VERSION ""

NS_ :

BS_:

BU_: PFAF_HS LVMPC_HS DCDC_HS AMP_HS VICM2_HS FICM_HS ARS_HS MCP_B_HS MCP_A_HS ICCM_OBD_HS SAS_HS ACCM_HS VLBS_HS EBCM_OBD_HS EDI_HS HPCC_HS VITM_OBD_HS PTAM_HS OBCM_HS VICM_HS HCP_HS FDCM_HS APPS_HS ICCM_HS EOCM_F_HS GPCM_HS FSCM_ITBC_HS SCM_HS ITBC_HS VCM_HS HMIM_HS FCP_HS VES_HS Dummy_HS MCP_C_HS RWS_HS ONSTAR_HS EPS_HS TestTool_HS MCP_HS BCP_HS ALC_HS AHL_AFL_HS SADS_HS EPB_HS FSCM_HS AFS_HS FCM_HS TCCM_HS RDCM_HS PTO_HS PCM_HS EBCM_HS ACC_HS BCM_HS TCM_HS ECM_HS

BO_ 1917 DTC_Triggered_77D: 7 EPB_HS
  SG_ DTCI_DTCFaultType_77D: 55|8@0+ (1,0) [0|255] "" HMIM_HS FCP_HS ONSTAR_HS
  SG_ DTCI_CodeSupported_77D: 40|1@0+ (1,0) [0|1] "" HMIM_HS FCP_HS ONSTAR_HS
  SG_ DTCI_CurrentStatus_77D: 41|1@0+ (1,0) [0|1] "" HMIM_HS FCP_HS ONSTAR_HS
  SG_ DTCI_TstNPsdCdClrdSt_77D: 42|1@0+ (1,0) [0|1] "" HMIM_HS FCP_HS ONSTAR_HS
  SG_ DTCI_TstFldCdClrdStat_77D: 43|1@0+ (1,0) [0|1] "" HMIM_HS FCP_HS ONSTAR_HS
  SG_ DTCI_HistStat_77D: 44|1@0+ (1,0) [0|1] "" HMIM_HS FCP_HS ONSTAR_HS
  SG_ DTCI_TstNPsdPwrUpSt_77D: 45|1@0+ (1,0) [0|1] "" HMIM_HS FCP_HS ONSTAR_HS
  SG_ DTCI_TstFldPwrUpSt_77D: 46|1@0+ (1,0) [0|1] "" HMIM_HS FCP_HS ONSTAR_HS
  SG_ DTCI_WrnIndRqdSt_77D: 47|1@0+ (1,0) [0|1] "" HMIM_HS FCP_HS ONSTAR_HS
  SG_ DTCI_DTCFailType_77D: 39|8@0+ (1,0) [0|255] "" HMIM_HS FCP_HS ONSTAR_HS
  SG_ DTCI_DTCNumber_77D: 23|16@0+ (1,0) [0|65535] "" HMIM_HS FCP_HS ONSTAR_HS
  SG_ DTCI_DTCSource_77D: 15|8@0+ (1,0) [0|255] "" HMIM_HS FCP_HS ONSTAR_HS
  SG_ DTCI_DTCTriggered_77D: 0|1@0+ (1,0) [0|1] "" HMIM_HS FCP_HS ONSTAR_HS
  SG_ DTCIUnused7_77D: 1|1@0+ (1,0) [0|1] "" HMIM_HS FCP_HS ONSTAR_HS
  SG_ DTCIUnused6_77D: 2|1@0+ (1,0) [0|1] "" HMIM_HS FCP_HS ONSTAR_HS
  SG_ DTCIUnused5_77D: 3|1@0+ (1,0) [0|1] "" HMIM_HS FCP_HS ONSTAR_HS
  SG_ DTCIUnused4_77D: 4|1@0+ (1,0) [0|1] "" HMIM_HS FCP_HS ONSTAR_HS
  SG_ DTCIUnused3_77D: 5|1@0+ (1,0) [0|1] "" HMIM_HS FCP_HS ONSTAR_HS
  SG_ DTCIUnused2_77D: 6|1@0+ (1,0) [0|1] "" HMIM_HS FCP_HS ONSTAR_HS
  SG_ DTCIUnused1_77D: 7|1@0+ (1,0) [0|1] "" HMIM_HS FCP_HS ONSTAR_HS

BO_ 1918 DTC_Triggered_77E: 7 SADS_HS
  SG_ DTCI_DTCFaultType_77E: 55|8@0+ (1,0) [0|255] "" HMIM_HS FCP_HS ONSTAR_HS
  SG_ DTCI_CodeSupported_77E: 40|1@0+ (1,0) [0|1] "" HMIM_HS FCP_HS ONSTAR_HS
  SG_ DTCI_CurrentStatus_77E: 41|1@0+ (1,0) [0|1] "" HMIM_HS FCP_HS ONSTAR_HS
  SG_ DTCI_TstNPsdCdClrdSt_77E: 42|1@0+ (1,0) [0|1] "" HMIM_HS FCP_HS ONSTAR_HS
  SG_ DTCI_TstFldCdClrdStat_77E: 43|1@0+ (1,0) [0|1] "" HMIM_HS FCP_HS ONSTAR_HS
  SG_ DTCI_HistStat_77E: 44|1@0+ (1,0) [0|1] "" HMIM_HS FCP_HS ONSTAR_HS
  SG_ DTCI_TstNPsdPwrUpSt_77E: 45|1@0+ (1,0) [0|1] "" HMIM_HS FCP_HS ONSTAR_HS
  SG_ DTCI_TstFldPwrUpSt_77E: 46|1@0+ (1,0) [0|1] "" HMIM_HS FCP_HS ONSTAR_HS
  SG_ DTCI_WrnIndRqdSt_77E: 47|1@0+ (1,0) [0|1] "" HMIM_HS FCP_HS ONSTAR_HS
  SG_ DTCI_DTCFailType_77E: 39|8@0+ (1,0) [0|255] "" HMIM_HS FCP_HS ONSTAR_HS
  SG_ DTCI_DTCNumber_77E: 23|16@0+ (1,0) [0|65535] "" HMIM_HS FCP_HS ONSTAR_HS
  SG_ DTCI_DTCSource_77E: 15|8@0+ (1,0) [0|255] "" HMIM_HS FCP_HS ONSTAR_HS
  SG_ DTCI_DTCTriggered_77E: 0|1@0+ (1,0) [0|1] "" HMIM_HS FCP_HS ONSTAR_HS
  SG_ DTCIUnused7_77E: 1|1@0+ (1,0) [0|1] "" HMIM_HS FCP_HS ONSTAR_HS
  SG_ DTCIUnused6_77E: 2|1@0+ (1,0) [0|1] "" HMIM_HS FCP_HS ONSTAR_HS
  SG_ DTCIUnused5_77E: 3|1@0+ (1,0) [0|1] "" HMIM_HS FCP_HS ONSTAR_HS
  SG_ DTCIUnused4_77E: 4|1@0+ (1,0) [0|1] "" HMIM_HS FCP_HS ONSTAR_HS
  SG_ DTCIUnused3_77E: 5|1@0+ (1,0) [0|1] "" HMIM_HS FCP_HS ONSTAR_HS
  SG_ DTCIUnused2_77E: 6|1@0+ (1,0) [0|1] "" HMIM_HS FCP_HS ONSTAR_HS
  SG_ DTCIUnused1_77E: 7|1@0+ (1,0) [0|1] "" HMIM_HS FCP_HS ONSTAR_HS

BO_ 1919 DTC_Triggered_77F: 7 TCM_HS
  SG_ DTCI_DTCFaultType_77F: 55|8@0+ (1,0) [0|255] "" HMIM_HS FCP_HS ONSTAR_HS
  SG_ DTCI_CodeSupported_77F: 40|1@0+ (1,0) [0|1] "" HMIM_HS FCP_HS ONSTAR_HS
  SG_ DTCI_CurrentStatus_77F: 41|1@0+ (1,0) [0|1] "" HMIM_HS FCP_HS ONSTAR_HS
  SG_ DTCI_TstNPsdCdClrdSt_77F: 42|1@0+ (1,0) [0|1] "" HMIM_HS FCP_HS ONSTAR_HS
  SG_ DTCI_TstFldCdClrdStat_77F: 43|1@0+ (1,0) [0|1] "" HMIM_HS FCP_HS ONSTAR_HS
  SG_ DTCI_HistStat_77F: 44|1@0+ (1,0) [0|1] "" HMIM_HS FCP_HS ONSTAR_HS
  SG_ DTCI_TstNPsdPwrUpSt_77F: 45|1@0+ (1,0) [0|1] "" HMIM_HS FCP_HS ONSTAR_HS
  SG_ DTCI_TstFldPwrUpSt_77F: 46|1@0+ (1,0) [0|1] "" HMIM_HS FCP_HS ONSTAR_HS
  SG_ DTCI_WrnIndRqdSt_77F: 47|1@0+ (1,0) [0|1] "" HMIM_HS FCP_HS ONSTAR_HS
  SG_ DTCI_DTCFailType_77F: 39|8@0+ (1,0) [0|255] "" HMIM_HS FCP_HS ONSTAR_HS
  SG_ DTCI_DTCNumber_77F: 23|16@0+ (1,0) [0|65535] "" HMIM_HS FCP_HS ONSTAR_HS
  SG_ DTCI_DTCSource_77F: 15|8@0+ (1,0) [0|255] "" HMIM_HS FCP_HS ONSTAR_HS
  SG_ DTCI_DTCTriggered_77F: 0|1@0+ (1,0) [0|1] "" HMIM_HS FCP_HS ONSTAR_HS
  SG_ DTCIUnused7_77F: 1|1@0+ (1,0) [0|1] "" HMIM_HS FCP_HS ONSTAR_HS
  SG_ DTCIUnused6_77F: 2|1@0+ (1,0) [0|1] "" HMIM_HS FCP_HS ONSTAR_HS
  SG_ DTCIUnused5_77F: 3|1@0+ (1,0) [0|1] "" HMIM_HS FCP_HS ONSTAR_HS
  SG_ DTCIUnused4_77F: 4|1@0+ (1,0) [0|1] "" HMIM_HS FCP_HS ONSTAR_HS
  SG_ DTCIUnused3_77F: 5|1@0+ (1,0) [0|1] "" HMIM_HS FCP_HS ONSTAR_HS
  SG_ DTCIUnused2_77F: 6|1@0+ (1,0) [0|1] "" HMIM_HS FCP_HS ONSTAR_HS
  SG_ DTCIUnused1_77F: 7|1@0+ (1,0) [0|1] "" HMIM_HS FCP_HS ONSTAR_HS

BO_ 589 USDT_Req_to_ONS_HS: 8 TestTool_HS
  SG_ DgnInf: 7|64@0+ (1,0) [0|1.8446742e+19] "" FCP_HS ONSTAR_HS

BO_ 1357 UUDT_Resp_From_ONS_HS: 8 ONSTAR_HS
  SG_ DgnInf_HS54D: 7|64@0+ (1,0) [0|1.8446742e+19] "" TestTool_HS

BO_ 1613 USDT_Resp_From_ONS_HS: 8 ONSTAR_HS
  SG_ DgnInf: 7|64@0+ (1,0) [0|1.8446742e+19] "" TestTool_HS

BO_ 1606 USDT_Resp_From_APPS_HS: 8 APPS_HS
  SG_ DgnInf: 7|64@0+ (1,0) [0|1.8446742e+19] "" FCP_HS ONSTAR_HS TestTool_HS

BO_ 582 USDT_Req_to_APPS_HS: 8 TestTool_HS
  SG_ DgnInf: 7|64@0+ (1,0) [0|1.8446742e+19] "" APPS_HS

BO_ 590 USDT_Req_to_SADS_HS: 8 TestTool_HS
  SG_ DgnInf: 7|64@0+ (1,0) [0|1.8446742e+19] "" SADS_HS

BO_ 601 USDT_Req_to_MCP_C_HS: 8 TestTool_HS
  SG_ DgnInf: 7|64@0+ (1,0) [0|1.8446742e+19] "" MCP_C_HS

BO_ 1369 UUDT_Resp_From_MCP_C_HS: 8 MCP_C_HS
  SG_ DgnInf_HS559: 7|64@0+ (1,0) [0|1.8446742e+19] "" FCP_HS ONSTAR_HS TestTool_HS

BO_ 1625 USDT_Resp_From_MCP_C_HS: 8 MCP_C_HS
  SG_ DgnInf: 7|64@0+ (1,0) [0|1.8446742e+19] "" FCP_HS ONSTAR_HS TestTool_HS

BO_ 1356 UUDT_Resp_From_PFAF_HS: 8 PFAF_HS
  SG_ DgnInf_HS54C: 7|64@0+ (1,0) [0|1.8446742e+19] "" FCP_HS ONSTAR_HS TestTool_HS

BO_ 1358 UUDT_Resp_From_SADS_HS: 8 SADS_HS
  SG_ DgnInf_HS54E: 7|64@0+ (1,0) [0|1.8446742e+19] "" FCP_HS ONSTAR_HS TestTool_HS

BO_ 1359 UUDT_Resp_From_RDCM_HS: 8 RDCM_HS
  SG_ DgnInf_HS54F: 7|64@0+ (1,0) [0|1.8446742e+19] "" FCP_HS ONSTAR_HS TestTool_HS

BO_ 2023 USDT_Req_to_VITM_HS: 8 TestTool_HS
  SG_ DgnInf: 7|64@0+ (1,0) [0|1.8446742e+19] "" VITM_OBD_HS

BO_ 2021 USDT_Req_to_OBD_Device5: 8 TestTool_HS
  SG_ DgnInf: 7|64@0+ (1,0) [0|1.8446742e+19] "" EBCM_OBD_HS

BO_ 2017 USDT_Req_to_BCP_HS: 8 TestTool_HS
  SG_ DgnInf: 7|64@0+ (1,0) [0|1.8446742e+19] "" HCP_HS BCP_HS

BO_ 2019 USDT_Req_to_FSCM_HS: 8 TestTool_HS
  SG_ DgnInf: 7|64@0+ (1,0) [0|1.8446742e+19] "" ICCM_OBD_HS FSCM_ITBC_HS FSCM_HS

BO_ 585 USDT_Req_to_AFL_AHL_HS: 8 TestTool_HS
  SG_ DgnInf: 7|64@0+ (1,0) [0|1.8446742e+19] "" AHL_AFL_HS

BO_ 578 USDT_Req_to_EHPS_EPS_HS: 8 TestTool_HS
  SG_ DgnInf: 7|64@0+ (1,0) [0|1.8446742e+19] "" VES_HS EPS_HS

BO_ 2022 USDT_Req_to_OBD_Device6: 8 TestTool_HS
  SG_ DgnInf: 7|64@0+ (1,0) [0|1.8446742e+19] "" FICM_HS GPCM_HS VICM2_HS

BO_ 584 USDT_Req_to_Free_48_HS: 8 TestTool_HS
  SG_ DgnInf: 7|64@0+ (1,0) [0|1.8446742e+19] "" Dummy_HS

BO_ 591 USDT_Req_to_RDCM_HS: 8 TestTool_HS
  SG_ DgnInf: 7|64@0+ (1,0) [0|1.8446742e+19] "" RDCM_HS

BO_ 581 USDT_Req_to_ALC_HS: 8 TestTool_HS
  SG_ DgnInf: 7|64@0+ (1,0) [0|1.8446742e+19] "" ALC_HS

BO_ 586 USDT_Req_to_SAS_HS: 8 TestTool_HS
  SG_ DgnInf: 7|64@0+ (1,0) [0|1.8446742e+19] "" SAS_HS

BO_ 588 USDT_Req_to_PFAF_HS: 8 TestTool_HS
  SG_ DgnInf: 7|64@0+ (1,0) [0|1.8446742e+19] "" PFAF_HS

BO_ 580 USDT_Req_to_OBCM_HS: 8 TestTool_HS
  SG_ DgnInf: 7|64@0+ (1,0) [0|1.8446742e+19] "" DCDC_HS OBCM_HS

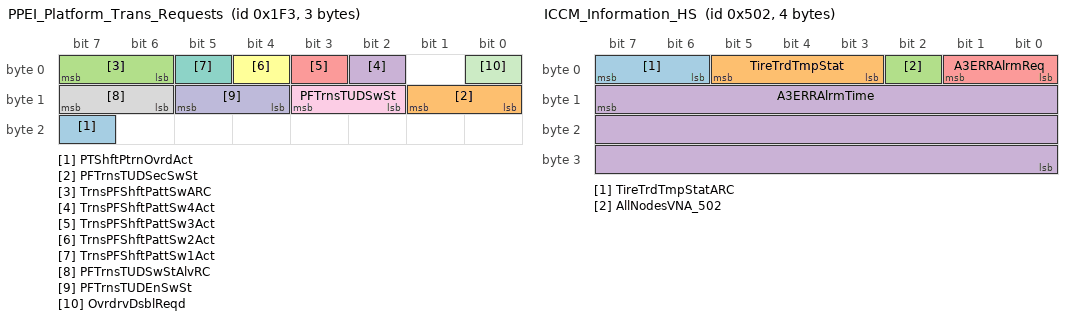
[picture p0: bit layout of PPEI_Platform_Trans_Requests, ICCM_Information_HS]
BO_ 499 PPEI_Platform_Trans_Requests: 3 BCM_HS
  SG_ PTShftPtrnOvrdAct: 23|1@0+ (1,0) [0|1] "" TCM_HS
  SG_ PFTrnsTUDSecSwSt: 9|2@0+ (1,0) [0|3] "" TCM_HS
  SG_ TrnsPFShftPattSwARC: 7|2@0+ (1,0) [0|3] "" PCM_HS ECM_HS TCM_HS
  SG_ TrnsPFShftPattSw4Act: 2|1@0+ (1,0) [0|1] "" PCM_HS ECM_HS TCM_HS
  SG_ TrnsPFShftPattSw3Act: 3|1@0+ (1,0) [0|1] "" PCM_HS ECM_HS TCM_HS
  SG_ TrnsPFShftPattSw2Act: 4|1@0+ (1,0) [0|1] "" PCM_HS ECM_HS TCM_HS
  SG_ TrnsPFShftPattSw1Act: 5|1@0+ (1,0) [0|1] "" PCM_HS ECM_HS TCM_HS
  SG_ PFTrnsTUDSwStAlvRC: 15|2@0+ (1,0) [0|3] "" TCM_HS
  SG_ PFTrnsTUDSwSt: 11|2@0+ (1,0) [0|3] "" TCM_HS
  SG_ PFTrnsTUDEnSwSt: 13|2@0+ (1,0) [0|3] "" TCM_HS
  SG_ OvrdrvDsblReqd: 0|1@0+ (1,0) [0|1] "" Vector__XXX

BO_ 1282 ICCM_Information_HS: 4 ALC_HS
  SG_ TireTrdTmpStatARC: 7|2@0+ (1,0) [0|3] "" EBCM_OBD_HS EBCM_HS
  SG_ TireTrdTmpStat: 5|3@0+ (1,0) [0|7] "" BCM_HS EBCM_OBD_HS EBCM_HS
  SG_ AllNodesVNA_502: 2|1@0+ (1,0) [0|1] "" BCM_HS
  SG_ A3ERRAlrmTime: 15|24@0+ (1,0) [0|16777215] "min" BCM_HS
  SG_ A3ERRAlrmReq: 1|2@0+ (1,0) [0|3] "" BCM_HS

BO_ 1360 UUDT_Resp_From_PTAM_HS: 8 PTAM_HS
  SG_ DgnInf_HS550: 7|64@0+ (1,0) [0|1.8446742e+19] "" FCP_HS ONSTAR_HS TestTool_HS

BO_ 1616 USDT_Resp_From_PTAM_HS: 8 PTAM_HS
  SG_ DgnInf: 7|64@0+ (1,0) [0|1.8446742e+19] "" FCP_HS ONSTAR_HS TestTool_HS

BO_ 1921 DTC_Triggered_781: 7 Dummy_HS
  SG_ DTCI_CurrentStatus_781: 41|1@0+ (1,0) [0|1] "" HMIM_HS FCP_HS ONSTAR_HS
  SG_ DTCI_WrnIndRqdSt_781: 47|1@0+ (1,0) [0|1] "" HMIM_HS FCP_HS ONSTAR_HS
  SG_ DTCIUnused7_781: 1|1@0+ (1,0) [0|1] "" HMIM_HS FCP_HS ONSTAR_HS
  SG_ DTCIUnused6_781: 2|1@0+ (1,0) [0|1] "" HMIM_HS FCP_HS ONSTAR_HS
  SG_ DTCIUnused5_781: 3|1@0+ (1,0) [0|1] "" HMIM_HS FCP_HS ONSTAR_HS
  SG_ DTCIUnused4_781: 4|1@0+ (1,0) [0|1] "" HMIM_HS FCP_HS ONSTAR_HS
  SG_ DTCIUnused3_781: 5|1@0+ (1,0) [0|1] "" HMIM_HS FCP_HS ONSTAR_HS
  SG_ DTCIUnused2_781: 6|1@0+ (1,0) [0|1] "" HMIM_HS FCP_HS ONSTAR_HS
  SG_ DTCIUnused1_781: 7|1@0+ (1,0) [0|1] "" HMIM_HS FCP_HS ONSTAR_HS
  SG_ DTCI_TstNPsdPwrUpSt_781: 45|1@0+ (1,0) [0|1] "" HMIM_HS FCP_HS ONSTAR_HS
  SG_ DTCI_TstNPsdCdClrdSt_781: 42|1@0+ (1,0) [0|1] "" HMIM_HS FCP_HS ONSTAR_HS
  SG_ DTCI_TstFldPwrUpSt_781: 46|1@0+ (1,0) [0|1] "" HMIM_HS FCP_HS ONSTAR_HS
  SG_ DTCI_TstFldCdClrdStat_781: 43|1@0+ (1,0) [0|1] "" HMIM_HS FCP_HS ONSTAR_HS
  SG_ DTCI_HistStat_781: 44|1@0+ (1,0) [0|1] "" HMIM_HS FCP_HS ONSTAR_HS
  SG_ DTCI_DTCTriggered_781: 0|1@0+ (1,0) [0|1] "" HMIM_HS FCP_HS ONSTAR_HS
  SG_ DTCI_DTCSource_781: 15|8@0+ (1,0) [0|255] "" HMIM_HS FCP_HS ONSTAR_HS
  SG_ DTCI_DTCNumber_781: 23|16@0+ (1,0) [0|65535] "" HMIM_HS FCP_HS ONSTAR_HS
  SG_ DTCI_DTCFaultType_781: 55|8@0+ (1,0) [0|255] "" HMIM_HS FCP_HS ONSTAR_HS
  SG_ DTCI_DTCFailType_781: 39|8@0+ (1,0) [0|255] "" HMIM_HS FCP_HS ONSTAR_HS
  SG_ DTCI_CodeSupported_781: 40|1@0+ (1,0) [0|1] "" HMIM_HS FCP_HS ONSTAR_HS

BO_ 1920 DTC_Triggered_780: 7 EBCM_HS
  SG_ DTCI_CurrentStatus_780: 41|1@0+ (1,0) [0|1] "" HMIM_HS FCP_HS ONSTAR_HS
  SG_ DTCI_WrnIndRqdSt_780: 47|1@0+ (1,0) [0|1] "" HMIM_HS FCP_HS ONSTAR_HS
  SG_ DTCIUnused7_780: 1|1@0+ (1,0) [0|1] "" HMIM_HS FCP_HS ONSTAR_HS
  SG_ DTCIUnused6_780: 2|1@0+ (1,0) [0|1] "" HMIM_HS FCP_HS ONSTAR_HS
  SG_ DTCIUnused5_780: 3|1@0+ (1,0) [0|1] "" HMIM_HS FCP_HS ONSTAR_HS
  SG_ DTCIUnused4_780: 4|1@0+ (1,0) [0|1] "" HMIM_HS FCP_HS ONSTAR_HS
  SG_ DTCIUnused3_780: 5|1@0+ (1,0) [0|1] "" HMIM_HS FCP_HS ONSTAR_HS
  SG_ DTCIUnused2_780: 6|1@0+ (1,0) [0|1] "" HMIM_HS FCP_HS ONSTAR_HS
  SG_ DTCIUnused1_780: 7|1@0+ (1,0) [0|1] "" HMIM_HS FCP_HS ONSTAR_HS
  SG_ DTCI_TstNPsdPwrUpSt_780: 45|1@0+ (1,0) [0|1] "" HMIM_HS FCP_HS ONSTAR_HS
  SG_ DTCI_TstNPsdCdClrdSt_780: 42|1@0+ (1,0) [0|1] "" HMIM_HS FCP_HS ONSTAR_HS
  SG_ DTCI_TstFldPwrUpSt_780: 46|1@0+ (1,0) [0|1] "" HMIM_HS FCP_HS ONSTAR_HS
  SG_ DTCI_TstFldCdClrdStat_780: 43|1@0+ (1,0) [0|1] "" HMIM_HS FCP_HS ONSTAR_HS
  SG_ DTCI_HistStat_780: 44|1@0+ (1,0) [0|1] "" HMIM_HS FCP_HS ONSTAR_HS
  SG_ DTCI_DTCTriggered_780: 0|1@0+ (1,0) [0|1] "" HMIM_HS FCP_HS ONSTAR_HS
  SG_ DTCI_DTCSource_780: 15|8@0+ (1,0) [0|255] "" HMIM_HS FCP_HS ONSTAR_HS
  SG_ DTCI_DTCNumber_780: 23|16@0+ (1,0) [0|65535] "" HMIM_HS FCP_HS ONSTAR_HS
  SG_ DTCI_DTCFaultType_780: 55|8@0+ (1,0) [0|255] "" HMIM_HS FCP_HS ONSTAR_HS
  SG_ DTCI_DTCFailType_780: 39|8@0+ (1,0) [0|255] "" HMIM_HS FCP_HS ONSTAR_HS
  SG_ DTCI_CodeSupported_780: 40|1@0+ (1,0) [0|1] "" HMIM_HS FCP_HS ONSTAR_HS

BO_ 596 USDT_Req_to_EPB_HS: 8 TestTool_HS
  SG_ DgnInf: 7|64@0+ (1,0) [0|1.8446742e+19] "" EPB_HS

BO_ 2033 PCU_Req_to_SDM_HS: 8 TestTool_HS
  SG_ PCUInfo: 7|64@0+ (1,0) [0|1.8446742e+19] "" BCM_HS

BO_ 495 PPEI_Fuel_System_Request_2: 4 ECM_HS
  SG_ MassAirFloV: 7|1@0+ (1,0) [0|1] "" VICM_HS
  SG_ MassAirFlo: 23|16@0+ (0.010000001,0) [0|655.34998] "grams/s" VICM_HS

BO_ 1350 UUDT_Resp_From_APPS_HS: 8 APPS_HS
  SG_ DgnInf_HS546: 7|64@0+ (1,0) [0|1.8446742e+19] "" FCP_HS ONSTAR_HS TestTool_HS

BO_ 1914 DTC_Triggered_77A: 7 RDCM_HS
  SG_ DTCI_DTCFaultType_77A: 55|8@0+ (1,0) [0|255] "" HMIM_HS FCP_HS ONSTAR_HS
  SG_ DTCI_CodeSupported_77A: 40|1@0+ (1,0) [0|1] "" HMIM_HS FCP_HS ONSTAR_HS
  SG_ DTCI_CurrentStatus_77A: 41|1@0+ (1,0) [0|1] "" HMIM_HS FCP_HS ONSTAR_HS
  SG_ DTCI_TstNPsdCdClrdSt_77A: 42|1@0+ (1,0) [0|1] "" HMIM_HS FCP_HS ONSTAR_HS
  SG_ DTCI_TstFldCdClrdStat_77A: 43|1@0+ (1,0) [0|1] "" HMIM_HS FCP_HS ONSTAR_HS
  SG_ DTCI_HistStat_77A: 44|1@0+ (1,0) [0|1] "" HMIM_HS FCP_HS ONSTAR_HS
  SG_ DTCI_TstNPsdPwrUpSt_77A: 45|1@0+ (1,0) [0|1] "" HMIM_HS FCP_HS ONSTAR_HS
  SG_ DTCI_TstFldPwrUpSt_77A: 46|1@0+ (1,0) [0|1] "" HMIM_HS FCP_HS ONSTAR_HS
  SG_ DTCI_WrnIndRqdSt_77A: 47|1@0+ (1,0) [0|1] "" HMIM_HS FCP_HS ONSTAR_HS
  SG_ DTCI_DTCFailType_77A: 39|8@0+ (1,0) [0|255] "" HMIM_HS FCP_HS ONSTAR_HS
  SG_ DTCI_DTCNumber_77A: 23|16@0+ (1,0) [0|65535] "" HMIM_HS FCP_HS ONSTAR_HS
  SG_ DTCI_DTCSource_77A: 15|8@0+ (1,0) [0|255] "" HMIM_HS FCP_HS ONSTAR_HS
  SG_ DTCI_DTCTriggered_77A: 0|1@0+ (1,0) [0|1] "" HMIM_HS FCP_HS ONSTAR_HS
  SG_ DTCIUnused7_77A: 1|1@0+ (1,0) [0|1] "" HMIM_HS FCP_HS ONSTAR_HS
  SG_ DTCIUnused6_77A: 2|1@0+ (1,0) [0|1] "" HMIM_HS FCP_HS ONSTAR_HS
  SG_ DTCIUnused5_77A: 3|1@0+ (1,0) [0|1] "" HMIM_HS FCP_HS ONSTAR_HS
  SG_ DTCIUnused4_77A: 4|1@0+ (1,0) [0|1] "" HMIM_HS FCP_HS ONSTAR_HS
  SG_ DTCIUnused3_77A: 5|1@0+ (1,0) [0|1] "" HMIM_HS FCP_HS ONSTAR_HS
  SG_ DTCIUnused2_77A: 6|1@0+ (1,0) [0|1] "" HMIM_HS FCP_HS ONSTAR_HS
  SG_ DTCIUnused1_77A: 7|1@0+ (1,0) [0|1] "" HMIM_HS FCP_HS ONSTAR_HS

BO_ 1911 DTC_Triggered_777: 7 PTO_HS
  SG_ DTCI_DTCFaultType_777: 55|8@0+ (1,0) [0|255] "" HMIM_HS FCP_HS ONSTAR_HS
  SG_ DTCI_CodeSupported_777: 40|1@0+ (1,0) [0|1] "" HMIM_HS FCP_HS ONSTAR_HS
  SG_ DTCI_CurrentStatus_777: 41|1@0+ (1,0) [0|1] "" HMIM_HS FCP_HS ONSTAR_HS
  SG_ DTCI_TstNPsdCdClrdSt_777: 42|1@0+ (1,0) [0|1] "" HMIM_HS FCP_HS ONSTAR_HS
  SG_ DTCI_TstFldCdClrdStat_777: 43|1@0+ (1,0) [0|1] "" HMIM_HS FCP_HS ONSTAR_HS
  SG_ DTCI_HistStat_777: 44|1@0+ (1,0) [0|1] "" HMIM_HS FCP_HS ONSTAR_HS
  SG_ DTCI_TstNPsdPwrUpSt_777: 45|1@0+ (1,0) [0|1] "" HMIM_HS FCP_HS ONSTAR_HS
  SG_ DTCI_TstFldPwrUpSt_777: 46|1@0+ (1,0) [0|1] "" HMIM_HS FCP_HS ONSTAR_HS
  SG_ DTCI_WrnIndRqdSt_777: 47|1@0+ (1,0) [0|1] "" HMIM_HS FCP_HS ONSTAR_HS
  SG_ DTCI_DTCFailType_777: 39|8@0+ (1,0) [0|255] "" HMIM_HS FCP_HS ONSTAR_HS
  SG_ DTCI_DTCNumber_777: 23|16@0+ (1,0) [0|65535] "" HMIM_HS FCP_HS ONSTAR_HS
  SG_ DTCI_DTCSource_777: 15|8@0+ (1,0) [0|255] "" HMIM_HS FCP_HS ONSTAR_HS
  SG_ DTCI_DTCTriggered_777: 0|1@0+ (1,0) [0|1] "" HMIM_HS FCP_HS ONSTAR_HS
  SG_ DTCIUnused7_777: 1|1@0+ (1,0) [0|1] "" HMIM_HS FCP_HS ONSTAR_HS
  SG_ DTCIUnused6_777: 2|1@0+ (1,0) [0|1] "" HMIM_HS FCP_HS ONSTAR_HS
  SG_ DTCIUnused5_777: 3|1@0+ (1,0) [0|1] "" HMIM_HS FCP_HS ONSTAR_HS
  SG_ DTCIUnused4_777: 4|1@0+ (1,0) [0|1] "" HMIM_HS FCP_HS ONSTAR_HS
  SG_ DTCIUnused3_777: 5|1@0+ (1,0) [0|1] "" HMIM_HS FCP_HS ONSTAR_HS
  SG_ DTCIUnused2_777: 6|1@0+ (1,0) [0|1] "" HMIM_HS FCP_HS ONSTAR_HS
  SG_ DTCIUnused1_777: 7|1@0+ (1,0) [0|1] "" HMIM_HS FCP_HS ONSTAR_HS

BO_ 583 USDT_Req_to_PTO_HS: 8 TestTool_HS
  SG_ DgnInf: 7|64@0+ (1,0) [0|1.8446742e+19] "" PTO_HS

BO_ 1351 UUDT_Resp_From_PTO: 8 PTO_HS
  SG_ DgnInf_HS547: 7|64@0+ (1,0) [0|1.8446742e+19] "" FCP_HS ONSTAR_HS TestTool_HS

BO_ 1607 USDT_Resp_From_PTO_HS: 8 PTO_HS
  SG_ DgnInf: 7|64@0+ (1,0) [0|1.8446742e+19] "" FCP_HS ONSTAR_HS TestTool_HS

BO_ 1906 DTC_Triggered_772: 7 ECM_HS
  SG_ DTCI_DTCFaultType_772: 55|8@0+ (1,0) [0|255] "" HMIM_HS FCP_HS ONSTAR_HS
  SG_ DTCI_CodeSupported_772: 40|1@0+ (1,0) [0|1] "" HMIM_HS FCP_HS ONSTAR_HS
  SG_ DTCI_CurrentStatus_772: 41|1@0+ (1,0) [0|1] "" HMIM_HS FCP_HS ONSTAR_HS
  SG_ DTCI_TstNPsdCdClrdSt_772: 42|1@0+ (1,0) [0|1] "" HMIM_HS FCP_HS ONSTAR_HS
  SG_ DTCI_TstFldCdClrdStat_772: 43|1@0+ (1,0) [0|1] "" HMIM_HS FCP_HS ONSTAR_HS
  SG_ DTCI_HistStat_772: 44|1@0+ (1,0) [0|1] "" HMIM_HS FCP_HS ONSTAR_HS
  SG_ DTCI_TstNPsdPwrUpSt_772: 45|1@0+ (1,0) [0|1] "" HMIM_HS FCP_HS ONSTAR_HS
  SG_ DTCI_TstFldPwrUpSt_772: 46|1@0+ (1,0) [0|1] "" HMIM_HS FCP_HS ONSTAR_HS
  SG_ DTCI_WrnIndRqdSt_772: 47|1@0+ (1,0) [0|1] "" HMIM_HS FCP_HS ONSTAR_HS
  SG_ DTCI_DTCFailType_772: 39|8@0+ (1,0) [0|255] "" HMIM_HS FCP_HS ONSTAR_HS
  SG_ DTCI_DTCNumber_772: 23|16@0+ (1,0) [0|65535] "" HMIM_HS FCP_HS ONSTAR_HS
  SG_ DTCI_DTCSource_772: 15|8@0+ (1,0) [0|255] "" HMIM_HS FCP_HS ONSTAR_HS
  SG_ DTCI_DTCTriggered_772: 0|1@0+ (1,0) [0|1] "" HMIM_HS FCP_HS ONSTAR_HS
  SG_ DTCIUnused7_772: 1|1@0+ (1,0) [0|1] "" HMIM_HS FCP_HS ONSTAR_HS
  SG_ DTCIUnused6_772: 2|1@0+ (1,0) [0|1] "" HMIM_HS FCP_HS ONSTAR_HS
  SG_ DTCIUnused5_772: 3|1@0+ (1,0) [0|1] "" HMIM_HS FCP_HS ONSTAR_HS
  SG_ DTCIUnused4_772: 4|1@0+ (1,0) [0|1] "" HMIM_HS FCP_HS ONSTAR_HS
  SG_ DTCIUnused3_772: 5|1@0+ (1,0) [0|1] "" HMIM_HS FCP_HS ONSTAR_HS
  SG_ DTCIUnused2_772: 6|1@0+ (1,0) [0|1] "" HMIM_HS FCP_HS ONSTAR_HS
  SG_ DTCIUnused1_772: 7|1@0+ (1,0) [0|1] "" HMIM_HS FCP_HS ONSTAR_HS

BO_ 1907 DTC_Triggered_773: 7 EBCM_HS
  SG_ DTCI_DTCFaultType_773: 55|8@0+ (1,0) [0|255] "" HMIM_HS FCP_HS ONSTAR_HS
  SG_ DTCI_CodeSupported_773: 40|1@0+ (1,0) [0|1] "" HMIM_HS FCP_HS ONSTAR_HS
  SG_ DTCI_CurrentStatus_773: 41|1@0+ (1,0) [0|1] "" HMIM_HS FCP_HS ONSTAR_HS
  SG_ DTCI_TstNPsdCdClrdSt_773: 42|1@0+ (1,0) [0|1] "" HMIM_HS FCP_HS ONSTAR_HS
  SG_ DTCI_TstFldCdClrdStat_773: 43|1@0+ (1,0) [0|1] "" HMIM_HS FCP_HS ONSTAR_HS
  SG_ DTCI_HistStat_773: 44|1@0+ (1,0) [0|1] "" HMIM_HS FCP_HS ONSTAR_HS
  SG_ DTCI_TstNPsdPwrUpSt_773: 45|1@0+ (1,0) [0|1] "" HMIM_HS FCP_HS ONSTAR_HS
  SG_ DTCI_TstFldPwrUpSt_773: 46|1@0+ (1,0) [0|1] "" HMIM_HS FCP_HS ONSTAR_HS
  SG_ DTCI_WrnIndRqdSt_773: 47|1@0+ (1,0) [0|1] "" HMIM_HS FCP_HS ONSTAR_HS
  SG_ DTCI_DTCFailType_773: 39|8@0+ (1,0) [0|255] "" HMIM_HS FCP_HS ONSTAR_HS
  SG_ DTCI_DTCNumber_773: 23|16@0+ (1,0) [0|65535] "" HMIM_HS FCP_HS ONSTAR_HS
  SG_ DTCI_DTCSource_773: 15|8@0+ (1,0) [0|255] "" HMIM_HS FCP_HS ONSTAR_HS
  SG_ DTCI_DTCTriggered_773: 0|1@0+ (1,0) [0|1] "" HMIM_HS FCP_HS ONSTAR_HS
  SG_ DTCIUnused7_773: 1|1@0+ (1,0) [0|1] "" HMIM_HS FCP_HS ONSTAR_HS
  SG_ DTCIUnused6_773: 2|1@0+ (1,0) [0|1] "" HMIM_HS FCP_HS ONSTAR_HS
  SG_ DTCIUnused5_773: 3|1@0+ (1,0) [0|1] "" HMIM_HS FCP_HS ONSTAR_HS
  SG_ DTCIUnused4_773: 4|1@0+ (1,0) [0|1] "" HMIM_HS FCP_HS ONSTAR_HS
  SG_ DTCIUnused3_773: 5|1@0+ (1,0) [0|1] "" HMIM_HS FCP_HS ONSTAR_HS
  SG_ DTCIUnused2_773: 6|1@0+ (1,0) [0|1] "" HMIM_HS FCP_HS ONSTAR_HS
  SG_ DTCIUnused1_773: 7|1@0+ (1,0) [0|1] "" HMIM_HS FCP_HS ONSTAR_HS

BO_ 579 USDT_Req_to_EBCM_HPCC_HS: 8 TestTool_HS
  SG_ DgnInf: 7|64@0+ (1,0) [0|1.8446742e+19] "" HPCC_HS EBCM_HS

BO_ 1603 USDT_Resp_From_EBCM_HPCC_HS: 8 EBCM_HS
  SG_ DgnInf: 7|64@0+ (1,0) [0|1.8446742e+19] "" FCP_HS ONSTAR_HS TestTool_HS

BO_ 1347 UUDT_Resp_From_EBCM_HPCC_HS: 8 EBCM_HS
  SG_ DgnInf_HS543: 7|64@0+ (1,0) [0|1.8446742e+19] "" FCP_HS ONSTAR_HS TestTool_HS

BO_ 1915 DTC_Triggered_77B: 7 ACC_HS
  SG_ DTCI_DTCFaultType_77B: 55|8@0+ (1,0) [0|255] "" HMIM_HS FCP_HS ONSTAR_HS
  SG_ DTCI_CodeSupported_77B: 40|1@0+ (1,0) [0|1] "" HMIM_HS FCP_HS ONSTAR_HS
  SG_ DTCI_CurrentStatus_77B: 41|1@0+ (1,0) [0|1] "" HMIM_HS FCP_HS ONSTAR_HS
  SG_ DTCI_TstNPsdCdClrdSt_77B: 42|1@0+ (1,0) [0|1] "" HMIM_HS FCP_HS ONSTAR_HS
  SG_ DTCI_TstFldCdClrdStat_77B: 43|1@0+ (1,0) [0|1] "" HMIM_HS FCP_HS ONSTAR_HS
  SG_ DTCI_HistStat_77B: 44|1@0+ (1,0) [0|1] "" HMIM_HS FCP_HS ONSTAR_HS
  SG_ DTCI_TstNPsdPwrUpSt_77B: 45|1@0+ (1,0) [0|1] "" HMIM_HS FCP_HS ONSTAR_HS
  SG_ DTCI_TstFldPwrUpSt_77B: 46|1@0+ (1,0) [0|1] "" HMIM_HS FCP_HS ONSTAR_HS
  SG_ DTCI_WrnIndRqdSt_77B: 47|1@0+ (1,0) [0|1] "" HMIM_HS FCP_HS ONSTAR_HS
  SG_ DTCI_DTCFailType_77B: 39|8@0+ (1,0) [0|255] "" HMIM_HS FCP_HS ONSTAR_HS
  SG_ DTCI_DTCNumber_77B: 23|16@0+ (1,0) [0|65535] "" HMIM_HS FCP_HS ONSTAR_HS
  SG_ DTCI_DTCSource_77B: 15|8@0+ (1,0) [0|255] "" HMIM_HS FCP_HS ONSTAR_HS
  SG_ DTCI_DTCTriggered_77B: 0|1@0+ (1,0) [0|1] "" HMIM_HS FCP_HS ONSTAR_HS
  SG_ DTCIUnused7_77B: 1|1@0+ (1,0) [0|1] "" HMIM_HS FCP_HS ONSTAR_HS
  SG_ DTCIUnused6_77B: 2|1@0+ (1,0) [0|1] "" HMIM_HS FCP_HS ONSTAR_HS
  SG_ DTCIUnused5_77B: 3|1@0+ (1,0) [0|1] "" HMIM_HS FCP_HS ONSTAR_HS
  SG_ DTCIUnused4_77B: 4|1@0+ (1,0) [0|1] "" HMIM_HS FCP_HS ONSTAR_HS
  SG_ DTCIUnused3_77B: 5|1@0+ (1,0) [0|1] "" HMIM_HS FCP_HS ONSTAR_HS
  SG_ DTCIUnused2_77B: 6|1@0+ (1,0) [0|1] "" HMIM_HS FCP_HS ONSTAR_HS
  SG_ DTCIUnused1_77B: 7|1@0+ (1,0) [0|1] "" HMIM_HS FCP_HS ONSTAR_HS

BO_ 587 USDT_Req_to_EOCM_FCM_HS: 8 TestTool_HS
  SG_ DgnInf: 7|64@0+ (1,0) [0|1.8446742e+19] "" EOCM_F_HS FCM_HS

BO_ 1611 USDT_Resp_From_EOCM_FCM_HS: 8 FCM_HS
  SG_ DgnInf: 7|64@0+ (1,0) [0|1.8446742e+19] "" FCP_HS ONSTAR_HS TestTool_HS

BO_ 1355 UUDT_Resp_From_EOCM_FCM_HS: 8 FCM_HS
  SG_ DgnInf_HS54B: 7|64@0+ (1,0) [0|1.8446742e+19] "" FCP_HS ONSTAR_HS TestTool_HS

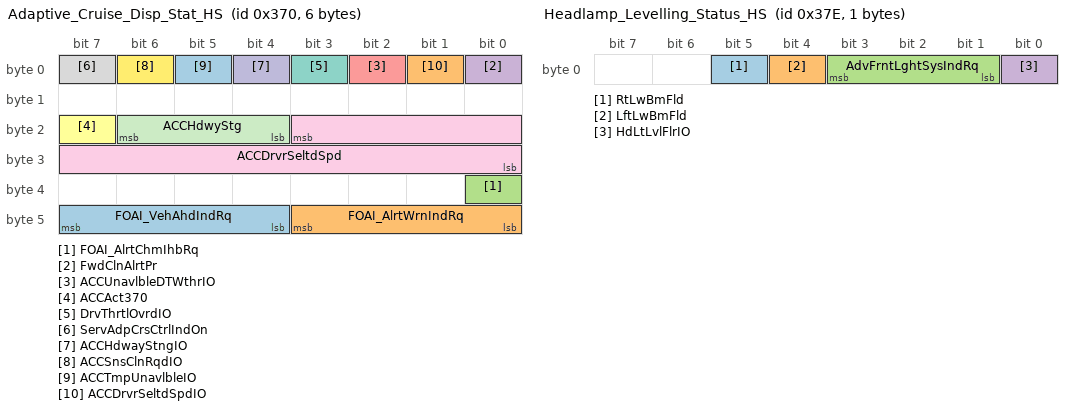
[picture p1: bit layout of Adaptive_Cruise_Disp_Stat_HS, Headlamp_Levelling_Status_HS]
BO_ 880 Adaptive_Cruise_Disp_Stat_HS: 6 ACC_HS
  SG_ FOAI_VehAhdIndRq: 47|4@0+ (1,0) [0|15] "" BCM_HS
  SG_ FOAI_AlrtWrnIndRq: 43|4@0+ (1,0) [0|15] "" BCM_HS
  SG_ FOAI_AlrtChmIhbRq: 32|1@0+ (1,0) [0|1] "" BCM_HS
  SG_ FwdClnAlrtPr: 0|1@0+ (1,0) [0|1] "" BCM_HS
  SG_ ACCUnavlbleDTWthrIO: 2|1@0+ (1,0) [0|1] "" BCM_HS
  SG_ ACCAct370: 23|1@0+ (1,0) [0|1] "" EBCM_OBD_HS EBCM_HS TCM_HS BCM_HS
  SG_ DrvThrtlOvrdIO: 3|1@0+ (1,0) [0|1] "" BCM_HS
  SG_ ServAdpCrsCtrlIndOn: 7|1@0+ (1,0) [0|1] "" BCM_HS
  SG_ ACCDrvrSeltdSpd: 19|12@0+ (0.0625,0) [0|255.9375] "km / h" ECM_HS BCM_HS
  SG_ ACCHdwayStngIO: 4|1@0+ (1,0) [0|1] "" BCM_HS
  SG_ ACCHdwyStg: 22|3@0+ (1,0) [0|7] "" BCM_HS
  SG_ ACCSnsClnRqdIO: 6|1@0+ (1,0) [0|1] "" BCM_HS
  SG_ ACCTmpUnavlbleIO: 5|1@0+ (1,0) [0|1] "" BCM_HS
  SG_ ACCDrvrSeltdSpdIO: 1|1@0+ (1,0) [0|1] "" BCM_HS

BO_ 894 Headlamp_Levelling_Status_HS: 1 AHL_AFL_HS
  SG_ RtLwBmFld: 5|1@0+ (1,0) [0|1] "" EOCM_F_HS BCM_HS
  SG_ LftLwBmFld: 4|1@0+ (1,0) [0|1] "" EOCM_F_HS BCM_HS
  SG_ AdvFrntLghtSysIndRq: 3|3@0+ (1,0) [0|7] "" BCM_HS
  SG_ HdLtLvlFlrIO: 0|1@0+ (1,0) [0|1] "" BCM_HS

BO_ 577 USDT_Req_to_BCM_HS: 8 TestTool_HS
  SG_ DgnInf: 7|64@0+ (1,0) [0|1.8446742e+19] "" BCM_HS

BO_ 298 Body_Information_HS: 8 BCM_HS
  SG_ SpdLmtrSttngTyp: 59|2@0+ (1,0) [0|3] "" ECM_HS
  SG_ TCSysDisSwAtv: 62|1@0+ (1,0) [0|1] "" ECM_HS
  SG_ AutoMdSpdLmtCnfrmd: 57|1@0+ (1,0) [0|1] "" ECM_HS
  SG_ TCSysDisSwAtvARC: 61|2@0+ (1,0) [0|3] "" ECM_HS EBCM_OBD_HS EBCM_HS
  SG_ ChmAct: 55|1@0+ (1,0) [0|1] "" ACC_HS
  SG_ DDAjrSwAtvM: 63|1@0+ (1,0) [0|1] "" EBCM_OBD_HS EBCM_HS ECM_HS ACC_HS
  SG_ CrshAlrtDrvrSlctdType: 5|1@0+ (1,0) [0|1] "" EBCM_OBD_HS EBCM_HS ACC_HS
  SG_ PsSbltAtcV: 54|1@0+ (1,0) [0|1] "" EBCM_OBD_HS EBCM_HS
  SG_ PsSbltAtc: 53|1@0+ (1,0) [0|1] "" EBCM_OBD_HS EBCM_HS
  SG_ TrlrBrkDsplyAct: 51|1@0+ (1,0) [0|1] "" FSCM_ITBC_HS
  SG_ RdSpdCatType: 45|2@0+ (1,0) [0|3] "" FCM_HS AHL_AFL_HS
  SG_ LnCat: 47|2@0+ (1,0) [0|3] "" FCM_HS AHL_AFL_HS
  SG_ FncRdClass: 50|3@0+ (1,0) [0|7] "" FCM_HS AHL_AFL_HS
  SG_ SprtLnRd: 43|1@0+ (1,0) [0|1] "" FCM_HS AHL_AFL_HS
  SG_ CntrldAccRd: 39|1@0+ (1,0) [0|1] "" FCM_HS AHL_AFL_HS
  SG_ BldUpArDet: 11|1@0+ (1,0) [0|1] "" FCM_HS AHL_AFL_HS
  SG_ MpDataAvlbl: 3|1@0+ (1,0) [0|1] "" FCM_HS AHL_AFL_HS
  SG_ SusCustStngReq: 42|3@0+ (1,0) [0|7] "" EBCM_OBD_HS EBCM_HS
  SG_ StrCustStngReq: 38|3@0+ (1,0) [0|7] "" EBCM_OBD_HS EBCM_HS
  SG_ RstrCustFctrDef: 35|1@0+ (1,0) [0|1] "" AHL_AFL_HS EBCM_OBD_HS EBCM_HS
  SG_ DrvlnCustStngReq: 34|3@0+ (1,0) [0|7] "" EBCM_OBD_HS EBCM_HS
  SG_ ChmMstrVDA: 22|1@0+ (1,0) [0|1] "" EOCM_F_HS ACC_HS
  SG_ IPCVDA: 21|1@0+ (1,0) [0|1] "" EOCM_F_HS ACC_HS EBCM_OBD_HS EBCM_HS
  SG_ HeadUpDispVDA: 20|1@0+ (1,0) [0|1] "" EOCM_F_HS ACC_HS
  SG_ HapticSeatVDA: 52|1@0+ (1,0) [0|1] "" ACC_HS
  SG_ RRDoorAjarSwAct: 23|1@0+ (1,0) [0|1] "" ICCM_OBD_HS ICCM_HS ALC_HS EPB_HS SADS_HS
  SG_ PDAjrSwAtv: 10|1@0+ (1,0) [0|1] "" EPB_HS ICCM_OBD_HS ICCM_HS ALC_HS SADS_HS
  SG_ DDAjrSwAtv: 9|1@0+ (1,0) [0|1] "" ECM_HS EBCM_OBD_HS EBCM_HS ACC_HS EPB_HS ICCM_OBD_HS ICCM_HS ALC_HS SADS_HS
  SG_ TrlrHWIntrfcVDA: 4|1@0+ (1,0) [0|1] "" EBCM_OBD_HS EBCM_HS RDCM_HS
  SG_ DrId: 15|3@0+ (1,0) [0|7] "" ACC_HS
  SG_ EnrgMgtLdShdRq: 19|4@0+ (1,0) [0|15] "" PTO_HS ARS_HS ICCM_OBD_HS ICCM_HS ALC_HS SADS_HS
  SG_ DrSbltAtcV: 2|1@0+ (1,0) [0|1] "" ECM_HS ACC_HS EPB_HS EBCM_OBD_HS EBCM_HS
  SG_ TrlrHtchSwAtv: 0|1@0+ (1,0) [0|1] "" EBCM_OBD_HS EBCM_HS RDCM_HS
  SG_ TreInfMonSysRstReq: 7|1@0+ (1,0) [0|1] "" EBCM_OBD_HS EBCM_HS
  SG_ HUDActv: 6|1@0+ (1,0) [0|1] "" ACC_HS
  SG_ BatVltV: 1|1@0+ (1,0) [0|1] "" LVMPC_HS EDI_HS TCM_HS HCP_HS BCP_HS MCP_C_HS MCP_B_HS MCP_A_HS ECM_HS EPB_HS ICCM_OBD_HS ICCM_HS ALC_HS SADS_HS
  SG_ BatVlt: 31|8@0+ (0.1,3) [3|28.5] "volts" LVMPC_HS EDI_HS TCM_HS HCP_HS BCP_HS MCP_C_HS MCP_B_HS MCP_A_HS ECM_HS EPB_HS ICCM_OBD_HS ICCM_HS ALC_HS SADS_HS
  SG_ RLDoorAjarSwAct: 8|1@0+ (1,0) [0|1] "" ICCM_OBD_HS ICCM_HS ALC_HS EPB_HS SADS_HS
  SG_ DrSbltAtc: 12|1@0+ (1,0) [0|1] "" ECM_HS ACC_HS EPB_HS EBCM_OBD_HS EBCM_HS

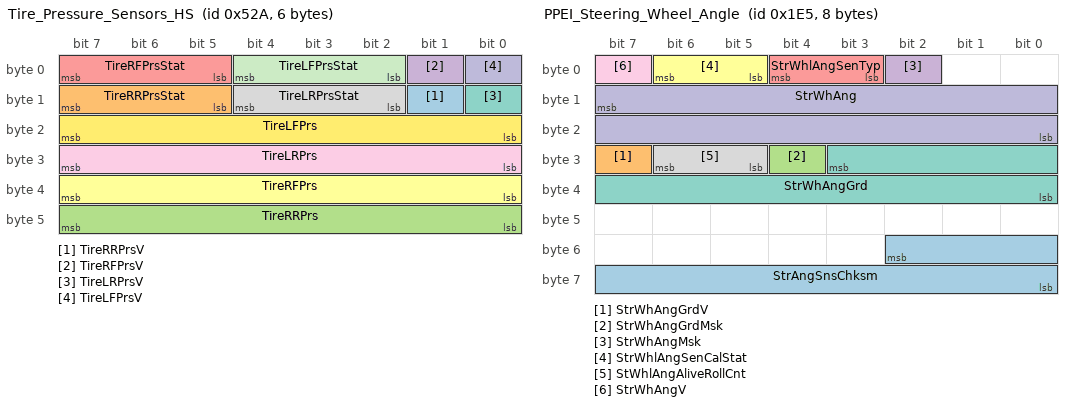
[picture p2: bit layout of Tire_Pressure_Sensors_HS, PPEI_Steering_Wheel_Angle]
BO_ 1322 Tire_Pressure_Sensors_HS: 6 BCM_HS
  SG_ TireRRPrsV: 9|1@0+ (1,0) [0|1] "" LVMPC_HS EDI_HS ICCM_OBD_HS ICCM_HS RDCM_HS EBCM_OBD_HS EBCM_HS
  SG_ TireRRPrsStat: 15|3@0+ (1,0) [0|7] "" LVMPC_HS EDI_HS ICCM_OBD_HS ICCM_HS RDCM_HS EBCM_OBD_HS EBCM_HS
  SG_ TireRRPrs: 47|8@0+ (4,0) [0|1020] "kPaG" LVMPC_HS EDI_HS ICCM_OBD_HS ICCM_HS RDCM_HS EBCM_OBD_HS EBCM_HS
  SG_ TireRFPrsV: 1|1@0+ (1,0) [0|1] "" LVMPC_HS EDI_HS ICCM_OBD_HS ICCM_HS RDCM_HS EBCM_OBD_HS EBCM_HS
  SG_ TireRFPrsStat: 7|3@0+ (1,0) [0|7] "" LVMPC_HS EDI_HS ICCM_OBD_HS ICCM_HS RDCM_HS EBCM_OBD_HS EBCM_HS
  SG_ TireRFPrs: 39|8@0+ (4,0) [0|1020] "kPaG" LVMPC_HS EDI_HS ICCM_OBD_HS ICCM_HS RDCM_HS EBCM_OBD_HS EBCM_HS
  SG_ TireLRPrsV: 8|1@0+ (1,0) [0|1] "" LVMPC_HS EDI_HS ICCM_OBD_HS ICCM_HS RDCM_HS EBCM_OBD_HS EBCM_HS
  SG_ TireLRPrsStat: 12|3@0+ (1,0) [0|7] "" LVMPC_HS EDI_HS ICCM_OBD_HS ICCM_HS RDCM_HS EBCM_OBD_HS EBCM_HS
  SG_ TireLRPrs: 31|8@0+ (4,0) [0|1020] "kPaG" LVMPC_HS EDI_HS ICCM_OBD_HS ICCM_HS RDCM_HS EBCM_OBD_HS EBCM_HS
  SG_ TireLFPrsV: 0|1@0+ (1,0) [0|1] "" LVMPC_HS EDI_HS ICCM_OBD_HS ICCM_HS RDCM_HS EBCM_OBD_HS EBCM_HS
  SG_ TireLFPrsStat: 4|3@0+ (1,0) [0|7] "" LVMPC_HS EDI_HS ICCM_OBD_HS ICCM_HS RDCM_HS EBCM_OBD_HS EBCM_HS
  SG_ TireLFPrs: 23|8@0+ (4,0) [0|1020] "kPaG" LVMPC_HS EDI_HS ICCM_OBD_HS ICCM_HS RDCM_HS EBCM_OBD_HS EBCM_HS

BO_ 1601 USDT_Resp_From_BCM_HS: 8 BCM_HS
  SG_ DgnInf: 7|64@0+ (1,0) [0|1.8446742e+19] "" FCP_HS ONSTAR_HS TestTool_HS

BO_ 2018 USDT_Req_to_TCM_MTA_MTIO_HS: 8 TestTool_HS
  SG_ DgnInf: 7|64@0+ (1,0) [0|1.8446742e+19] "" TCM_HS

BO_ 2026 USDT_Resp_From_TCM_MTA_MTIO_HS: 8 TCM_HS
  SG_ DgnInf: 7|64@0+ (1,0) [0|1.8446742e+19] "" FCP_HS ONSTAR_HS TestTool_HS

BO_ 1514 UUDT_Resp_From_TCM_MTA_MTIO_HS: 8 TCM_HS
  SG_ DgnInf: 7|64@0+ (1,0) [0|1.8446742e+19] "" FCP_HS ONSTAR_HS TestTool_HS

BO_ 1300 VIN_Digits_2_to_9_HS: 8 BCM_HS
  SG_ VehIdNmDig2_9: 7|64@0+ (1,0) [0|1] "" EBCM_OBD_HS EBCM_HS VES_HS EPS_HS VLBS_HS ACC_HS TCCM_HS EPB_HS AFS_HS RDCM_HS

BO_ 288 Vehicle_Odometer_HS: 5 BCM_HS
  SG_ VehOdo: 7|32@0+ (0.015625,0) [0|67108864] "km" LVMPC_HS TCCM_HS ACC_HS AFS_HS
  SG_ VehOdoV: 32|1@0+ (1,0) [0|1] "" LVMPC_HS TCCM_HS ACC_HS AFS_HS

BO_ 2020 USDT_Req_to_VICM_HS: 8 TestTool_HS
  SG_ DgnInf: 7|64@0+ (1,0) [0|1.8446742e+19] "" VICM_HS

BO_ 2028 USDT_Resp_From_VICM_HS: 8 VICM_HS
  SG_ DgnInf: 7|64@0+ (1,0) [0|1.8446742e+19] "" FCP_HS ONSTAR_HS TestTool_HS

BO_ 1516 UUDT_Resp_From_VICM_HS: 8 VICM_HS
  SG_ DgnInf: 7|64@0+ (1,0) [0|1.8446742e+19] "" FCP_HS ONSTAR_HS TestTool_HS

BO_ 485 PPEI_Steering_Wheel_Angle: 8 EBCM_HS
  SG_ StrAngSnsChksm: 50|11@0+ (1,0) [0|2047] "" FCM_HS HMIM_HS VES_HS EPS_HS EBCM_OBD_HS EBCM_HS EPB_HS
  SG_ StrWhAngGrdV: 31|1@0+ (1,0) [0|1] "" FCM_HS HMIM_HS ACC_HS FCP_HS ONSTAR_HS ICCM_OBD_HS ICCM_HS ALC_HS SADS_HS ECM_HS VES_HS EPS_HS EPB_HS RDCM_HS TCCM_HS EBCM_OBD_HS EBCM_HS
  SG_ StrWhAngGrdMsk: 28|1@0+ (1,0) [0|1] "" FCM_HS VES_HS EPS_HS HMIM_HS EPB_HS EBCM_OBD_HS EBCM_HS
  SG_ StrWhAngMsk: 2|1@0+ (1,0) [0|1] "" LVMPC_HS EDI_HS FCM_HS HMIM_HS ICCM_OBD_HS ICCM_HS ALC_HS SADS_HS VES_HS EPS_HS EPB_HS RDCM_HS EBCM_OBD_HS EBCM_HS
  SG_ StrWhlAngSenTyp: 4|2@0+ (1,0) [0|3] "" EBCM_OBD_HS EBCM_HS VES_HS EPS_HS HMIM_HS EPB_HS
  SG_ StrWhlAngSenCalStat: 6|2@0+ (1,0) [0|3] "" EBCM_OBD_HS EBCM_HS HMIM_HS FCM_HS ICCM_OBD_HS ICCM_HS ALC_HS SADS_HS VES_HS EPS_HS AHL_AFL_HS EPB_HS RDCM_HS ACC_HS BCM_HS TCCM_HS
  SG_ StrWhAngGrd: 27|12@0- (1,0) [-2048|2047] "deg/sec" FCM_HS EBCM_OBD_HS EBCM_HS HMIM_HS ACC_HS PCM_HS ECM_HS TCCM_HS RDCM_HS ICCM_OBD_HS ICCM_HS ALC_HS SADS_HS VES_HS EPS_HS EPB_HS FCP_HS ONSTAR_HS
  SG_ StWhlAngAliveRollCnt: 30|2@0+ (1,0) [0|3] "" HMIM_HS EBCM_OBD_HS EBCM_HS ICCM_OBD_HS ICCM_HS ALC_HS SADS_HS VES_HS EPS_HS RDCM_HS EPB_HS
  SG_ StrWhAngV: 7|1@0+ (1,0) [0|1] "" LVMPC_HS EDI_HS HMIM_HS FCM_HS EBCM_OBD_HS EBCM_HS ICCM_OBD_HS ICCM_HS ALC_HS SADS_HS VES_HS EPS_HS RDCM_HS FCP_HS ONSTAR_HS ACC_HS BCM_HS AHL_AFL_HS EPB_HS TCCM_HS
  SG_ StrWhAng: 15|16@0- (0.0625,0) [-2048|2047.9375] "deg" LVMPC_HS EDI_HS HMIM_HS FCM_HS EBCM_OBD_HS EBCM_HS ICCM_OBD_HS ICCM_HS ALC_HS SADS_HS VES_HS EPS_HS RDCM_HS EPB_HS FCP_HS ONSTAR_HS ACC_HS AHL_AFL_HS BCM_HS TCCM_HS

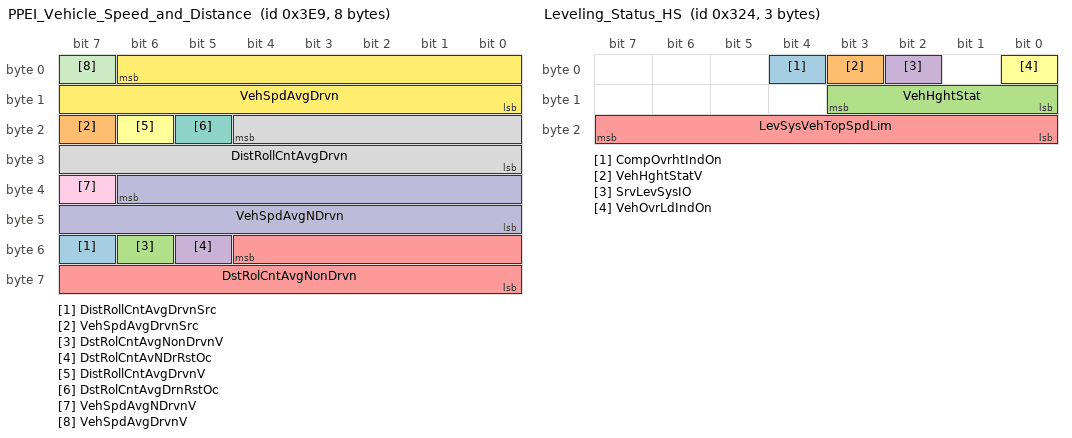
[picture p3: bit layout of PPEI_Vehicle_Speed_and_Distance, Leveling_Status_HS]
BO_ 1001 PPEI_Vehicle_Speed_and_Distance: 8 ECM_HS
  SG_ DistRollCntAvgDrvnSrc: 55|1@0+ (1,0) [0|1] "" HCP_HS BCP_HS HMIM_HS EBCM_OBD_HS EBCM_HS VES_HS EPS_HS VICM_HS TCM_HS TCCM_HS BCM_HS
  SG_ VehSpdAvgDrvnSrc: 23|1@0+ (1,0) [0|1] "" PTO_HS FICM_HS EBCM_OBD_HS EBCM_HS HMIM_HS TCM_HS ARS_HS VES_HS EPS_HS TCCM_HS EPB_HS BCM_HS
  SG_ DstRolCntAvgNonDrvnV: 54|1@0+ (1,0) [0|1] "" VICM_HS HMIM_HS EBCM_OBD_HS EBCM_HS VES_HS EPS_HS TCCM_HS BCM_HS
  SG_ DstRolCntAvNDrRstOc: 53|1@0+ (1,0) [0|1] "" VICM_HS HMIM_HS EBCM_OBD_HS EBCM_HS VES_HS EPS_HS TCCM_HS BCM_HS
  SG_ DstRolCntAvgNonDrvn: 52|13@0+ (0.125,0) [0|1023.875] "m" VICM_HS HMIM_HS EBCM_OBD_HS EBCM_HS VES_HS EPS_HS TCCM_HS BCM_HS
  SG_ DistRollCntAvgDrvnV: 22|1@0+ (1,0) [0|1] "" HCP_HS BCP_HS HMIM_HS EBCM_OBD_HS EBCM_HS VES_HS EPS_HS VICM_HS TCM_HS TCCM_HS ICCM_OBD_HS ICCM_HS FSCM_ITBC_HS FSCM_HS BCM_HS
  SG_ DstRolCntAvgDrnRstOc: 21|1@0+ (1,0) [0|1] "" HCP_HS BCP_HS HMIM_HS EBCM_OBD_HS EBCM_HS VES_HS EPS_HS VICM_HS TCM_HS TCCM_HS ICCM_OBD_HS ICCM_HS FSCM_ITBC_HS FSCM_HS BCM_HS
  SG_ DistRollCntAvgDrvn: 20|13@0+ (0.125,0) [0|1023.875] "m" HCP_HS BCP_HS HMIM_HS EBCM_OBD_HS EBCM_HS VES_HS EPS_HS VICM_HS TCM_HS TCCM_HS ICCM_OBD_HS ICCM_HS FSCM_ITBC_HS FSCM_HS BCM_HS
  SG_ VehSpdAvgNDrvnV: 39|1@0+ (1,0) [0|1] "" VICM2_HS VLBS_HS HMIM_HS FCP_HS ONSTAR_HS VES_HS EPS_HS VICM_HS ICCM_OBD_HS ICCM_HS EBCM_OBD_HS EBCM_HS APPS_HS TCCM_HS BCP_HS EPB_HS AHL_AFL_HS BCM_HS ACC_HS PTO_HS
  SG_ VehSpdAvgNDrvn: 38|15@0+ (0.015625,0) [0|511.98434] "km / h" VICM2_HS VLBS_HS HMIM_HS FCP_HS ONSTAR_HS VES_HS EPS_HS VICM_HS ICCM_OBD_HS ICCM_HS EBCM_OBD_HS EBCM_HS APPS_HS BCP_HS TCCM_HS EPB_HS AHL_AFL_HS BCM_HS ACC_HS PTO_HS
  SG_ VehSpdAvgDrvnV: 7|1@0+ (1,0) [0|1] "" PFAF_HS LVMPC_HS EDI_HS VLBS_HS FICM_HS EBCM_OBD_HS EBCM_HS HMIM_HS TCM_HS ARS_HS BCP_HS ONSTAR_HS VES_HS EPS_HS VICM_HS APPS_HS TCCM_HS FCP_HS VICM2_HS FSCM_ITBC_HS FSCM_HS EPB_HS ICCM_OBD_HS ICCM_HS ALC_HS SADS_HS ACC_HS BCM_HS PTO_HS
  SG_ VehSpdAvgDrvn: 6|15@0+ (0.015625,0) [0|511.98434] "km / h" PFAF_HS LVMPC_HS EDI_HS VLBS_HS FICM_HS EBCM_OBD_HS EBCM_HS HMIM_HS TCM_HS ARS_HS BCP_HS ONSTAR_HS VES_HS EPS_HS VICM_HS APPS_HS TCCM_HS VICM2_HS FSCM_ITBC_HS FSCM_HS EPB_HS ICCM_OBD_HS ICCM_HS ALC_HS SADS_HS FCP_HS ACC_HS BCM_HS PTO_HS

BO_ 961 PPEI_Powertrain_Immobilizer_Data: 8 ECM_HS
  SG_ PTImmblzerInfo: 7|64@0+ (1,0) [0|1.8446742e+19] "" PCM_HS ECM_HS VLBS_HS FCP_HS ONSTAR_HS BCM_HS

BO_ 804 Leveling_Status_HS: 3 SADS_HS
  SG_ CompOvrhtIndOn: 4|1@0+ (1,0) [0|1] "" BCM_HS
  SG_ VehHghtStatV: 3|1@0+ (1,0) [0|1] "" BCM_HS EBCM_OBD_HS EBCM_HS
  SG_ VehHghtStat: 11|4@0+ (1,0) [0|15] "" BCM_HS EBCM_OBD_HS EBCM_HS
  SG_ SrvLevSysIO: 2|1@0+ (1,0) [0|1] "" BCM_HS FCP_HS ONSTAR_HS
  SG_ LevSysVehTopSpdLim: 23|8@0+ (2,0) [0|510] "km/h" BCM_HS
  SG_ VehOvrLdIndOn: 0|1@0+ (1,0) [0|1] "" FCP_HS ONSTAR_HS BCM_HS

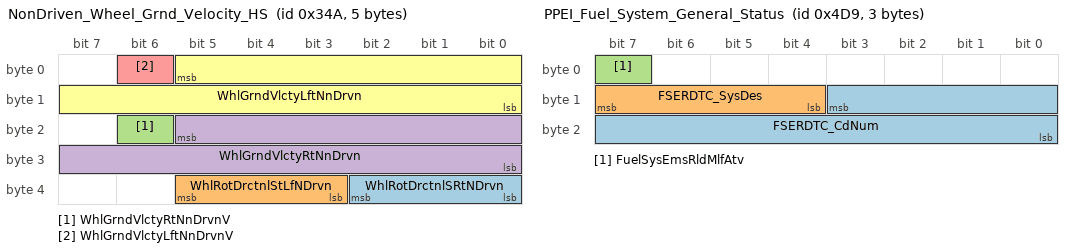
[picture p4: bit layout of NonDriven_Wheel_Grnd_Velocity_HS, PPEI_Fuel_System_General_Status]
BO_ 842 NonDriven_Wheel_Grnd_Velocity_HS: 5 EBCM_HS
  SG_ WhlRotDrctnlSRtNDrvn: 34|3@0+ (1,0) [0|7] "" VICM_HS EDI_HS EOCM_F_HS HMIM_HS
  SG_ WhlRotDrctnlStLfNDrvn: 37|3@0+ (1,0) [0|7] "" VICM_HS EDI_HS EOCM_F_HS HMIM_HS
  SG_ WhlGrndVlctyRtNnDrvnV: 22|1@0+ (1,0) [0|1] "" EDI_HS HMIM_HS TCCM_HS FCM_HS APPS_HS EOCM_F_HS EPB_HS RDCM_HS ACC_HS BCM_HS AFS_HS VES_HS EPS_HS SADS_HS
  SG_ WhlGrndVlctyRtNnDrvn: 21|14@0+ (0.03125,0) [0|511.96875] "km / h" EDI_HS HMIM_HS TCCM_HS FCM_HS APPS_HS EOCM_F_HS RDCM_HS ACC_HS BCM_HS EPB_HS AFS_HS VES_HS EPS_HS SADS_HS
  SG_ WhlGrndVlctyLftNnDrvnV: 6|1@0+ (1,0) [0|1] "" EDI_HS HMIM_HS TCCM_HS FCM_HS APPS_HS EOCM_F_HS EPB_HS BCM_HS RDCM_HS ACC_HS AFS_HS VES_HS EPS_HS SADS_HS
  SG_ WhlGrndVlctyLftNnDrvn: 5|14@0+ (0.03125,0) [0|511.96875] "km / h" EDI_HS HMIM_HS TCCM_HS FCM_HS APPS_HS EOCM_F_HS BCM_HS RDCM_HS ACC_HS EPB_HS VES_HS EPS_HS AFS_HS SADS_HS

BO_ 1241 PPEI_Fuel_System_General_Status: 3 FSCM_HS
  SG_ FSERDTC_CdNum: 11|12@0+ (1,0) [0|4095] "" PCM_HS ECM_HS
  SG_ FSERDTC_SysDes: 15|4@0+ (1,0) [0|15] "" PCM_HS ECM_HS
  SG_ FuelSysEmsRldMlfAtv: 7|1@0+ (1,0) [0|1] "" PCM_HS ECM_HS

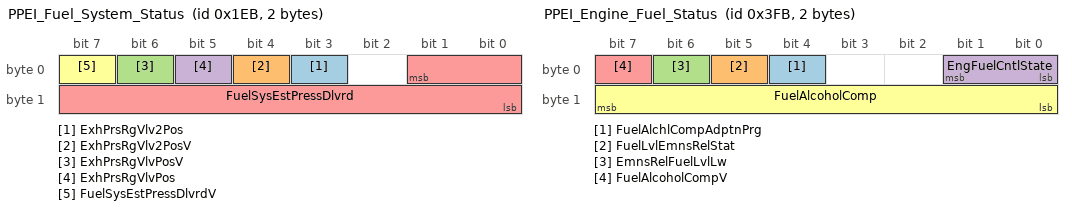
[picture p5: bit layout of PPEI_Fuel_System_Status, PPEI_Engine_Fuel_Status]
BO_ 491 PPEI_Fuel_System_Status: 2 FSCM_HS
  SG_ ExhPrsRgVlv2Pos: 3|1@0+ (1,0) [0|1] "" ECM_HS
  SG_ ExhPrsRgVlv2PosV: 4|1@0+ (1,0) [0|1] "" ECM_HS
  SG_ ExhPrsRgVlvPosV: 6|1@0+ (1,0) [0|1] "" PCM_HS ECM_HS
  SG_ ExhPrsRgVlvPos: 5|1@0+ (1,0) [0|1] "" PCM_HS ECM_HS
  SG_ FuelSysEstPressDlvrd: 1|10@0+ (1,0) [0|1023] "kPa" VCM_HS PCM_HS ECM_HS
  SG_ FuelSysEstPressDlvrdV: 7|1@0+ (1,0) [0|1] "" VCM_HS PCM_HS ECM_HS

BO_ 1019 PPEI_Engine_Fuel_Status: 2 ECM_HS
  SG_ FuelAlchlCompAdptnPrg: 4|1@0+ (1,0) [0|1] "" BCM_HS
  SG_ FuelLvlEmnsRelStat: 5|1@0+ (1,0) [0|1] "" FICM_HS BCP_HS
  SG_ EmnsRelFuelLvlLw: 6|1@0+ (1,0) [0|1] "" FICM_HS BCP_HS ICCM_OBD_HS ICCM_HS FSCM_ITBC_HS FSCM_HS
  SG_ EngFuelCntlState: 1|2@0+ (1,0) [0|3] "" FICM_HS ICCM_OBD_HS ICCM_HS FSCM_ITBC_HS FSCM_HS
  SG_ FuelAlcoholCompV: 7|1@0+ (1,0) [0|1] "" FICM_HS VICM_HS FCP_HS ONSTAR_HS BCM_HS ICCM_OBD_HS ICCM_HS FSCM_ITBC_HS FSCM_HS
  SG_ FuelAlcoholComp: 15|8@0+ (0.39215702,0) [0|100.00004] "%" FICM_HS VICM_HS FCP_HS ONSTAR_HS BCM_HS ICCM_OBD_HS ICCM_HS FSCM_ITBC_HS FSCM_HS

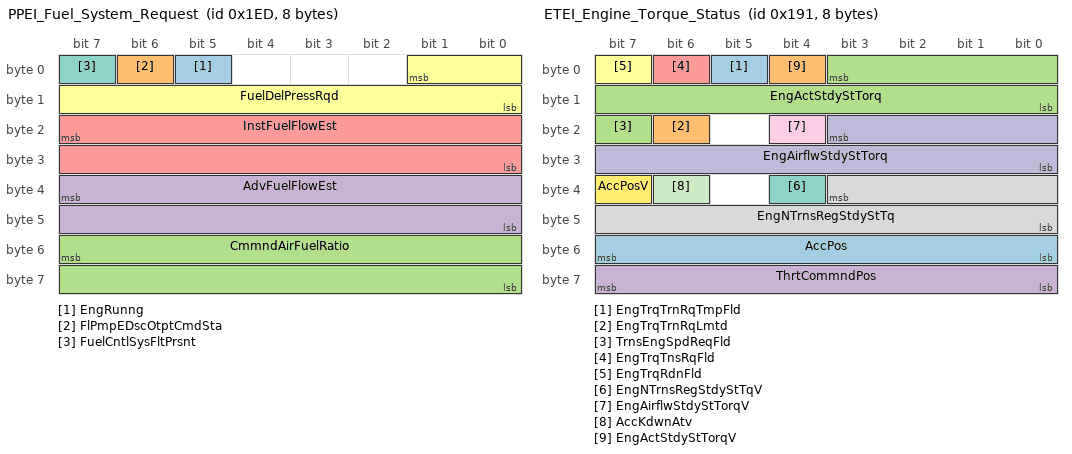
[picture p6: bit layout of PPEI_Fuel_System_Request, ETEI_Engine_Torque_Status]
BO_ 493 PPEI_Fuel_System_Request: 8 ECM_HS
  SG_ EngRunng: 5|1@0+ (1,0) [0|1] "" PTO_HS ICCM_OBD_HS ICCM_HS FSCM_ITBC_HS FSCM_HS AMP_HS
  SG_ FlPmpEDscOtptCmdSta: 6|1@0+ (1,0) [0|1] "" FICM_HS ICCM_OBD_HS ICCM_HS FSCM_ITBC_HS FSCM_HS
  SG_ CmmndAirFuelRatio: 55|16@0+ (0.00048828102,0) [0|31.999496] "" FICM_HS ICCM_OBD_HS ICCM_HS FSCM_ITBC_HS FSCM_HS
  SG_ AdvFuelFlowEst: 39|16@0+ (0.00097656203,0) [0|63.998993] "grams/s" ICCM_OBD_HS ICCM_HS FSCM_ITBC_HS FSCM_HS
  SG_ InstFuelFlowEst: 23|16@0+ (0.00097656203,0) [0|63.998993] "grams/s" VICM_HS FICM_HS ICCM_OBD_HS ICCM_HS FSCM_ITBC_HS FSCM_HS
  SG_ FuelDelPressRqd: 1|10@0+ (1,0) [0|1023] "kPa" ICCM_OBD_HS ICCM_HS FSCM_ITBC_HS FSCM_HS
  SG_ FuelCntlSysFltPrsnt: 7|1@0+ (1,0) [0|1] "" FICM_HS ICCM_OBD_HS ICCM_HS FSCM_ITBC_HS FSCM_HS

BO_ 401 ETEI_Engine_Torque_Status: 8 ECM_HS
  SG_ EngTrqTrnRqTmpFld: 5|1@0+ (1,0) [0|1] "" TCCM_HS TCM_HS
  SG_ EngTrqTrnRqLmtd: 22|1@0+ (1,0) [0|1] "" TCCM_HS TCM_HS
  SG_ TrnsEngSpdReqFld: 23|1@0+ (1,0) [0|1] "" TCCM_HS TCM_HS
  SG_ ThrtCommndPos: 63|8@0+ (0.39215702,0) [0|100.00004] "%" TCCM_HS
  SG_ EngTrqTnsRqFld: 6|1@0+ (1,0) [0|1] "" TCCM_HS TCM_HS
  SG_ EngTrqRdnFld: 7|1@0+ (1,0) [0|1] "" TCCM_HS TCM_HS
  SG_ EngNTrnsRegStdyStTqV: 36|1@0+ (1,0) [0|1] "" TCCM_HS TCM_HS
  SG_ EngNTrnsRegStdyStTq: 35|12@0+ (0.5,-848) [-848|1199.5] "Nm" TCCM_HS TCM_HS
  SG_ EngAirflwStdyStTorqV: 20|1@0+ (1,0) [0|1] "" TCCM_HS TCM_HS
  SG_ EngAirflwStdyStTorq: 19|12@0+ (0.5,-848) [-848|1199.5] "Nm" TCCM_HS TCM_HS
  SG_ AccKdwnAtv: 38|1@0+ (1,0) [0|1] "" TCCM_HS TCM_HS
  SG_ AccPosV: 39|1@0+ (1,0) [0|1] "" FSCM_HS BCP_HS FICM_HS TCM_HS
  SG_ AccPos: 55|8@0+ (0.39215702,0) [0|100.00004] "%" FSCM_HS BCP_HS FICM_HS TCM_HS
  SG_ EngActStdyStTorqV: 4|1@0+ (1,0) [0|1] "" TCCM_HS TCM_HS
  SG_ EngActStdyStTorq: 3|12@0+ (0.5,-848) [-848|1199.5] "Nm" TCCM_HS TCM_HS

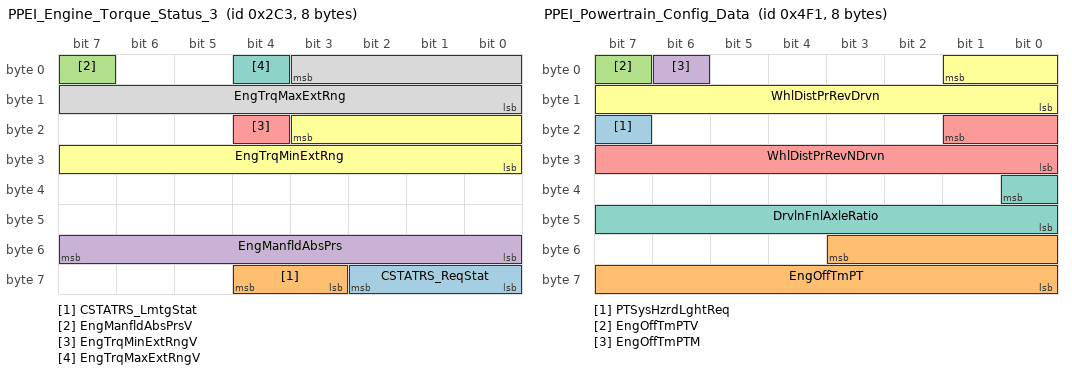
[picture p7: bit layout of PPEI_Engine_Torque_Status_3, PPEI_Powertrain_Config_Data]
BO_ 707 PPEI_Engine_Torque_Status_3: 8 ECM_HS
  SG_ CSTATRS_ReqStat: 58|3@0+ (1,0) [0|7] "" EBCM_OBD_HS EBCM_HS
  SG_ CSTATRS_LmtgStat: 60|2@0+ (1,0) [0|3] "" EBCM_OBD_HS EBCM_HS
  SG_ EngManfldAbsPrsV: 7|1@0+ (1,0) [0|1] "" EDI_HS AMP_HS BCP_HS EBCM_OBD_HS EBCM_HS
  SG_ EngManfldAbsPrs: 55|8@0+ (0.5,0) [0|127.5] "kPa" EDI_HS AMP_HS BCP_HS EBCM_OBD_HS EBCM_HS
  SG_ EngTrqMinExtRngV: 20|1@0+ (1,0) [0|1] "" ACC_HS EBCM_OBD_HS EBCM_HS
  SG_ EngTrqMinExtRng: 19|12@0+ (0.5,-848) [-848|1199.5] "Nm" ACC_HS EBCM_OBD_HS EBCM_HS
  SG_ EngTrqMaxExtRngV: 4|1@0+ (1,0) [0|1] "" TCCM_HS ACC_HS EBCM_OBD_HS EBCM_HS RDCM_HS
  SG_ EngTrqMaxExtRng: 3|12@0+ (0.5,-848) [-848|1199.5] "Nm" TCCM_HS ACC_HS RDCM_HS EBCM_OBD_HS EBCM_HS

BO_ 1265 PPEI_Powertrain_Config_Data: 8 ECM_HS
  SG_ PTSysHzrdLghtReq: 23|1@0+ (1,0) [0|1] "" BCM_HS
  SG_ EngOffTmPT: 51|12@0+ (0.5,0) [0|2047.5] "min" EBCM_OBD_HS EBCM_HS MCP_HS TCM_HS
  SG_ EngOffTmPTV: 7|1@0+ (1,0) [0|1] "" EBCM_OBD_HS EBCM_HS MCP_HS TCM_HS
  SG_ EngOffTmPTM: 6|1@0+ (1,0) [0|1] "" EBCM_OBD_HS EBCM_HS MCP_HS TCM_HS
  SG_ WhlDistPrRevNDrvn: 17|10@0+ (3,800) [800|3869] "mm" ICCM_OBD_HS ICCM_HS HMIM_HS VES_HS EPS_HS FSCM_ITBC_HS TCCM_HS EPB_HS EOCM_F_HS EBCM_OBD_HS EBCM_HS RDCM_HS
  SG_ WhlDistPrRevDrvn: 1|10@0+ (3,800) [800|3869] "mm" ICCM_OBD_HS ICCM_HS HMIM_HS VES_HS EPS_HS EOCM_F_HS FSCM_ITBC_HS ACC_HS TCCM_HS EPB_HS EBCM_OBD_HS EBCM_HS BCM_HS RDCM_HS
  SG_ DrvlnFnlAxleRatio: 32|9@0+ (0.010000001,2) [2|7.1100001] "" PTAM_HS TCCM_HS BCM_HS EBCM_OBD_HS EBCM_HS

BO_TX_BU_ 1357:FCP_HS,ONSTAR_HS;
BO_TX_BU_ 1613:FCP_HS,ONSTAR_HS;
BO_TX_BU_ 582:FCP_HS,ONSTAR_HS,TestTool_HS;
BO_TX_BU_ 590:FCP_HS,ONSTAR_HS,TestTool_HS;
BO_TX_BU_ 601:FCP_HS,ONSTAR_HS,TestTool_HS;
BO_TX_BU_ 2023:FCP_HS,ONSTAR_HS,TestTool_HS;
BO_TX_BU_ 2021:FCP_HS,ONSTAR_HS,TestTool_HS;
BO_TX_BU_ 2017:FCP_HS,ONSTAR_HS,TestTool_HS;
BO_TX_BU_ 2019:FCP_HS,ONSTAR_HS,TestTool_HS;
BO_TX_BU_ 585:FCP_HS,ONSTAR_HS,TestTool_HS;
BO_TX_BU_ 578:FCP_HS,ONSTAR_HS,TestTool_HS;
BO_TX_BU_ 2022:FCP_HS,ONSTAR_HS,TestTool_HS;
BO_TX_BU_ 584:FCP_HS,ONSTAR_HS,TestTool_HS;
BO_TX_BU_ 591:FCP_HS,ONSTAR_HS,TestTool_HS;
BO_TX_BU_ 581:FCP_HS,ONSTAR_HS,TestTool_HS;
BO_TX_BU_ 586:FCP_HS,ONSTAR_HS,TestTool_HS;
BO_TX_BU_ 588:FCP_HS,ONSTAR_HS,TestTool_HS;
BO_TX_BU_ 580:FCP_HS,ONSTAR_HS,TestTool_HS;
BO_TX_BU_ 1282:ICCM_OBD_HS,ICCM_HS,ALC_HS;
BO_TX_BU_ 1920:EBCM_OBD_HS,EBCM_HS;
BO_TX_BU_ 596:FCP_HS,ONSTAR_HS,TestTool_HS;
BO_TX_BU_ 495:PCM_HS,ECM_HS;
BO_TX_BU_ 1914:TCCM_HS,RDCM_HS;
BO_TX_BU_ 583:FCP_HS,ONSTAR_HS,TestTool_HS;
BO_TX_BU_ 1906:PCM_HS,ECM_HS;
BO_TX_BU_ 1907:EBCM_OBD_HS,EBCM_HS;
BO_TX_BU_ 579:FCP_HS,ONSTAR_HS,TestTool_HS;
BO_TX_BU_ 1603:HPCC_HS,EBCM_HS;
BO_TX_BU_ 1347:HPCC_HS,EBCM_HS;
BO_TX_BU_ 1915:FCM_HS,ACC_HS;
BO_TX_BU_ 587:FCP_HS,ONSTAR_HS,TestTool_HS;
BO_TX_BU_ 1611:EOCM_F_HS,FCM_HS;
BO_TX_BU_ 1355:EOCM_F_HS,FCM_HS;
BO_TX_BU_ 880:EOCM_F_HS,ACC_HS;
BO_TX_BU_ 577:FCP_HS,ONSTAR_HS,TestTool_HS;
BO_TX_BU_ 2018:FCP_HS,ONSTAR_HS,TestTool_HS;
BO_TX_BU_ 2020:FCP_HS,ONSTAR_HS,TestTool_HS;
BO_TX_BU_ 485:SAS_HS,EBCM_OBD_HS,EPS_HS,EBCM_HS;
BO_TX_BU_ 961:HCP_HS,PCM_HS,ECM_HS;
BO_TX_BU_ 804:ICCM_OBD_HS,ICCM_HS,ALC_HS,SADS_HS;
BO_TX_BU_ 842:EBCM_OBD_HS,EBCM_HS;
BO_TX_BU_ 1241:ICCM_OBD_HS,ICCM_HS,FSCM_ITBC_HS,FSCM_HS;
BO_TX_BU_ 491:ICCM_OBD_HS,ICCM_HS,FSCM_ITBC_HS,FSCM_HS;
BO_TX_BU_ 1019:PCM_HS,ECM_HS;
BO_TX_BU_ 493:PCM_HS,ECM_HS;
BO_TX_BU_ 401:PCM_HS,ECM_HS;
BO_TX_BU_ 1265:PCM_HS,ECM_HS;
VAL_ 1917 DTCI_DTCFaultType_77D 0 "Not Supported" 1 "Type A" 2 "Type B" 3 "Type C";
VAL_ 1917 DTCI_CodeSupported_77D 0 "false" 1 "true";
VAL_ 1917 DTCI_CurrentStatus_77D 0 "false" 1 "true";
VAL_ 1917 DTCI_TstNPsdCdClrdSt_77D 0 "false" 1 "true";
VAL_ 1917 DTCI_TstFldCdClrdStat_77D 0 "false" 1 "true";
VAL_ 1917 DTCI_HistStat_77D 0 "false" 1 "true";
VAL_ 1917 DTCI_TstNPsdPwrUpSt_77D 0 "false" 1 "true";
VAL_ 1917 DTCI_TstFldPwrUpSt_77D 0 "false" 1 "true";
VAL_ 1917 DTCI_WrnIndRqdSt_77D 0 "false" 1 "true";
VAL_ 1917 DTCI_DTCTriggered_77D 0 "false" 1 "true";
VAL_ 1917 DTCIUnused7_77D 0 "false" 1 "true";
VAL_ 1917 DTCIUnused6_77D 0 "false" 1 "true";
VAL_ 1917 DTCIUnused5_77D 0 "false" 1 "true";
VAL_ 1917 DTCIUnused4_77D 0 "false" 1 "true";
VAL_ 1917 DTCIUnused3_77D 0 "false" 1 "true";
VAL_ 1917 DTCIUnused2_77D 0 "false" 1 "true";
VAL_ 1917 DTCIUnused1_77D 0 "false" 1 "true";
VAL_ 1918 DTCI_DTCFaultType_77E 0 "Not Supported" 1 "Type A" 2 "Type B" 3 "Type C";
VAL_ 1918 DTCI_CodeSupported_77E 0 "false" 1 "true";
VAL_ 1918 DTCI_CurrentStatus_77E 0 "false" 1 "true";
VAL_ 1918 DTCI_TstNPsdCdClrdSt_77E 0 "false" 1 "true";
VAL_ 1918 DTCI_TstFldCdClrdStat_77E 0 "false" 1 "true";
VAL_ 1918 DTCI_HistStat_77E 0 "false" 1 "true";
VAL_ 1918 DTCI_TstNPsdPwrUpSt_77E 0 "false" 1 "true";
VAL_ 1918 DTCI_TstFldPwrUpSt_77E 0 "false" 1 "true";
VAL_ 1918 DTCI_WrnIndRqdSt_77E 0 "false" 1 "true";
VAL_ 1918 DTCI_DTCTriggered_77E 0 "false" 1 "true";
VAL_ 1918 DTCIUnused7_77E 0 "false" 1 "true";
VAL_ 1918 DTCIUnused6_77E 0 "false" 1 "true";
VAL_ 1918 DTCIUnused5_77E 0 "false" 1 "true";
VAL_ 1918 DTCIUnused4_77E 0 "false" 1 "true";
VAL_ 1918 DTCIUnused3_77E 0 "false" 1 "true";
VAL_ 1918 DTCIUnused2_77E 0 "false" 1 "true";
VAL_ 1918 DTCIUnused1_77E 0 "false" 1 "true";
VAL_ 1919 DTCI_DTCFaultType_77F 0 "Not Supported" 1 "Type A" 2 "Type B" 3 "Type C";
VAL_ 1919 DTCI_CodeSupported_77F 0 "false" 1 "true";
VAL_ 1919 DTCI_CurrentStatus_77F 0 "false" 1 "true";
VAL_ 1919 DTCI_TstNPsdCdClrdSt_77F 0 "false" 1 "true";
VAL_ 1919 DTCI_TstFldCdClrdStat_77F 0 "false" 1 "true";
VAL_ 1919 DTCI_HistStat_77F 0 "false" 1 "true";
VAL_ 1919 DTCI_TstNPsdPwrUpSt_77F 0 "false" 1 "true";
VAL_ 1919 DTCI_TstFldPwrUpSt_77F 0 "false" 1 "true";
VAL_ 1919 DTCI_WrnIndRqdSt_77F 0 "false" 1 "true";
VAL_ 1919 DTCI_DTCTriggered_77F 0 "false" 1 "true";
VAL_ 1919 DTCIUnused7_77F 0 "false" 1 "true";
VAL_ 1919 DTCIUnused6_77F 0 "false" 1 "true";
VAL_ 1919 DTCIUnused5_77F 0 "false" 1 "true";
VAL_ 1919 DTCIUnused4_77F 0 "false" 1 "true";
VAL_ 1919 DTCIUnused3_77F 0 "false" 1 "true";
VAL_ 1919 DTCIUnused2_77F 0 "false" 1 "true";
VAL_ 1919 DTCIUnused1_77F 0 "false" 1 "true";
VAL_ 499 PTShftPtrnOvrdAct 0 "false" 1 "true";
VAL_ 499 PFTrnsTUDSecSwSt 0 "No Activation" 1 "Increment Switch Active" 2 "Decrement Switch Active" 3 "Illegal Up/Down Switch State Active";
VAL_ 499 TrnsPFShftPattSw4Act 0 "false" 1 "true";
VAL_ 499 TrnsPFShftPattSw3Act 0 "false" 1 "true";
VAL_ 499 TrnsPFShftPattSw2Act 0 "false" 1 "true";
VAL_ 499 TrnsPFShftPattSw1Act 0 "false" 1 "true";
VAL_ 499 PFTrnsTUDSwSt 0 "No Activation" 1 "Increment Switch Active" 2 "Decrement Switch Active" 3 "Illegal Up/Down Switch State Active";
VAL_ 499 PFTrnsTUDEnSwSt 0 "No Activation" 1 "Driver Shift Control Enable Switch" 2 "Electronic Range Select Enable Sw" 3 "Illegal Enable Switch State";
VAL_ 499 OvrdrvDsblReqd 0 "false" 1 "true";
VAL_ 1282 TireTrdTmpStat 0 "No Action (unknown)" 1 "Frozen" 2 "Cold" 3 "Warm" 4 "Hot" 5 "Overheated";
VAL_ 1282 AllNodesVNA_502 0 "No Activation" 1 "Activate Virtual Network";
VAL_ 1282 A3ERRAlrmReq 0 "No Action" 1 "Set Alarm" 2 "Cancel Alarm";
VAL_ 1921 DTCI_CurrentStatus_781 0 "false" 1 "true";
VAL_ 1921 DTCI_WrnIndRqdSt_781 0 "false" 1 "true";
VAL_ 1921 DTCIUnused7_781 0 "false" 1 "true";
VAL_ 1921 DTCIUnused6_781 0 "false" 1 "true";
VAL_ 1921 DTCIUnused5_781 0 "false" 1 "true";
VAL_ 1921 DTCIUnused4_781 0 "false" 1 "true";
VAL_ 1921 DTCIUnused3_781 0 "false" 1 "true";
VAL_ 1921 DTCIUnused2_781 0 "false" 1 "true";
VAL_ 1921 DTCIUnused1_781 0 "false" 1 "true";
VAL_ 1921 DTCI_TstNPsdPwrUpSt_781 0 "false" 1 "true";
VAL_ 1921 DTCI_TstNPsdCdClrdSt_781 0 "false" 1 "true";
VAL_ 1921 DTCI_TstFldPwrUpSt_781 0 "false" 1 "true";
VAL_ 1921 DTCI_TstFldCdClrdStat_781 0 "false" 1 "true";
VAL_ 1921 DTCI_HistStat_781 0 "false" 1 "true";
VAL_ 1921 DTCI_DTCTriggered_781 0 "false" 1 "true";
VAL_ 1921 DTCI_DTCFaultType_781 0 "Not Supported" 1 "Type A" 2 "Type B" 3 "Type C";
VAL_ 1921 DTCI_CodeSupported_781 0 "false" 1 "true";
VAL_ 1920 DTCI_CurrentStatus_780 0 "false" 1 "true";
VAL_ 1920 DTCI_WrnIndRqdSt_780 0 "false" 1 "true";
VAL_ 1920 DTCIUnused7_780 0 "false" 1 "true";
VAL_ 1920 DTCIUnused6_780 0 "false" 1 "true";
VAL_ 1920 DTCIUnused5_780 0 "false" 1 "true";
VAL_ 1920 DTCIUnused4_780 0 "false" 1 "true";
VAL_ 1920 DTCIUnused3_780 0 "false" 1 "true";
VAL_ 1920 DTCIUnused2_780 0 "false" 1 "true";
VAL_ 1920 DTCIUnused1_780 0 "false" 1 "true";
VAL_ 1920 DTCI_TstNPsdPwrUpSt_780 0 "false" 1 "true";
VAL_ 1920 DTCI_TstNPsdCdClrdSt_780 0 "false" 1 "true";
VAL_ 1920 DTCI_TstFldPwrUpSt_780 0 "false" 1 "true";
VAL_ 1920 DTCI_TstFldCdClrdStat_780 0 "false" 1 "true";
VAL_ 1920 DTCI_HistStat_780 0 "false" 1 "true";
VAL_ 1920 DTCI_DTCTriggered_780 0 "false" 1 "true";
VAL_ 1920 DTCI_DTCFaultType_780 0 "Not Supported" 1 "Type A" 2 "Type B" 3 "Type C";
VAL_ 1920 DTCI_CodeSupported_780 0 "false" 1 "true";
VAL_ 495 MassAirFloV 0 "Valid" 1 "Invalid";
VAL_ 1914 DTCI_DTCFaultType_77A 0 "Not Supported" 1 "Type A" 2 "Type B" 3 "Type C";
VAL_ 1914 DTCI_CodeSupported_77A 0 "false" 1 "true";
VAL_ 1914 DTCI_CurrentStatus_77A 0 "false" 1 "true";
VAL_ 1914 DTCI_TstNPsdCdClrdSt_77A 0 "false" 1 "true";
VAL_ 1914 DTCI_TstFldCdClrdStat_77A 0 "false" 1 "true";
VAL_ 1914 DTCI_HistStat_77A 0 "false" 1 "true";
VAL_ 1914 DTCI_TstNPsdPwrUpSt_77A 0 "false" 1 "true";
VAL_ 1914 DTCI_TstFldPwrUpSt_77A 0 "false" 1 "true";
VAL_ 1914 DTCI_WrnIndRqdSt_77A 0 "false" 1 "true";
VAL_ 1914 DTCI_DTCTriggered_77A 0 "false" 1 "true";
VAL_ 1914 DTCIUnused7_77A 0 "false" 1 "true";
VAL_ 1914 DTCIUnused6_77A 0 "false" 1 "true";
VAL_ 1914 DTCIUnused5_77A 0 "false" 1 "true";
VAL_ 1914 DTCIUnused4_77A 0 "false" 1 "true";
VAL_ 1914 DTCIUnused3_77A 0 "false" 1 "true";
VAL_ 1914 DTCIUnused2_77A 0 "false" 1 "true";
VAL_ 1914 DTCIUnused1_77A 0 "false" 1 "true";
VAL_ 1911 DTCI_DTCFaultType_777 0 "Not Supported" 1 "Type A" 2 "Type B" 3 "Type C";
VAL_ 1911 DTCI_CodeSupported_777 0 "false" 1 "true";
VAL_ 1911 DTCI_CurrentStatus_777 0 "false" 1 "true";
VAL_ 1911 DTCI_TstNPsdCdClrdSt_777 0 "false" 1 "true";
VAL_ 1911 DTCI_TstFldCdClrdStat_777 0 "false" 1 "true";
VAL_ 1911 DTCI_HistStat_777 0 "false" 1 "true";
VAL_ 1911 DTCI_TstNPsdPwrUpSt_777 0 "false" 1 "true";
VAL_ 1911 DTCI_TstFldPwrUpSt_777 0 "false" 1 "true";
VAL_ 1911 DTCI_WrnIndRqdSt_777 0 "false" 1 "true";
VAL_ 1911 DTCI_DTCTriggered_777 0 "false" 1 "true";
VAL_ 1911 DTCIUnused7_777 0 "false" 1 "true";
VAL_ 1911 DTCIUnused6_777 0 "false" 1 "true";
VAL_ 1911 DTCIUnused5_777 0 "false" 1 "true";
VAL_ 1911 DTCIUnused4_777 0 "false" 1 "true";
VAL_ 1911 DTCIUnused3_777 0 "false" 1 "true";
VAL_ 1911 DTCIUnused2_777 0 "false" 1 "true";
VAL_ 1911 DTCIUnused1_777 0 "false" 1 "true";
VAL_ 1906 DTCI_DTCFaultType_772 0 "Not Supported" 1 "Type A" 2 "Type B" 3 "Type C";
VAL_ 1906 DTCI_CodeSupported_772 0 "false" 1 "true";
VAL_ 1906 DTCI_CurrentStatus_772 0 "false" 1 "true";
VAL_ 1906 DTCI_TstNPsdCdClrdSt_772 0 "false" 1 "true";
VAL_ 1906 DTCI_TstFldCdClrdStat_772 0 "false" 1 "true";
VAL_ 1906 DTCI_HistStat_772 0 "false" 1 "true";
VAL_ 1906 DTCI_TstNPsdPwrUpSt_772 0 "false" 1 "true";
VAL_ 1906 DTCI_TstFldPwrUpSt_772 0 "false" 1 "true";
VAL_ 1906 DTCI_WrnIndRqdSt_772 0 "false" 1 "true";
VAL_ 1906 DTCI_DTCTriggered_772 0 "false" 1 "true";
VAL_ 1906 DTCIUnused7_772 0 "false" 1 "true";
VAL_ 1906 DTCIUnused6_772 0 "false" 1 "true";
VAL_ 1906 DTCIUnused5_772 0 "false" 1 "true";
VAL_ 1906 DTCIUnused4_772 0 "false" 1 "true";
VAL_ 1906 DTCIUnused3_772 0 "false" 1 "true";
VAL_ 1906 DTCIUnused2_772 0 "false" 1 "true";
VAL_ 1906 DTCIUnused1_772 0 "false" 1 "true";
VAL_ 1907 DTCI_DTCFaultType_773 0 "Not Supported" 1 "Type A" 2 "Type B" 3 "Type C";
VAL_ 1907 DTCI_CodeSupported_773 0 "false" 1 "true";
VAL_ 1907 DTCI_CurrentStatus_773 0 "false" 1 "true";
VAL_ 1907 DTCI_TstNPsdCdClrdSt_773 0 "false" 1 "true";
VAL_ 1907 DTCI_TstFldCdClrdStat_773 0 "false" 1 "true";
VAL_ 1907 DTCI_HistStat_773 0 "false" 1 "true";
VAL_ 1907 DTCI_TstNPsdPwrUpSt_773 0 "false" 1 "true";
VAL_ 1907 DTCI_TstFldPwrUpSt_773 0 "false" 1 "true";
VAL_ 1907 DTCI_WrnIndRqdSt_773 0 "false" 1 "true";
VAL_ 1907 DTCI_DTCTriggered_773 0 "false" 1 "true";
VAL_ 1907 DTCIUnused7_773 0 "false" 1 "true";
VAL_ 1907 DTCIUnused6_773 0 "false" 1 "true";
VAL_ 1907 DTCIUnused5_773 0 "false" 1 "true";
VAL_ 1907 DTCIUnused4_773 0 "false" 1 "true";
VAL_ 1907 DTCIUnused3_773 0 "false" 1 "true";
VAL_ 1907 DTCIUnused2_773 0 "false" 1 "true";
VAL_ 1907 DTCIUnused1_773 0 "false" 1 "true";
VAL_ 1915 DTCI_DTCFaultType_77B 0 "Not Supported" 1 "Type A" 2 "Type B" 3 "Type C";
VAL_ 1915 DTCI_CodeSupported_77B 0 "false" 1 "true";
VAL_ 1915 DTCI_CurrentStatus_77B 0 "false" 1 "true";
VAL_ 1915 DTCI_TstNPsdCdClrdSt_77B 0 "false" 1 "true";
VAL_ 1915 DTCI_TstFldCdClrdStat_77B 0 "false" 1 "true";
VAL_ 1915 DTCI_HistStat_77B 0 "false" 1 "true";
VAL_ 1915 DTCI_TstNPsdPwrUpSt_77B 0 "false" 1 "true";
VAL_ 1915 DTCI_TstFldPwrUpSt_77B 0 "false" 1 "true";
VAL_ 1915 DTCI_WrnIndRqdSt_77B 0 "false" 1 "true";
VAL_ 1915 DTCI_DTCTriggered_77B 0 "false" 1 "true";
VAL_ 1915 DTCIUnused7_77B 0 "false" 1 "true";
VAL_ 1915 DTCIUnused6_77B 0 "false" 1 "true";
VAL_ 1915 DTCIUnused5_77B 0 "false" 1 "true";
VAL_ 1915 DTCIUnused4_77B 0 "false" 1 "true";
VAL_ 1915 DTCIUnused3_77B 0 "false" 1 "true";
VAL_ 1915 DTCIUnused2_77B 0 "false" 1 "true";
VAL_ 1915 DTCIUnused1_77B 0 "false" 1 "true";
VAL_ 880 FOAI_VehAhdIndRq 0 "No Alert" 1 "Alert Level 1" 2 "Alert Level 2" 3 "Alert Level 3";
VAL_ 880 FOAI_AlrtWrnIndRq 0 "No Alert" 1 "Alert Level 1" 2 "Alert Level 2" 3 "Alert Level 3";
VAL_ 880 FOAI_AlrtChmIhbRq 0 "Allow Chime" 1 "Inhibit Chime";
VAL_ 880 FwdClnAlrtPr 0 "false" 1 "true";
VAL_ 880 ACCUnavlbleDTWthrIO 0 "false" 1 "true";
VAL_ 880 ACCAct370 0 "false" 1 "true";
VAL_ 880 DrvThrtlOvrdIO 0 "false" 1 "true";
VAL_ 880 ServAdpCrsCtrlIndOn 0 "false" 1 "true";
VAL_ 880 ACCHdwayStngIO 0 "false" 1 "true";
VAL_ 880 ACCHdwyStg 0 "Minimum Headway Setting" 1 "Headway Setting 1" 2 "Headway Setting 2" 3 "Headway Setting 3" 4 "Headway Setting 4" 5 "Headway Setting 5" 6 "Headway Setting 6" 7 "Headway Setting 7";
VAL_ 880 ACCSnsClnRqdIO 0 "false" 1 "true";
VAL_ 880 ACCTmpUnavlbleIO 0 "false" 1 "true";
VAL_ 880 ACCDrvrSeltdSpdIO 0 "false" 1 "true";
VAL_ 894 RtLwBmFld 0 "false" 1 "true";
VAL_ 894 LftLwBmFld 0 "false" 1 "true";
VAL_ 894 AdvFrntLghtSysIndRq 0 "No Indication" 1 "Indication 1" 2 "Indication 2" 3 "Indication 3" 4 "Indication 4" 5 "Indication 5" 6 "Indication 6" 7 "Indication 7";
VAL_ 894 HdLtLvlFlrIO 0 "false" 1 "true";
VAL_ 298 SpdLmtrSttngTyp 0 "Manual" 1 "Auto";
VAL_ 298 TCSysDisSwAtv 0 "false" 1 "true";
VAL_ 298 AutoMdSpdLmtCnfrmd 0 "false" 1 "true";
VAL_ 298 ChmAct 0 "false" 1 "true";
VAL_ 298 DDAjrSwAtvM 0 "Don't Use Data" 1 "Use Data";
VAL_ 298 CrshAlrtDrvrSlctdType 0 "Chime" 1 "Seat";
VAL_ 298 PsSbltAtcV 0 "Valid" 1 "Invalid";
VAL_ 298 PsSbltAtc 0 "false" 1 "true";
VAL_ 298 TrlrBrkDsplyAct 0 "false" 1 "true";
VAL_ 298 RdSpdCatType 0 "all speed categories > 130 km/h" 1 "all speed categories 81-130 km/h" 2 "all speed categories 51-80 km/h" 3 "all speed categories 0 - 50 km/h";
VAL_ 298 LnCat 0 "no info available" 1 "One lane" 2 "Two Or Three Lanes" 3 "Four Or More Lanes";
VAL_ 298 FncRdClass 0 "LOCAL (Residential Road)" 1 "SFREEWAY" 2 "FREEWAY" 3 "PED-MALL" 4 "HIGHWAY" 5 "ARTERIAL" 6 "ALLEY" 7 "COLLECTOR";
VAL_ 298 SprtLnRd 0 "false" 1 "true";
VAL_ 298 CntrldAccRd 0 "false" 1 "true";
VAL_ 298 BldUpArDet 0 "false" 1 "true";
VAL_ 298 MpDataAvlbl 0 "false" 1 "true";
VAL_ 298 SusCustStngReq 0 "No Action" 1 "Performance Mode 1" 2 "Performance Mode 2" 3 "Performance Mode 3" 4 "Performance Mode 4" 5 "Performance Mode 5" 6 "Performance Mode 6" 7 "Auto";
VAL_ 298 StrCustStngReq 0 "No Action" 1 "Performance Mode 1" 2 "Performance Mode 2" 3 "Performance Mode 3" 4 "Performance Mode 4" 5 "Performance Mode 5" 6 "Performance Mode 6" 7 "Auto";
VAL_ 298 RstrCustFctrDef 0 "No Action" 1 "Restore Defaults";
VAL_ 298 DrvlnCustStngReq 0 "No Action" 1 "Performance Mode 1" 2 "Performance Mode 2" 3 "Performance Mode 3" 4 "Performance Mode 4" 5 "Performance Mode 5" 6 "Performance Mode 6" 7 "Auto";
VAL_ 298 ChmMstrVDA 0 "VirtualDeviceUnavailable" 1 "VirtualDeviceAvailable";
VAL_ 298 IPCVDA 0 "VirtualDeviceUnavailable" 1 "VirtualDeviceAvailable";
VAL_ 298 HeadUpDispVDA 0 "VirtualDeviceUnavailable" 1 "VirtualDeviceAvailable";
VAL_ 298 HapticSeatVDA 0 "VirtualDeviceUnavailable" 1 "VirtualDeviceAvailable";
VAL_ 298 RRDoorAjarSwAct 0 "false" 1 "true";
VAL_ 298 PDAjrSwAtv 0 "false" 1 "true";
VAL_ 298 DDAjrSwAtv 0 "false" 1 "true";
VAL_ 298 TrlrHWIntrfcVDA 0 "VirtualDeviceUnavailable" 1 "VirtualDeviceAvailable";
VAL_ 298 DrId 0 "Driver #1" 1 "Driver #2" 2 "Driver #3" 3 "Driver #4" 4 "Driver #5" 5 "Driver #6" 6 "Driver #7" 7 "Unknown";
VAL_ 298 EnrgMgtLdShdRq 0 "No Load Shedding" 1 "Load Shed Level 1" 2 "Load Shed Level 2" 3 "Load Shed Level 3" 4 "Load Shed Level 4";
VAL_ 298 DrSbltAtcV 0 "Valid" 1 "Invalid";
VAL_ 298 TrlrHtchSwAtv 0 "false" 1 "true";
VAL_ 298 TreInfMonSysRstReq 0 "false" 1 "true";
VAL_ 298 HUDActv 0 "false" 1 "true";
VAL_ 298 BatVltV 0 "Valid" 1 "Invalid";
VAL_ 298 RLDoorAjarSwAct 0 "false" 1 "true";
VAL_ 298 DrSbltAtc 0 "false" 1 "true";
VAL_ 1322 TireRRPrsV 0 "Valid" 1 "Invalid";
VAL_ 1322 TireRRPrsStat 0 "Unknown" 1 "Nominal" 2 "Low - Service Now" 3 "Low" 4 "Low - Extended Mobility" 5 "High";
VAL_ 1322 TireRFPrsV 0 "Valid" 1 "Invalid";
VAL_ 1322 TireRFPrsStat 0 "Unknown" 1 "Nominal" 2 "Low - Service Now" 3 "Low" 4 "Low - Extended Mobility" 5 "High";
VAL_ 1322 TireLRPrsV 0 "Valid" 1 "Invalid";
VAL_ 1322 TireLRPrsStat 0 "Unknown" 1 "Nominal" 2 "Low - Service Now" 3 "Low" 4 "Low - Extended Mobility" 5 "High";
VAL_ 1322 TireLFPrsV 0 "Valid" 1 "Invalid";
VAL_ 1322 TireLFPrsStat 0 "Unknown" 1 "Nominal" 2 "Low - Service Now" 3 "Low" 4 "Low - Extended Mobility" 5 "High";
VAL_ 288 VehOdoV 0 "Valid" 1 "Invalid";
VAL_ 485 StrWhAngGrdV 0 "Valid" 1 "Invalid";
VAL_ 485 StrWhAngGrdMsk 0 "Don't Use Data" 1 "Use Data";
VAL_ 485 StrWhAngMsk 0 "Don't Use Data" 1 "Use Data";
VAL_ 485 StrWhlAngSenTyp 0 "Type 1" 1 "Type 2" 2 "Type 3" 3 "Type 4";
VAL_ 485 StrWhlAngSenCalStat 0 "Unknown" 1 "Estimated" 2 "Calibrated";
VAL_ 485 StrWhAngV 0 "Valid" 1 "Invalid";
VAL_ 1001 DistRollCntAvgDrvnSrc 0 "Transmission Output Speed" 1 "Wheel Speed";
VAL_ 1001 VehSpdAvgDrvnSrc 0 "Transmission Output Speed" 1 "Wheel Speed";
VAL_ 1001 DstRolCntAvgNonDrvnV 0 "Valid" 1 "Invalid";
VAL_ 1001 DstRolCntAvNDrRstOc 0 "false" 1 "true";
VAL_ 1001 DistRollCntAvgDrvnV 0 "Valid" 1 "Invalid";
VAL_ 1001 DstRolCntAvgDrnRstOc 0 "false" 1 "true";
VAL_ 1001 VehSpdAvgNDrvnV 0 "Valid" 1 "Invalid";
VAL_ 1001 VehSpdAvgDrvnV 0 "Valid" 1 "Invalid";
VAL_ 804 CompOvrhtIndOn 0 "false" 1 "true";
VAL_ 804 VehHghtStatV 0 "Valid" 1 "Invalid";
VAL_ 804 VehHghtStat 0 "Unknown" 1 "Normal Design Ride Height" 2 "Aerodynamic Height" 3 "Kneeling Height" 4 "Maximum Height";
VAL_ 804 SrvLevSysIO 0 "false" 1 "true";
VAL_ 804 VehOvrLdIndOn 0 "false" 1 "true";
VAL_ 842 WhlRotDrctnlSRtNDrvn 0 "Unknown" 1 "Forward" 2 "Reverse" 3 "Not Supported" 4 "Failed" 5 "Reserved 1" 6 "Reserved 2" 7 "Reserved 3";
VAL_ 842 WhlRotDrctnlStLfNDrvn 0 "Unknown" 1 "Forward" 2 "Reverse" 3 "Not Supported" 4 "Failed" 5 "Reserved 1" 6 "Reserved 2" 7 "Reserved 3";
VAL_ 842 WhlGrndVlctyRtNnDrvnV 0 "Valid" 1 "Invalid";
VAL_ 842 WhlGrndVlctyLftNnDrvnV 0 "Valid" 1 "Invalid";
VAL_ 1241 FSERDTC_SysDes 0 "P0-Powertrain Codes SAE Controlled" 1 "P1-Powertrain Codes MFG Controlled" 2 "P2-Powertrain Codes Reserved" 3 "P3-Powertrain Codes Reserved" 4 "C0-Chassis Codes SAE Controlled" 5 "C1-Chassis Codes MFG Controlled" 6 "C2-Chassis Codes Reserved" 7 "C3-Chassis Codes Reserved" 8 "B0-Body Codes SAE Controlled" 9 "B1-Body Codes MFG Controlled" 10 "B2-Body Codes Reserved" 11 "B3-Body Codes Reserved" 12 "U0-Network Codes SAE Controlled" 13 "U1-Network Codes MFG Controlled" 14 "U2-Network Codes Reserved" 15 "U3-Network Codes Reserved";
VAL_ 1241 FuelSysEmsRldMlfAtv 0 "false" 1 "true";
VAL_ 491 ExhPrsRgVlv2Pos 0 "Open" 1 "Closed";
VAL_ 491 ExhPrsRgVlv2PosV 0 "Valid" 1 "Invalid";
VAL_ 491 ExhPrsRgVlvPosV 0 "Valid" 1 "Invalid";
VAL_ 491 ExhPrsRgVlvPos 0 "Open" 1 "Closed";
VAL_ 491 FuelSysEstPressDlvrdV 0 "Valid" 1 "Invalid";
VAL_ 1019 FuelAlchlCompAdptnPrg 0 "false" 1 "true";
VAL_ 1019 FuelLvlEmnsRelStat 0 "Valid" 1 "Invalid";
VAL_ 1019 EmnsRelFuelLvlLw 0 "false" 1 "true";
VAL_ 1019 EngFuelCntlState 0 "Open Loop" 1 "Non-Stoichiometric Closed Loop" 2 "Stoichiometric Closed Loop";
VAL_ 1019 FuelAlcoholCompV 0 "Valid" 1 "Invalid";
VAL_ 493 EngRunng 0 "false" 1 "true";
VAL_ 493 FlPmpEDscOtptCmdSta 0 "Fuel Pump Disabled" 1 "Fuel Pump Enabled";
VAL_ 493 FuelCntlSysFltPrsnt 0 "false" 1 "true";
VAL_ 401 EngTrqTrnRqTmpFld 0 "false" 1 "true";
VAL_ 401 EngTrqTrnRqLmtd 0 "false" 1 "true";
VAL_ 401 TrnsEngSpdReqFld 0 "false" 1 "true";
VAL_ 401 EngTrqTnsRqFld 0 "false" 1 "true";
VAL_ 401 EngTrqRdnFld 0 "false" 1 "true";
VAL_ 401 EngNTrnsRegStdyStTqV 0 "Valid" 1 "Invalid";
VAL_ 401 EngAirflwStdyStTorqV 0 "Valid" 1 "Invalid";
VAL_ 401 AccKdwnAtv 0 "false" 1 "true";
VAL_ 401 AccPosV 0 "Valid" 1 "Invalid";
VAL_ 401 EngActStdyStTorqV 0 "Valid" 1 "Invalid";
VAL_ 707 CSTATRS_ReqStat 0 "No Request" 1 "Request Honored" 2 "Lost Arbitration" 3 "Serial Data Failure Temporary" 4 "Serial Data Failure Permanent" 5 "Control System Failure Temporary" 6 "Control System Failure Permanent";
VAL_ 707 CSTATRS_LmtgStat 0 "Not Limited" 1 "Rate Limited" 2 "Value Limited" 3 "Rate and Value Limited";
VAL_ 707 EngManfldAbsPrsV 0 "Valid" 1 "Invalid";
VAL_ 707 EngTrqMinExtRngV 0 "Valid" 1 "Invalid";
VAL_ 707 EngTrqMaxExtRngV 0 "Valid" 1 "Invalid";
VAL_ 1265 PTSysHzrdLghtReq 0 "false" 1 "true";
VAL_ 1265 EngOffTmPTV 0 "Valid" 1 "Invalid";
VAL_ 1265 EngOffTmPTM 0 "Don't Use Data" 1 "Use Data";
CM_ SG_ 1917 DTCI_DTCFaultType_77D "Based on Powertrain definition.  Not expected to be supported by all devices.";
CM_ SG_ 1917 DTCI_DTCFailType_77D "Assigned per GMW3110, Appendix E";
CM_ SG_ 1917 DTCI_DTCSource_77D "This shall be equal to the Diagnostic Address of the transmittting device.";
CM_ SG_ 1918 DTCI_DTCFaultType_77E "Based on Powertrain definition.  Not expected to be supported by all devices.";
CM_ SG_ 1918 DTCI_DTCFailType_77E "Assigned per GMW3110, Appendix E";
CM_ SG_ 1918 DTCI_DTCSource_77E "This shall be equal to the Diagnostic Address of the transmittting device.";
CM_ SG_ 1919 DTCI_DTCFaultType_77F "Based on Powertrain definition.  Not expected to be supported by all devices.";
CM_ SG_ 1919 DTCI_DTCFailType_77F "Assigned per GMW3110, Appendix E";
CM_ SG_ 1919 DTCI_DTCSource_77F "This shall be equal to the Diagnostic Address of the transmittting device.";
CM_ SG_ 499 PFTrnsTUDSecSwSt "Added 2006 Nov 10 according to CR1112";
CM_ BO_ 1282 "ALC will not (and cannot) be present on vehicles where the ICCM will transmit HS $502. Currently, this is only envisioned for high-performance vehicles.";
CM_ SG_ 1921 DTCI_DTCSource_781 "This shall be equal to the Diagnostic Address of the transmittting device.";
CM_ SG_ 1921 DTCI_DTCFaultType_781 "Based on Powertrain definition.  Not expected to be supported by all devices.";
CM_ SG_ 1921 DTCI_DTCFailType_781 "Assigned per GMW3110, Appendix E";
CM_ SG_ 1920 DTCI_DTCSource_780 "This shall be equal to the Diagnostic Address of the transmittting device.";
CM_ SG_ 1920 DTCI_DTCFaultType_780 "Based on Powertrain definition.  Not expected to be supported by all devices.";
CM_ SG_ 1920 DTCI_DTCFailType_780 "Assigned per GMW3110, Appendix E";
CM_ SG_ 1914 DTCI_DTCFaultType_77A "Based on Powertrain definition.  Not expected to be supported by all devices.";
CM_ SG_ 1914 DTCI_DTCFailType_77A "Assigned per GMW3110, Appendix E";
CM_ SG_ 1914 DTCI_DTCSource_77A "This shall be equal to the Diagnostic Address of the transmittting device.";
CM_ SG_ 1911 DTCI_DTCFaultType_777 "Based on Powertrain definition.  Not expected to be supported by all devices.";
CM_ SG_ 1911 DTCI_DTCFailType_777 "Assigned per GMW3110, Appendix E";
CM_ SG_ 1911 DTCI_DTCSource_777 "This shall be equal to the Diagnostic Address of the transmittting device.";
CM_ SG_ 1906 DTCI_DTCFaultType_772 "Based on Powertrain definition.  Not expected to be supported by all devices.";
CM_ SG_ 1906 DTCI_DTCFailType_772 "Assigned per GMW3110, Appendix E";
CM_ SG_ 1906 DTCI_DTCSource_772 "This shall be equal to the Diagnostic Address of the transmittting device.";
CM_ SG_ 1907 DTCI_DTCFaultType_773 "Based on Powertrain definition.  Not expected to be supported by all devices.";
CM_ SG_ 1907 DTCI_DTCFailType_773 "Assigned per GMW3110, Appendix E";
CM_ SG_ 1907 DTCI_DTCSource_773 "This shall be equal to the Diagnostic Address of the transmittting device.";
CM_ SG_ 1915 DTCI_DTCFaultType_77B "Based on Powertrain definition.  Not expected to be supported by all devices.";
CM_ SG_ 1915 DTCI_DTCFailType_77B "Assigned per GMW3110, Appendix E";
CM_ SG_ 1915 DTCI_DTCSource_77B "This shall be equal to the Diagnostic Address of the transmittting device.";
CM_ BO_ 880 "Note that the ACC algorithm will transmit this message at a 50 ms periodic rate and the EOCM algorithm will transmit this message at a 40 ms periodic rate";
CM_ SG_ 880 ACCHdwyStg "Headway is the  time which results from dividing the following distance (or gap) between vehicles by the vehicle speed.  This setting allows the driver to choose a Headway Setting without actually knowing the value of this time.";
CM_ SG_ 298 DrId "Driver 8 changed to Unknown on 3/30/99";
CM_ SG_ 1300 VehIdNmDig2_9 "Desc: 8 ASCII Characters";
CM_ BO_ 485 "6443-Power Steering Indication On in this frame not used by GlobalA /JD";
CM_ BO_ 491 "Changed for PPEI 3.6 - Should be gated from FSCM";
CM_ SG_ 401 EngTrqTnsRqFld "Indicates that the Engine controller will not honor the torque request from the Transmission Controller due to a failure in the Rolling count, protection value, etc.";
CM_ SG_ 401 EngNTrnsRegStdyStTqV "ETEI 3.1";
CM_ SG_ 401 EngNTrnsRegStdyStTq "ETEI 3.1";
CM_ SG_ 401 EngAirflwStdyStTorqV "ETEI 3.1";
CM_ SG_ 401 EngAirflwStdyStTorq "ETEI 3.1";
CM_ SG_ 401 EngActStdyStTorqV "ETEI 3.1";
CM_ SG_ 401 EngActStdyStTorq "ETEI 3.1";
BA_DEF_ SG_ "VNSigSLHS_VNReq" ENUM "No","Yes";
BA_DEF_ SG_ "VNSigSLHSSharedDiagnostic" ENUM "No","Yes";
BA_DEF_ SG_ "SignalType" STRING;
BA_DEF_ SG_ "PacketOrder" INT 0 65535;
BA_DEF_ SG_ "SignalLongName" STRING;
BA_DEF_ SG_ "GenSigStartValue" INT 0 65535;
BA_DEF_ SG_ "VNSigAllNodes" ENUM "No","Yes";
BA_DEF_ SG_ "GenSigDeltaValue" INT 0 0;
BA_DEF_ SG_ "GenSigSendType" ENUM "not used","not used","not used","not used","not used","not used","not used","NoSigSendType","not used","not used","OnAnyChange","OnChangeIfActive","OnDelta";
BA_DEF_ SG_ "GenSigSendOnInit" ENUM "Not Initialized","Application","Handler";
BA_DEF_ BO_ "AppGenMsgCycleTime" INT 0 0;
BA_DEF_ BO_ "GenMsgILSupport" ENUM "No","Yes";
BA_DEF_ BO_ "TpApplType" STRING;
BA_DEF_ BO_ "Prio" INT 0 7;
BA_DEF_ BO_ "MessageSubnet" ENUM "LS","MS","HS","CE","PE","HV","FO";
BA_DEF_ BO_ "DiagState" ENUM "No","Yes";
BA_DEF_ BO_ "GenMsgDelayTime" INT 0 100000;
BA_DEF_ BO_ "GenMsgCycleTime" INT 0 100000;
BA_DEF_ BO_ "GenMsgSendType" ENUM "cyclicX","spontanX","cyclicIfActiveX","spontanWithDelay","cyclicAndSpontanX","cyclicAndSpontanWithDelay","spontanWithRepitition","cyclicIfActiveAndSpontanWD";
BA_DEF_ BO_ "DiagResponse" ENUM "No","Yes";
BA_DEF_ BO_ "DiagRequest" ENUM "No","Yes";
BA_DEF_ BO_ "NmMessage" ENUM "No","Yes";
BA_DEF_DEF_ "VNSigSLHS_VNReq" "No";
BA_DEF_DEF_ "VNSigSLHSSharedDiagnostic" "No";
BA_DEF_DEF_ "SignalType" "";
BA_DEF_DEF_ "PacketOrder" 0;
BA_DEF_DEF_ "SignalLongName" "";
BA_DEF_DEF_ "GenSigStartValue" 0;
BA_DEF_DEF_ "VNSigAllNodes" "No";
BA_DEF_DEF_ "GenSigDeltaValue" 0;
BA_DEF_DEF_ "GenSigSendType" "NoSigSendType";
BA_DEF_DEF_ "GenSigSendOnInit" "Not Initialized";
BA_DEF_DEF_ "AppGenMsgCycleTime" 0;
BA_DEF_DEF_ "GenMsgILSupport" "Yes";
BA_DEF_DEF_ "TpApplType" "";
BA_DEF_DEF_ "Prio" 4;
BA_DEF_DEF_ "MessageSubnet" "FO";
BA_DEF_DEF_ "DiagState" "No";
BA_DEF_DEF_ "GenMsgDelayTime" 0;
BA_DEF_DEF_ "GenMsgCycleTime" 0;
BA_DEF_DEF_ "GenMsgSendType" "spontanX";
BA_DEF_DEF_ "DiagResponse" "No";
BA_DEF_DEF_ "DiagRequest" "No";
BA_DEF_DEF_ "NmMessage" "No";
BA_ "Prio" BO_ 1917 6;
BA_ "GenMsgSendType" BO_ 1917 0;
BA_ "GenMsgCycleTime" BO_ 1917 1000;
BA_ "MessageSubnet" BO_ 1917 2;
BA_ "VNSigAllNodes" SG_ 1917 DTCI_DTCFaultType_77D 1;
BA_ "PacketOrder" SG_ 1917 DTCI_DTCFaultType_77D 20;
BA_ "SignalLongName" SG_ 1917 DTCI_DTCFaultType_77D "Diagnostic Trouble Code Information Extended 77D : Diagnostic Trouble Code Fault Type";
BA_ "SignalType" SG_ 1917 DTCI_DTCFaultType_77D "ENM";
BA_ "VNSigAllNodes" SG_ 1917 DTCI_CodeSupported_77D 1;
BA_ "PacketOrder" SG_ 1917 DTCI_CodeSupported_77D 19;
BA_ "SignalLongName" SG_ 1917 DTCI_CodeSupported_77D "Diagnostic Trouble Code Information Extended 77D : Code Supported";
BA_ "SignalType" SG_ 1917 DTCI_CodeSupported_77D "BLN";
BA_ "VNSigAllNodes" SG_ 1917 DTCI_CurrentStatus_77D 1;
BA_ "PacketOrder" SG_ 1917 DTCI_CurrentStatus_77D 18;
BA_ "SignalLongName" SG_ 1917 DTCI_CurrentStatus_77D "Diagnostic Trouble Code Information Extended 77D : Current Status";
BA_ "SignalType" SG_ 1917 DTCI_CurrentStatus_77D "BLN";
BA_ "VNSigAllNodes" SG_ 1917 DTCI_TstNPsdCdClrdSt_77D 1;
BA_ "PacketOrder" SG_ 1917 DTCI_TstNPsdCdClrdSt_77D 17;
BA_ "SignalLongName" SG_ 1917 DTCI_TstNPsdCdClrdSt_77D "Diagnostic Trouble Code Information Extended 77D : Test Not Passed Since Code Cleared Status";
BA_ "SignalType" SG_ 1917 DTCI_TstNPsdCdClrdSt_77D "BLN";
BA_ "VNSigAllNodes" SG_ 1917 DTCI_TstFldCdClrdStat_77D 1;
BA_ "PacketOrder" SG_ 1917 DTCI_TstFldCdClrdStat_77D 16;
BA_ "SignalLongName" SG_ 1917 DTCI_TstFldCdClrdStat_77D "Diagnostic Trouble Code Information Extended 77D : Test Failed Since Code Cleared Status";
BA_ "SignalType" SG_ 1917 DTCI_TstFldCdClrdStat_77D "BLN";
BA_ "VNSigAllNodes" SG_ 1917 DTCI_HistStat_77D 1;
BA_ "PacketOrder" SG_ 1917 DTCI_HistStat_77D 15;
BA_ "SignalLongName" SG_ 1917 DTCI_HistStat_77D "Diagnostic Trouble Code Information Extended 77D : History Status";
BA_ "SignalType" SG_ 1917 DTCI_HistStat_77D "BLN";
BA_ "VNSigAllNodes" SG_ 1917 DTCI_TstNPsdPwrUpSt_77D 1;
BA_ "PacketOrder" SG_ 1917 DTCI_TstNPsdPwrUpSt_77D 14;
BA_ "SignalLongName" SG_ 1917 DTCI_TstNPsdPwrUpSt_77D "Diagnostic Trouble Code Information Extended 77D : Test Not Passed Since Power Up Status";
BA_ "SignalType" SG_ 1917 DTCI_TstNPsdPwrUpSt_77D "BLN";
BA_ "VNSigAllNodes" SG_ 1917 DTCI_TstFldPwrUpSt_77D 1;
BA_ "PacketOrder" SG_ 1917 DTCI_TstFldPwrUpSt_77D 13;
BA_ "SignalLongName" SG_ 1917 DTCI_TstFldPwrUpSt_77D "Diagnostic Trouble Code Information Extended 77D : Test Failed Since Power Up Status";
BA_ "SignalType" SG_ 1917 DTCI_TstFldPwrUpSt_77D "BLN";
BA_ "VNSigAllNodes" SG_ 1917 DTCI_WrnIndRqdSt_77D 1;
BA_ "PacketOrder" SG_ 1917 DTCI_WrnIndRqdSt_77D 12;
BA_ "SignalLongName" SG_ 1917 DTCI_WrnIndRqdSt_77D "Diagnostic Trouble Code Information Extended 77D : Warning Indicator Requested Status";
BA_ "SignalType" SG_ 1917 DTCI_WrnIndRqdSt_77D "BLN";
BA_ "VNSigAllNodes" SG_ 1917 DTCI_DTCFailType_77D 1;
BA_ "PacketOrder" SG_ 1917 DTCI_DTCFailType_77D 11;
BA_ "SignalLongName" SG_ 1917 DTCI_DTCFailType_77D "Diagnostic Trouble Code Information Extended 77D : Diagnostic Trouble Code Failure Type";
BA_ "SignalType" SG_ 1917 DTCI_DTCFailType_77D "UNM";
BA_ "VNSigAllNodes" SG_ 1917 DTCI_DTCNumber_77D 1;
BA_ "PacketOrder" SG_ 1917 DTCI_DTCNumber_77D 10;
BA_ "SignalLongName" SG_ 1917 DTCI_DTCNumber_77D "Diagnostic Trouble Code Information Extended 77D : Diagnostic Trouble Code Number";
BA_ "SignalType" SG_ 1917 DTCI_DTCNumber_77D "UNM";
BA_ "VNSigAllNodes" SG_ 1917 DTCI_DTCSource_77D 1;
BA_ "PacketOrder" SG_ 1917 DTCI_DTCSource_77D 9;
BA_ "SignalLongName" SG_ 1917 DTCI_DTCSource_77D "Diagnostic Trouble Code Information Extended 77D : Diagnostic Trouble Code Source";
BA_ "SignalType" SG_ 1917 DTCI_DTCSource_77D "UNM";
BA_ "VNSigAllNodes" SG_ 1917 DTCI_DTCTriggered_77D 1;
BA_ "PacketOrder" SG_ 1917 DTCI_DTCTriggered_77D 8;
BA_ "SignalLongName" SG_ 1917 DTCI_DTCTriggered_77D "Diagnostic Trouble Code Information Extended 77D : Diagnostic Trouble Code Triggered";
BA_ "SignalType" SG_ 1917 DTCI_DTCTriggered_77D "BLN";
BA_ "VNSigAllNodes" SG_ 1917 DTCIUnused7_77D 1;
BA_ "PacketOrder" SG_ 1917 DTCIUnused7_77D 7;
BA_ "SignalLongName" SG_ 1917 DTCIUnused7_77D "Diagnostic Trouble Code Information Extended 77D : Unused 7";
BA_ "SignalType" SG_ 1917 DTCIUnused7_77D "BLN";
BA_ "VNSigAllNodes" SG_ 1917 DTCIUnused6_77D 1;
BA_ "PacketOrder" SG_ 1917 DTCIUnused6_77D 6;
BA_ "SignalLongName" SG_ 1917 DTCIUnused6_77D "Diagnostic Trouble Code Information Extended 77D : Unused 6";
BA_ "SignalType" SG_ 1917 DTCIUnused6_77D "BLN";
BA_ "VNSigAllNodes" SG_ 1917 DTCIUnused5_77D 1;
BA_ "PacketOrder" SG_ 1917 DTCIUnused5_77D 5;
BA_ "SignalLongName" SG_ 1917 DTCIUnused5_77D "Diagnostic Trouble Code Information Extended 77D : Unused 5";
BA_ "SignalType" SG_ 1917 DTCIUnused5_77D "BLN";
BA_ "VNSigAllNodes" SG_ 1917 DTCIUnused4_77D 1;
BA_ "PacketOrder" SG_ 1917 DTCIUnused4_77D 4;
BA_ "SignalLongName" SG_ 1917 DTCIUnused4_77D "Diagnostic Trouble Code Information Extended 77D : Unused 4";
BA_ "SignalType" SG_ 1917 DTCIUnused4_77D "BLN";
BA_ "VNSigAllNodes" SG_ 1917 DTCIUnused3_77D 1;
BA_ "PacketOrder" SG_ 1917 DTCIUnused3_77D 3;
BA_ "SignalLongName" SG_ 1917 DTCIUnused3_77D "Diagnostic Trouble Code Information Extended 77D : Unused 3";
BA_ "SignalType" SG_ 1917 DTCIUnused3_77D "BLN";
BA_ "VNSigAllNodes" SG_ 1917 DTCIUnused2_77D 1;
BA_ "PacketOrder" SG_ 1917 DTCIUnused2_77D 2;
BA_ "SignalLongName" SG_ 1917 DTCIUnused2_77D "Diagnostic Trouble Code Information Extended 77D : Unused 2";
BA_ "SignalType" SG_ 1917 DTCIUnused2_77D "BLN";
BA_ "VNSigAllNodes" SG_ 1917 DTCIUnused1_77D 1;
BA_ "PacketOrder" SG_ 1917 DTCIUnused1_77D 1;
BA_ "SignalLongName" SG_ 1917 DTCIUnused1_77D "Diagnostic Trouble Code Information Extended 77D : Unused 1";
BA_ "SignalType" SG_ 1917 DTCIUnused1_77D "BLN";
BA_ "Prio" BO_ 1918 6;
BA_ "GenMsgSendType" BO_ 1918 0;
BA_ "GenMsgCycleTime" BO_ 1918 1000;
BA_ "MessageSubnet" BO_ 1918 2;
BA_ "VNSigAllNodes" SG_ 1918 DTCI_DTCFaultType_77E 1;
BA_ "PacketOrder" SG_ 1918 DTCI_DTCFaultType_77E 20;
BA_ "SignalLongName" SG_ 1918 DTCI_DTCFaultType_77E "Diagnostic Trouble Code Information Extended 77E : Diagnostic Trouble Code Fault Type";
BA_ "SignalType" SG_ 1918 DTCI_DTCFaultType_77E "ENM";
BA_ "VNSigAllNodes" SG_ 1918 DTCI_CodeSupported_77E 1;
BA_ "PacketOrder" SG_ 1918 DTCI_CodeSupported_77E 19;
BA_ "SignalLongName" SG_ 1918 DTCI_CodeSupported_77E "Diagnostic Trouble Code Information Extended 77E : Code Supported";
BA_ "SignalType" SG_ 1918 DTCI_CodeSupported_77E "BLN";
BA_ "VNSigAllNodes" SG_ 1918 DTCI_CurrentStatus_77E 1;
BA_ "PacketOrder" SG_ 1918 DTCI_CurrentStatus_77E 18;
BA_ "SignalLongName" SG_ 1918 DTCI_CurrentStatus_77E "Diagnostic Trouble Code Information Extended 77E : Current Status";
BA_ "SignalType" SG_ 1918 DTCI_CurrentStatus_77E "BLN";
BA_ "VNSigAllNodes" SG_ 1918 DTCI_TstNPsdCdClrdSt_77E 1;
BA_ "PacketOrder" SG_ 1918 DTCI_TstNPsdCdClrdSt_77E 17;
BA_ "SignalLongName" SG_ 1918 DTCI_TstNPsdCdClrdSt_77E "Diagnostic Trouble Code Information Extended 77E : Test Not Passed Since Code Cleared Status";
BA_ "SignalType" SG_ 1918 DTCI_TstNPsdCdClrdSt_77E "BLN";
BA_ "VNSigAllNodes" SG_ 1918 DTCI_TstFldCdClrdStat_77E 1;
BA_ "PacketOrder" SG_ 1918 DTCI_TstFldCdClrdStat_77E 16;
BA_ "SignalLongName" SG_ 1918 DTCI_TstFldCdClrdStat_77E "Diagnostic Trouble Code Information Extended 77E : Test Failed Since Code Cleared Status";
BA_ "SignalType" SG_ 1918 DTCI_TstFldCdClrdStat_77E "BLN";
BA_ "VNSigAllNodes" SG_ 1918 DTCI_HistStat_77E 1;
BA_ "PacketOrder" SG_ 1918 DTCI_HistStat_77E 15;
BA_ "SignalLongName" SG_ 1918 DTCI_HistStat_77E "Diagnostic Trouble Code Information Extended 77E : History Status";
BA_ "SignalType" SG_ 1918 DTCI_HistStat_77E "BLN";
BA_ "VNSigAllNodes" SG_ 1918 DTCI_TstNPsdPwrUpSt_77E 1;
BA_ "PacketOrder" SG_ 1918 DTCI_TstNPsdPwrUpSt_77E 14;
BA_ "SignalLongName" SG_ 1918 DTCI_TstNPsdPwrUpSt_77E "Diagnostic Trouble Code Information Extended 77E : Test Not Passed Since Power Up Status";
BA_ "SignalType" SG_ 1918 DTCI_TstNPsdPwrUpSt_77E "BLN";
BA_ "VNSigAllNodes" SG_ 1918 DTCI_TstFldPwrUpSt_77E 1;
BA_ "PacketOrder" SG_ 1918 DTCI_TstFldPwrUpSt_77E 13;
BA_ "SignalLongName" SG_ 1918 DTCI_TstFldPwrUpSt_77E "Diagnostic Trouble Code Information Extended 77E : Test Failed Since Power Up Status";
BA_ "SignalType" SG_ 1918 DTCI_TstFldPwrUpSt_77E "BLN";
BA_ "VNSigAllNodes" SG_ 1918 DTCI_WrnIndRqdSt_77E 1;
BA_ "PacketOrder" SG_ 1918 DTCI_WrnIndRqdSt_77E 12;
BA_ "SignalLongName" SG_ 1918 DTCI_WrnIndRqdSt_77E "Diagnostic Trouble Code Information Extended 77E : Warning Indicator Requested Status";
BA_ "SignalType" SG_ 1918 DTCI_WrnIndRqdSt_77E "BLN";
BA_ "VNSigAllNodes" SG_ 1918 DTCI_DTCFailType_77E 1;
BA_ "PacketOrder" SG_ 1918 DTCI_DTCFailType_77E 11;
BA_ "SignalLongName" SG_ 1918 DTCI_DTCFailType_77E "Diagnostic Trouble Code Information Extended 77E : Diagnostic Trouble Code Failure Type";
BA_ "SignalType" SG_ 1918 DTCI_DTCFailType_77E "UNM";
BA_ "VNSigAllNodes" SG_ 1918 DTCI_DTCNumber_77E 1;
BA_ "PacketOrder" SG_ 1918 DTCI_DTCNumber_77E 10;
BA_ "SignalLongName" SG_ 1918 DTCI_DTCNumber_77E "Diagnostic Trouble Code Information Extended 77E : Diagnostic Trouble Code Number";
BA_ "SignalType" SG_ 1918 DTCI_DTCNumber_77E "UNM";
BA_ "VNSigAllNodes" SG_ 1918 DTCI_DTCSource_77E 1;
BA_ "PacketOrder" SG_ 1918 DTCI_DTCSource_77E 9;
BA_ "SignalLongName" SG_ 1918 DTCI_DTCSource_77E "Diagnostic Trouble Code Information Extended 77E : Diagnostic Trouble Code Source";
BA_ "SignalType" SG_ 1918 DTCI_DTCSource_77E "UNM";
BA_ "VNSigAllNodes" SG_ 1918 DTCI_DTCTriggered_77E 1;
BA_ "PacketOrder" SG_ 1918 DTCI_DTCTriggered_77E 8;
BA_ "SignalLongName" SG_ 1918 DTCI_DTCTriggered_77E "Diagnostic Trouble Code Information Extended 77E : Diagnostic Trouble Code Triggered";
BA_ "SignalType" SG_ 1918 DTCI_DTCTriggered_77E "BLN";
BA_ "VNSigAllNodes" SG_ 1918 DTCIUnused7_77E 1;
BA_ "PacketOrder" SG_ 1918 DTCIUnused7_77E 7;
BA_ "SignalLongName" SG_ 1918 DTCIUnused7_77E "Diagnostic Trouble Code Information Extended 77E : Unused 7";
BA_ "SignalType" SG_ 1918 DTCIUnused7_77E "BLN";
BA_ "VNSigAllNodes" SG_ 1918 DTCIUnused6_77E 1;
BA_ "PacketOrder" SG_ 1918 DTCIUnused6_77E 6;
BA_ "SignalLongName" SG_ 1918 DTCIUnused6_77E "Diagnostic Trouble Code Information Extended 77E : Unused 6";
BA_ "SignalType" SG_ 1918 DTCIUnused6_77E "BLN";
BA_ "VNSigAllNodes" SG_ 1918 DTCIUnused5_77E 1;
BA_ "PacketOrder" SG_ 1918 DTCIUnused5_77E 5;
BA_ "SignalLongName" SG_ 1918 DTCIUnused5_77E "Diagnostic Trouble Code Information Extended 77E : Unused 5";
BA_ "SignalType" SG_ 1918 DTCIUnused5_77E "BLN";
BA_ "VNSigAllNodes" SG_ 1918 DTCIUnused4_77E 1;
BA_ "PacketOrder" SG_ 1918 DTCIUnused4_77E 4;
BA_ "SignalLongName" SG_ 1918 DTCIUnused4_77E "Diagnostic Trouble Code Information Extended 77E : Unused 4";
BA_ "SignalType" SG_ 1918 DTCIUnused4_77E "BLN";
BA_ "VNSigAllNodes" SG_ 1918 DTCIUnused3_77E 1;
BA_ "PacketOrder" SG_ 1918 DTCIUnused3_77E 3;
BA_ "SignalLongName" SG_ 1918 DTCIUnused3_77E "Diagnostic Trouble Code Information Extended 77E : Unused 3";
BA_ "SignalType" SG_ 1918 DTCIUnused3_77E "BLN";
BA_ "VNSigAllNodes" SG_ 1918 DTCIUnused2_77E 1;
BA_ "PacketOrder" SG_ 1918 DTCIUnused2_77E 2;
BA_ "SignalLongName" SG_ 1918 DTCIUnused2_77E "Diagnostic Trouble Code Information Extended 77E : Unused 2";
BA_ "SignalType" SG_ 1918 DTCIUnused2_77E "BLN";
BA_ "VNSigAllNodes" SG_ 1918 DTCIUnused1_77E 1;
BA_ "PacketOrder" SG_ 1918 DTCIUnused1_77E 1;
BA_ "SignalLongName" SG_ 1918 DTCIUnused1_77E "Diagnostic Trouble Code Information Extended 77E : Unused 1";
BA_ "SignalType" SG_ 1918 DTCIUnused1_77E "BLN";
BA_ "Prio" BO_ 1919 6;
BA_ "GenMsgSendType" BO_ 1919 0;
BA_ "GenMsgCycleTime" BO_ 1919 1000;
BA_ "MessageSubnet" BO_ 1919 2;
BA_ "VNSigAllNodes" SG_ 1919 DTCI_DTCFaultType_77F 1;
BA_ "PacketOrder" SG_ 1919 DTCI_DTCFaultType_77F 20;
BA_ "SignalLongName" SG_ 1919 DTCI_DTCFaultType_77F "Diagnostic Trouble Code Information Extended 77F : Diagnostic Trouble Code Fault Type";
BA_ "SignalType" SG_ 1919 DTCI_DTCFaultType_77F "ENM";
BA_ "VNSigAllNodes" SG_ 1919 DTCI_CodeSupported_77F 1;
BA_ "PacketOrder" SG_ 1919 DTCI_CodeSupported_77F 19;
BA_ "SignalLongName" SG_ 1919 DTCI_CodeSupported_77F "Diagnostic Trouble Code Information Extended 77F : Code Supported";
BA_ "SignalType" SG_ 1919 DTCI_CodeSupported_77F "BLN";
BA_ "VNSigAllNodes" SG_ 1919 DTCI_CurrentStatus_77F 1;
BA_ "PacketOrder" SG_ 1919 DTCI_CurrentStatus_77F 18;
BA_ "SignalLongName" SG_ 1919 DTCI_CurrentStatus_77F "Diagnostic Trouble Code Information Extended 77F : Current Status";
BA_ "SignalType" SG_ 1919 DTCI_CurrentStatus_77F "BLN";
BA_ "VNSigAllNodes" SG_ 1919 DTCI_TstNPsdCdClrdSt_77F 1;
BA_ "PacketOrder" SG_ 1919 DTCI_TstNPsdCdClrdSt_77F 17;
BA_ "SignalLongName" SG_ 1919 DTCI_TstNPsdCdClrdSt_77F "Diagnostic Trouble Code Information Extended 77F : Test Not Passed Since Code Cleared Status";
BA_ "SignalType" SG_ 1919 DTCI_TstNPsdCdClrdSt_77F "BLN";
BA_ "VNSigAllNodes" SG_ 1919 DTCI_TstFldCdClrdStat_77F 1;
BA_ "PacketOrder" SG_ 1919 DTCI_TstFldCdClrdStat_77F 16;
BA_ "SignalLongName" SG_ 1919 DTCI_TstFldCdClrdStat_77F "Diagnostic Trouble Code Information Extended 77F : Test Failed Since Code Cleared Status";
BA_ "SignalType" SG_ 1919 DTCI_TstFldCdClrdStat_77F "BLN";
BA_ "VNSigAllNodes" SG_ 1919 DTCI_HistStat_77F 1;
BA_ "PacketOrder" SG_ 1919 DTCI_HistStat_77F 15;
BA_ "SignalLongName" SG_ 1919 DTCI_HistStat_77F "Diagnostic Trouble Code Information Extended 77F : History Status";
BA_ "SignalType" SG_ 1919 DTCI_HistStat_77F "BLN";
BA_ "VNSigAllNodes" SG_ 1919 DTCI_TstNPsdPwrUpSt_77F 1;
BA_ "PacketOrder" SG_ 1919 DTCI_TstNPsdPwrUpSt_77F 14;
BA_ "SignalLongName" SG_ 1919 DTCI_TstNPsdPwrUpSt_77F "Diagnostic Trouble Code Information Extended 77F : Test Not Passed Since Power Up Status";
BA_ "SignalType" SG_ 1919 DTCI_TstNPsdPwrUpSt_77F "BLN";
BA_ "VNSigAllNodes" SG_ 1919 DTCI_TstFldPwrUpSt_77F 1;
BA_ "PacketOrder" SG_ 1919 DTCI_TstFldPwrUpSt_77F 13;
BA_ "SignalLongName" SG_ 1919 DTCI_TstFldPwrUpSt_77F "Diagnostic Trouble Code Information Extended 77F : Test Failed Since Power Up Status";
BA_ "SignalType" SG_ 1919 DTCI_TstFldPwrUpSt_77F "BLN";
BA_ "VNSigAllNodes" SG_ 1919 DTCI_WrnIndRqdSt_77F 1;
BA_ "PacketOrder" SG_ 1919 DTCI_WrnIndRqdSt_77F 12;
BA_ "SignalLongName" SG_ 1919 DTCI_WrnIndRqdSt_77F "Diagnostic Trouble Code Information Extended 77F : Warning Indicator Requested Status";
BA_ "SignalType" SG_ 1919 DTCI_WrnIndRqdSt_77F "BLN";
BA_ "VNSigAllNodes" SG_ 1919 DTCI_DTCFailType_77F 1;
BA_ "PacketOrder" SG_ 1919 DTCI_DTCFailType_77F 11;
BA_ "SignalLongName" SG_ 1919 DTCI_DTCFailType_77F "Diagnostic Trouble Code Information Extended 77F : Diagnostic Trouble Code Failure Type";
BA_ "SignalType" SG_ 1919 DTCI_DTCFailType_77F "UNM";
BA_ "VNSigAllNodes" SG_ 1919 DTCI_DTCNumber_77F 1;
BA_ "PacketOrder" SG_ 1919 DTCI_DTCNumber_77F 10;
BA_ "SignalLongName" SG_ 1919 DTCI_DTCNumber_77F "Diagnostic Trouble Code Information Extended 77F : Diagnostic Trouble Code Number";
BA_ "SignalType" SG_ 1919 DTCI_DTCNumber_77F "UNM";
BA_ "VNSigAllNodes" SG_ 1919 DTCI_DTCSource_77F 1;
BA_ "PacketOrder" SG_ 1919 DTCI_DTCSource_77F 9;
BA_ "SignalLongName" SG_ 1919 DTCI_DTCSource_77F "Diagnostic Trouble Code Information Extended 77F : Diagnostic Trouble Code Source";
BA_ "SignalType" SG_ 1919 DTCI_DTCSource_77F "UNM";
BA_ "VNSigAllNodes" SG_ 1919 DTCI_DTCTriggered_77F 1;
BA_ "PacketOrder" SG_ 1919 DTCI_DTCTriggered_77F 8;
BA_ "SignalLongName" SG_ 1919 DTCI_DTCTriggered_77F "Diagnostic Trouble Code Information Extended 77F : Diagnostic Trouble Code Triggered";
BA_ "SignalType" SG_ 1919 DTCI_DTCTriggered_77F "BLN";
BA_ "VNSigAllNodes" SG_ 1919 DTCIUnused7_77F 1;
BA_ "PacketOrder" SG_ 1919 DTCIUnused7_77F 7;
BA_ "SignalLongName" SG_ 1919 DTCIUnused7_77F "Diagnostic Trouble Code Information Extended 77F : Unused 7";
BA_ "SignalType" SG_ 1919 DTCIUnused7_77F "BLN";
BA_ "VNSigAllNodes" SG_ 1919 DTCIUnused6_77F 1;
BA_ "PacketOrder" SG_ 1919 DTCIUnused6_77F 6;
BA_ "SignalLongName" SG_ 1919 DTCIUnused6_77F "Diagnostic Trouble Code Information Extended 77F : Unused 6";
BA_ "SignalType" SG_ 1919 DTCIUnused6_77F "BLN";
BA_ "VNSigAllNodes" SG_ 1919 DTCIUnused5_77F 1;
BA_ "PacketOrder" SG_ 1919 DTCIUnused5_77F 5;
BA_ "SignalLongName" SG_ 1919 DTCIUnused5_77F "Diagnostic Trouble Code Information Extended 77F : Unused 5";
BA_ "SignalType" SG_ 1919 DTCIUnused5_77F "BLN";
BA_ "VNSigAllNodes" SG_ 1919 DTCIUnused4_77F 1;
BA_ "PacketOrder" SG_ 1919 DTCIUnused4_77F 4;
BA_ "SignalLongName" SG_ 1919 DTCIUnused4_77F "Diagnostic Trouble Code Information Extended 77F : Unused 4";
BA_ "SignalType" SG_ 1919 DTCIUnused4_77F "BLN";
BA_ "VNSigAllNodes" SG_ 1919 DTCIUnused3_77F 1;
BA_ "PacketOrder" SG_ 1919 DTCIUnused3_77F 3;
BA_ "SignalLongName" SG_ 1919 DTCIUnused3_77F "Diagnostic Trouble Code Information Extended 77F : Unused 3";
BA_ "SignalType" SG_ 1919 DTCIUnused3_77F "BLN";
BA_ "VNSigAllNodes" SG_ 1919 DTCIUnused2_77F 1;
BA_ "PacketOrder" SG_ 1919 DTCIUnused2_77F 2;
BA_ "SignalLongName" SG_ 1919 DTCIUnused2_77F "Diagnostic Trouble Code Information Extended 77F : Unused 2";
BA_ "SignalType" SG_ 1919 DTCIUnused2_77F "BLN";
BA_ "VNSigAllNodes" SG_ 1919 DTCIUnused1_77F 1;
BA_ "PacketOrder" SG_ 1919 DTCIUnused1_77F 1;
BA_ "SignalLongName" SG_ 1919 DTCIUnused1_77F "Diagnostic Trouble Code Information Extended 77F : Unused 1";
BA_ "SignalType" SG_ 1919 DTCIUnused1_77F "BLN";
BA_ "DiagRequest" BO_ 589 1;
BA_ "Prio" BO_ 589 0;
BA_ "MessageSubnet" BO_ 589 2;
BA_ "VNSigAllNodes" SG_ 589 DgnInf 1;
BA_ "VNSigSLHSSharedDiagnostic" SG_ 589 DgnInf 1;
BA_ "SignalLongName" SG_ 589 DgnInf "Diagnostic Information";
BA_ "SignalType" SG_ 589 DgnInf "UNM";
BA_ "GenMsgILSupport" BO_ 1357 0;
BA_ "Prio" BO_ 1357 0;
BA_ "TpApplType" BO_ 1357 "DiagUUDTResponse";
BA_ "MessageSubnet" BO_ 1357 2;
BA_ "VNSigAllNodes" SG_ 1357 DgnInf_HS54D 1;
BA_ "VNSigSLHSSharedDiagnostic" SG_ 1357 DgnInf_HS54D 1;
BA_ "SignalLongName" SG_ 1357 DgnInf_HS54D "Diagnostic Information HS54D";
BA_ "SignalType" SG_ 1357 DgnInf_HS54D "UNM";
BA_ "DiagResponse" BO_ 1613 1;
BA_ "Prio" BO_ 1613 0;
BA_ "MessageSubnet" BO_ 1613 2;
BA_ "VNSigAllNodes" SG_ 1613 DgnInf 1;
BA_ "VNSigSLHSSharedDiagnostic" SG_ 1613 DgnInf 1;
BA_ "SignalLongName" SG_ 1613 DgnInf "Diagnostic Information";
BA_ "SignalType" SG_ 1613 DgnInf "UNM";
BA_ "DiagResponse" BO_ 1606 1;
BA_ "Prio" BO_ 1606 0;
BA_ "MessageSubnet" BO_ 1606 2;
BA_ "VNSigAllNodes" SG_ 1606 DgnInf 1;
BA_ "VNSigSLHSSharedDiagnostic" SG_ 1606 DgnInf 1;
BA_ "SignalLongName" SG_ 1606 DgnInf "Diagnostic Information";
BA_ "SignalType" SG_ 1606 DgnInf "UNM";
BA_ "DiagRequest" BO_ 582 1;
BA_ "Prio" BO_ 582 0;
BA_ "MessageSubnet" BO_ 582 2;
BA_ "VNSigAllNodes" SG_ 582 DgnInf 1;
BA_ "VNSigSLHSSharedDiagnostic" SG_ 582 DgnInf 1;
BA_ "SignalLongName" SG_ 582 DgnInf "Diagnostic Information";
BA_ "SignalType" SG_ 582 DgnInf "UNM";
BA_ "DiagRequest" BO_ 590 1;
BA_ "Prio" BO_ 590 0;
BA_ "MessageSubnet" BO_ 590 2;
BA_ "VNSigAllNodes" SG_ 590 DgnInf 1;
BA_ "VNSigSLHSSharedDiagnostic" SG_ 590 DgnInf 1;
BA_ "SignalLongName" SG_ 590 DgnInf "Diagnostic Information";
BA_ "SignalType" SG_ 590 DgnInf "UNM";
BA_ "DiagRequest" BO_ 601 1;
BA_ "Prio" BO_ 601 0;
BA_ "MessageSubnet" BO_ 601 2;
BA_ "VNSigAllNodes" SG_ 601 DgnInf 1;
BA_ "VNSigSLHSSharedDiagnostic" SG_ 601 DgnInf 1;
BA_ "SignalLongName" SG_ 601 DgnInf "Diagnostic Information";
BA_ "SignalType" SG_ 601 DgnInf "UNM";
BA_ "GenMsgILSupport" BO_ 1369 0;
BA_ "Prio" BO_ 1369 0;
BA_ "TpApplType" BO_ 1369 "DiagUUDTResponse";
BA_ "MessageSubnet" BO_ 1369 2;
BA_ "VNSigAllNodes" SG_ 1369 DgnInf_HS559 1;
BA_ "VNSigSLHSSharedDiagnostic" SG_ 1369 DgnInf_HS559 1;
BA_ "SignalLongName" SG_ 1369 DgnInf_HS559 "Diagnostic Information HS559";
BA_ "SignalType" SG_ 1369 DgnInf_HS559 "UNM";
BA_ "DiagResponse" BO_ 1625 1;
BA_ "Prio" BO_ 1625 0;
BA_ "MessageSubnet" BO_ 1625 2;
BA_ "VNSigAllNodes" SG_ 1625 DgnInf 1;
BA_ "VNSigSLHSSharedDiagnostic" SG_ 1625 DgnInf 1;
BA_ "SignalLongName" SG_ 1625 DgnInf "Diagnostic Information";
BA_ "SignalType" SG_ 1625 DgnInf "UNM";
BA_ "GenMsgILSupport" BO_ 1356 0;
BA_ "Prio" BO_ 1356 0;
BA_ "TpApplType" BO_ 1356 "DiagUUDTResponse";
BA_ "MessageSubnet" BO_ 1356 2;
BA_ "VNSigAllNodes" SG_ 1356 DgnInf_HS54C 1;
BA_ "VNSigSLHSSharedDiagnostic" SG_ 1356 DgnInf_HS54C 1;
BA_ "SignalLongName" SG_ 1356 DgnInf_HS54C "Diagnostic Information HS54C";
BA_ "SignalType" SG_ 1356 DgnInf_HS54C "UNM";
BA_ "GenMsgILSupport" BO_ 1358 0;
BA_ "Prio" BO_ 1358 0;
BA_ "TpApplType" BO_ 1358 "DiagUUDTResponse";
BA_ "MessageSubnet" BO_ 1358 2;
BA_ "VNSigAllNodes" SG_ 1358 DgnInf_HS54E 1;
BA_ "VNSigSLHSSharedDiagnostic" SG_ 1358 DgnInf_HS54E 1;
BA_ "SignalLongName" SG_ 1358 DgnInf_HS54E "Diagnostic Information HS54E";
BA_ "SignalType" SG_ 1358 DgnInf_HS54E "UNM";
BA_ "GenMsgILSupport" BO_ 1359 0;
BA_ "Prio" BO_ 1359 0;
BA_ "TpApplType" BO_ 1359 "DiagUUDTResponse";
BA_ "MessageSubnet" BO_ 1359 2;
BA_ "VNSigAllNodes" SG_ 1359 DgnInf_HS54F 1;
BA_ "VNSigSLHSSharedDiagnostic" SG_ 1359 DgnInf_HS54F 1;
BA_ "SignalLongName" SG_ 1359 DgnInf_HS54F "Diagnostic Information HS54F";
BA_ "SignalType" SG_ 1359 DgnInf_HS54F "UNM";
BA_ "DiagRequest" BO_ 2023 1;
BA_ "Prio" BO_ 2023 0;
BA_ "MessageSubnet" BO_ 2023 2;
BA_ "VNSigAllNodes" SG_ 2023 DgnInf 1;
BA_ "VNSigSLHSSharedDiagnostic" SG_ 2023 DgnInf 1;
BA_ "SignalLongName" SG_ 2023 DgnInf "Diagnostic Information";
BA_ "SignalType" SG_ 2023 DgnInf "UNM";
BA_ "DiagRequest" BO_ 2021 1;
BA_ "Prio" BO_ 2021 0;
BA_ "MessageSubnet" BO_ 2021 2;
BA_ "VNSigAllNodes" SG_ 2021 DgnInf 1;
BA_ "VNSigSLHSSharedDiagnostic" SG_ 2021 DgnInf 1;
BA_ "SignalLongName" SG_ 2021 DgnInf "Diagnostic Information";
BA_ "SignalType" SG_ 2021 DgnInf "UNM";
BA_ "DiagRequest" BO_ 2017 1;
BA_ "Prio" BO_ 2017 0;
BA_ "MessageSubnet" BO_ 2017 2;
BA_ "VNSigAllNodes" SG_ 2017 DgnInf 1;
BA_ "VNSigSLHSSharedDiagnostic" SG_ 2017 DgnInf 1;
BA_ "SignalLongName" SG_ 2017 DgnInf "Diagnostic Information";
BA_ "SignalType" SG_ 2017 DgnInf "UNM";
BA_ "DiagRequest" BO_ 2019 1;
BA_ "Prio" BO_ 2019 0;
BA_ "MessageSubnet" BO_ 2019 2;
BA_ "VNSigAllNodes" SG_ 2019 DgnInf 1;
BA_ "VNSigSLHSSharedDiagnostic" SG_ 2019 DgnInf 1;
BA_ "SignalLongName" SG_ 2019 DgnInf "Diagnostic Information";
BA_ "SignalType" SG_ 2019 DgnInf "UNM";
BA_ "DiagRequest" BO_ 585 1;
BA_ "Prio" BO_ 585 0;
BA_ "MessageSubnet" BO_ 585 2;
BA_ "VNSigAllNodes" SG_ 585 DgnInf 1;
BA_ "VNSigSLHSSharedDiagnostic" SG_ 585 DgnInf 1;
BA_ "SignalLongName" SG_ 585 DgnInf "Diagnostic Information";
BA_ "SignalType" SG_ 585 DgnInf "UNM";
BA_ "DiagRequest" BO_ 578 1;
BA_ "Prio" BO_ 578 0;
BA_ "MessageSubnet" BO_ 578 2;
BA_ "VNSigAllNodes" SG_ 578 DgnInf 1;
BA_ "VNSigSLHSSharedDiagnostic" SG_ 578 DgnInf 1;
BA_ "SignalLongName" SG_ 578 DgnInf "Diagnostic Information";
BA_ "SignalType" SG_ 578 DgnInf "UNM";
BA_ "DiagRequest" BO_ 2022 1;
BA_ "Prio" BO_ 2022 0;
BA_ "MessageSubnet" BO_ 2022 2;
BA_ "VNSigAllNodes" SG_ 2022 DgnInf 1;
BA_ "VNSigSLHSSharedDiagnostic" SG_ 2022 DgnInf 1;
BA_ "SignalLongName" SG_ 2022 DgnInf "Diagnostic Information";
BA_ "SignalType" SG_ 2022 DgnInf "UNM";
BA_ "DiagRequest" BO_ 584 1;
BA_ "Prio" BO_ 584 0;
BA_ "MessageSubnet" BO_ 584 2;
BA_ "VNSigAllNodes" SG_ 584 DgnInf 1;
BA_ "VNSigSLHSSharedDiagnostic" SG_ 584 DgnInf 1;
BA_ "SignalLongName" SG_ 584 DgnInf "Diagnostic Information";
BA_ "SignalType" SG_ 584 DgnInf "UNM";
BA_ "DiagRequest" BO_ 591 1;
BA_ "Prio" BO_ 591 0;
BA_ "MessageSubnet" BO_ 591 2;
BA_ "VNSigAllNodes" SG_ 591 DgnInf 1;
BA_ "VNSigSLHSSharedDiagnostic" SG_ 591 DgnInf 1;
BA_ "SignalLongName" SG_ 591 DgnInf "Diagnostic Information";
BA_ "SignalType" SG_ 591 DgnInf "UNM";
BA_ "DiagRequest" BO_ 581 1;
BA_ "Prio" BO_ 581 0;
BA_ "MessageSubnet" BO_ 581 2;
BA_ "VNSigAllNodes" SG_ 581 DgnInf 1;
BA_ "VNSigSLHSSharedDiagnostic" SG_ 581 DgnInf 1;
BA_ "SignalLongName" SG_ 581 DgnInf "Diagnostic Information";
BA_ "SignalType" SG_ 581 DgnInf "UNM";
BA_ "DiagRequest" BO_ 586 1;
BA_ "Prio" BO_ 586 0;
BA_ "MessageSubnet" BO_ 586 2;
BA_ "VNSigAllNodes" SG_ 586 DgnInf 1;
BA_ "VNSigSLHSSharedDiagnostic" SG_ 586 DgnInf 1;
BA_ "SignalLongName" SG_ 586 DgnInf "Diagnostic Information";
BA_ "SignalType" SG_ 586 DgnInf "UNM";
BA_ "DiagRequest" BO_ 588 1;
BA_ "GenMsgILSupport" BO_ 588 0;
BA_ "Prio" BO_ 588 0;
BA_ "MessageSubnet" BO_ 588 2;
BA_ "VNSigAllNodes" SG_ 588 DgnInf 1;
BA_ "VNSigSLHSSharedDiagnostic" SG_ 588 DgnInf 1;
BA_ "SignalLongName" SG_ 588 DgnInf "Diagnostic Information";
BA_ "SignalType" SG_ 588 DgnInf "UNM";
BA_ "DiagRequest" BO_ 580 1;
BA_ "Prio" BO_ 580 0;
BA_ "MessageSubnet" BO_ 580 2;
BA_ "VNSigAllNodes" SG_ 580 DgnInf 1;
BA_ "VNSigSLHSSharedDiagnostic" SG_ 580 DgnInf 1;
BA_ "SignalLongName" SG_ 580 DgnInf "Diagnostic Information";
BA_ "SignalType" SG_ 580 DgnInf "UNM";
BA_ "Prio" BO_ 499 0;
BA_ "GenMsgSendType" BO_ 499 0;
BA_ "GenMsgCycleTime" BO_ 499 30;
BA_ "MessageSubnet" BO_ 499 2;
BA_ "VNSigAllNodes" SG_ 499 PTShftPtrnOvrdAct 1;
BA_ "SignalLongName" SG_ 499 PTShftPtrnOvrdAct "Powertrain Shift Pattern Override Active";
BA_ "SignalType" SG_ 499 PTShftPtrnOvrdAct "BLN";
BA_ "VNSigAllNodes" SG_ 499 PFTrnsTUDSecSwSt 1;
BA_ "SignalLongName" SG_ 499 PFTrnsTUDSecSwSt "Platform Transmission Tap Up/Down Secondary Switch State";
BA_ "SignalType" SG_ 499 PFTrnsTUDSecSwSt "ENM";
BA_ "VNSigAllNodes" SG_ 499 TrnsPFShftPattSwARC 1;
BA_ "SignalLongName" SG_ 499 TrnsPFShftPattSwARC "Transmission Platform Shift Pattern Switch Alive Rolling Count";
BA_ "SignalType" SG_ 499 TrnsPFShftPattSwARC "UNM";
BA_ "VNSigAllNodes" SG_ 499 TrnsPFShftPattSw4Act 1;
BA_ "SignalLongName" SG_ 499 TrnsPFShftPattSw4Act "Transmission Platform Shift Pattern Switch 4 Active";
BA_ "SignalType" SG_ 499 TrnsPFShftPattSw4Act "BLN";
BA_ "VNSigAllNodes" SG_ 499 TrnsPFShftPattSw3Act 1;
BA_ "SignalLongName" SG_ 499 TrnsPFShftPattSw3Act "Transmission Platform Shift Pattern Switch 3 Active";
BA_ "SignalType" SG_ 499 TrnsPFShftPattSw3Act "BLN";
BA_ "VNSigAllNodes" SG_ 499 TrnsPFShftPattSw2Act 1;
BA_ "SignalLongName" SG_ 499 TrnsPFShftPattSw2Act "Transmission Platform Shift Pattern Switch 2 Active";
BA_ "SignalType" SG_ 499 TrnsPFShftPattSw2Act "BLN";
BA_ "VNSigAllNodes" SG_ 499 TrnsPFShftPattSw1Act 1;
BA_ "SignalLongName" SG_ 499 TrnsPFShftPattSw1Act "Transmission Platform Shift Pattern Switch 1 Active";
BA_ "SignalType" SG_ 499 TrnsPFShftPattSw1Act "BLN";
BA_ "VNSigAllNodes" SG_ 499 PFTrnsTUDSwStAlvRC 1;
BA_ "SignalLongName" SG_ 499 PFTrnsTUDSwStAlvRC "Platform Transmission Tap Up/Down Switch Status Alive Rolling Count";
BA_ "SignalType" SG_ 499 PFTrnsTUDSwStAlvRC "UNM";
BA_ "VNSigAllNodes" SG_ 499 PFTrnsTUDSwSt 1;
BA_ "SignalLongName" SG_ 499 PFTrnsTUDSwSt "Platform Transmission Tap Up/Down Switch State";
BA_ "SignalType" SG_ 499 PFTrnsTUDSwSt "ENM";
BA_ "VNSigAllNodes" SG_ 499 PFTrnsTUDEnSwSt 1;
BA_ "SignalLongName" SG_ 499 PFTrnsTUDEnSwSt "Platform Transmission Tap Up/Down Enable Switch State";
BA_ "SignalType" SG_ 499 PFTrnsTUDEnSwSt "ENM";
BA_ "VNSigAllNodes" SG_ 499 OvrdrvDsblReqd 1;
BA_ "SignalLongName" SG_ 499 OvrdrvDsblReqd "Overdrive Disable Requested";
BA_ "SignalType" SG_ 499 OvrdrvDsblReqd "BLN";
BA_ "Prio" BO_ 1282 0;
BA_ "GenMsgSendType" BO_ 1282 0;
BA_ "GenMsgCycleTime" BO_ 1282 500;
BA_ "MessageSubnet" BO_ 1282 2;
BA_ "VNSigAllNodes" SG_ 1282 TireTrdTmpStatARC 1;
BA_ "SignalLongName" SG_ 1282 TireTrdTmpStatARC "Tire Tread Temperature Status Alive Rolling Count";
BA_ "SignalType" SG_ 1282 TireTrdTmpStatARC "UNM";
BA_ "VNSigAllNodes" SG_ 1282 TireTrdTmpStat 1;
BA_ "SignalLongName" SG_ 1282 TireTrdTmpStat "Tire Tread Temperature Status";
BA_ "SignalType" SG_ 1282 TireTrdTmpStat "ENM";
BA_ "VNSigAllNodes" SG_ 1282 AllNodesVNA_502 1;
BA_ "SignalLongName" SG_ 1282 AllNodesVNA_502 "All Nodes Virtual Network Activation";
BA_ "VNSigSLHS_VNReq" SG_ 1282 AllNodesVNA_502 1;
BA_ "SignalType" SG_ 1282 AllNodesVNA_502 "ENM";
BA_ "VNSigAllNodes" SG_ 1282 A3ERRAlrmTime 1;
BA_ "PacketOrder" SG_ 1282 A3ERRAlrmTime 2;
BA_ "SignalLongName" SG_ 1282 A3ERRAlrmTime "Alarm 3 Extended Range Request : Alarm Time";
BA_ "SignalType" SG_ 1282 A3ERRAlrmTime "UNM";
BA_ "VNSigAllNodes" SG_ 1282 A3ERRAlrmReq 1;
BA_ "PacketOrder" SG_ 1282 A3ERRAlrmReq 1;
BA_ "SignalLongName" SG_ 1282 A3ERRAlrmReq "Alarm 3 Extended Range Request : Alarm Request";
BA_ "SignalType" SG_ 1282 A3ERRAlrmReq "ENM";
BA_ "GenMsgILSupport" BO_ 1360 0;
BA_ "Prio" BO_ 1360 0;
BA_ "TpApplType" BO_ 1360 "DiagUUDTResponse";
BA_ "MessageSubnet" BO_ 1360 2;
BA_ "VNSigAllNodes" SG_ 1360 DgnInf_HS550 1;
BA_ "VNSigSLHSSharedDiagnostic" SG_ 1360 DgnInf_HS550 1;
BA_ "SignalLongName" SG_ 1360 DgnInf_HS550 "Diagnostic Information HS550";
BA_ "SignalType" SG_ 1360 DgnInf_HS550 "UNM";
BA_ "DiagResponse" BO_ 1616 1;
BA_ "Prio" BO_ 1616 0;
BA_ "MessageSubnet" BO_ 1616 2;
BA_ "VNSigAllNodes" SG_ 1616 DgnInf 1;
BA_ "VNSigSLHSSharedDiagnostic" SG_ 1616 DgnInf 1;
BA_ "SignalLongName" SG_ 1616 DgnInf "Diagnostic Information";
BA_ "SignalType" SG_ 1616 DgnInf "UNM";
BA_ "Prio" BO_ 1921 0;
BA_ "GenMsgSendType" BO_ 1921 0;
BA_ "GenMsgCycleTime" BO_ 1921 1000;
BA_ "MessageSubnet" BO_ 1921 2;
BA_ "VNSigAllNodes" SG_ 1921 DTCI_CurrentStatus_781 1;
BA_ "PacketOrder" SG_ 1921 DTCI_CurrentStatus_781 18;
BA_ "SignalLongName" SG_ 1921 DTCI_CurrentStatus_781 "Diagnostic Trouble Code Information Extended 781: Current Status";
BA_ "SignalType" SG_ 1921 DTCI_CurrentStatus_781 "BLN";
BA_ "VNSigAllNodes" SG_ 1921 DTCI_WrnIndRqdSt_781 1;
BA_ "PacketOrder" SG_ 1921 DTCI_WrnIndRqdSt_781 12;
BA_ "SignalLongName" SG_ 1921 DTCI_WrnIndRqdSt_781 "Diagnostic Trouble Code Information Extended 781 : Warning Indicator Requested Status";
BA_ "SignalType" SG_ 1921 DTCI_WrnIndRqdSt_781 "BLN";
BA_ "VNSigAllNodes" SG_ 1921 DTCIUnused7_781 1;
BA_ "PacketOrder" SG_ 1921 DTCIUnused7_781 7;
BA_ "SignalLongName" SG_ 1921 DTCIUnused7_781 "Diagnostic Trouble Code Information Extended 781 : Unused 7";
BA_ "SignalType" SG_ 1921 DTCIUnused7_781 "BLN";
BA_ "VNSigAllNodes" SG_ 1921 DTCIUnused6_781 1;
BA_ "PacketOrder" SG_ 1921 DTCIUnused6_781 6;
BA_ "SignalLongName" SG_ 1921 DTCIUnused6_781 "Diagnostic Trouble Code Information Extended 781 : Unused 6";
BA_ "SignalType" SG_ 1921 DTCIUnused6_781 "BLN";
BA_ "VNSigAllNodes" SG_ 1921 DTCIUnused5_781 1;
BA_ "PacketOrder" SG_ 1921 DTCIUnused5_781 5;
BA_ "SignalLongName" SG_ 1921 DTCIUnused5_781 "Diagnostic Trouble Code Information Extended 781 : Unused 5";
BA_ "SignalType" SG_ 1921 DTCIUnused5_781 "BLN";
BA_ "VNSigAllNodes" SG_ 1921 DTCIUnused4_781 1;
BA_ "PacketOrder" SG_ 1921 DTCIUnused4_781 4;
BA_ "SignalLongName" SG_ 1921 DTCIUnused4_781 "Diagnostic Trouble Code Information Extended 781 : Unused 4";
BA_ "SignalType" SG_ 1921 DTCIUnused4_781 "BLN";
BA_ "VNSigAllNodes" SG_ 1921 DTCIUnused3_781 1;
BA_ "PacketOrder" SG_ 1921 DTCIUnused3_781 3;
BA_ "SignalLongName" SG_ 1921 DTCIUnused3_781 "Diagnostic Trouble Code Information Extended 781 : Unused 3";
BA_ "SignalType" SG_ 1921 DTCIUnused3_781 "BLN";
BA_ "VNSigAllNodes" SG_ 1921 DTCIUnused2_781 1;
BA_ "PacketOrder" SG_ 1921 DTCIUnused2_781 2;
BA_ "SignalLongName" SG_ 1921 DTCIUnused2_781 "Diagnostic Trouble Code Information Extended 781 : Unused 2";
BA_ "SignalType" SG_ 1921 DTCIUnused2_781 "BLN";
BA_ "VNSigAllNodes" SG_ 1921 DTCIUnused1_781 1;
BA_ "PacketOrder" SG_ 1921 DTCIUnused1_781 1;
BA_ "SignalLongName" SG_ 1921 DTCIUnused1_781 "Diagnostic Trouble Code Information Extended 781 : Unused 1";
BA_ "SignalType" SG_ 1921 DTCIUnused1_781 "BLN";
BA_ "VNSigAllNodes" SG_ 1921 DTCI_TstNPsdPwrUpSt_781 1;
BA_ "PacketOrder" SG_ 1921 DTCI_TstNPsdPwrUpSt_781 14;
BA_ "SignalLongName" SG_ 1921 DTCI_TstNPsdPwrUpSt_781 "Diagnostic Trouble Code Information Extended 781 : Test Not Passed Since Power Up Status";
BA_ "SignalType" SG_ 1921 DTCI_TstNPsdPwrUpSt_781 "BLN";
BA_ "VNSigAllNodes" SG_ 1921 DTCI_TstNPsdCdClrdSt_781 1;
BA_ "PacketOrder" SG_ 1921 DTCI_TstNPsdCdClrdSt_781 17;
BA_ "SignalLongName" SG_ 1921 DTCI_TstNPsdCdClrdSt_781 "Diagnostic Trouble Code Information Extended 781 : Test Not Passed Since Code Cleared Status";
BA_ "SignalType" SG_ 1921 DTCI_TstNPsdCdClrdSt_781 "BLN";
BA_ "VNSigAllNodes" SG_ 1921 DTCI_TstFldPwrUpSt_781 1;
BA_ "PacketOrder" SG_ 1921 DTCI_TstFldPwrUpSt_781 13;
BA_ "SignalLongName" SG_ 1921 DTCI_TstFldPwrUpSt_781 "Diagnostic Trouble Code Information Extended 781 : Test Failed Since Power Up Status";
BA_ "SignalType" SG_ 1921 DTCI_TstFldPwrUpSt_781 "BLN";
BA_ "VNSigAllNodes" SG_ 1921 DTCI_TstFldCdClrdStat_781 1;
BA_ "PacketOrder" SG_ 1921 DTCI_TstFldCdClrdStat_781 16;
BA_ "SignalLongName" SG_ 1921 DTCI_TstFldCdClrdStat_781 "Diagnostic Trouble Code Information Extended 781 : Test Failed Since Code Cleared Status";
BA_ "SignalType" SG_ 1921 DTCI_TstFldCdClrdStat_781 "BLN";
BA_ "VNSigAllNodes" SG_ 1921 DTCI_HistStat_781 1;
BA_ "PacketOrder" SG_ 1921 DTCI_HistStat_781 15;
BA_ "SignalLongName" SG_ 1921 DTCI_HistStat_781 "Diagnostic Trouble Code Information Extended 781 : History Status";
BA_ "SignalType" SG_ 1921 DTCI_HistStat_781 "BLN";
BA_ "VNSigAllNodes" SG_ 1921 DTCI_DTCTriggered_781 1;
BA_ "PacketOrder" SG_ 1921 DTCI_DTCTriggered_781 8;
BA_ "SignalLongName" SG_ 1921 DTCI_DTCTriggered_781 "Diagnostic Trouble Code Information Extended 781 : Diagnostic Trouble Code Triggered";
BA_ "SignalType" SG_ 1921 DTCI_DTCTriggered_781 "BLN";
BA_ "VNSigAllNodes" SG_ 1921 DTCI_DTCSource_781 1;
BA_ "PacketOrder" SG_ 1921 DTCI_DTCSource_781 9;
BA_ "SignalLongName" SG_ 1921 DTCI_DTCSource_781 "Diagnostic Trouble Code Information Extended 781 : Diagnostic Trouble Code Source";
BA_ "SignalType" SG_ 1921 DTCI_DTCSource_781 "UNM";
BA_ "VNSigAllNodes" SG_ 1921 DTCI_DTCNumber_781 1;
BA_ "PacketOrder" SG_ 1921 DTCI_DTCNumber_781 10;
BA_ "SignalLongName" SG_ 1921 DTCI_DTCNumber_781 "Diagnostic Trouble Code Information Extended 781 : Diagnostic Trouble Code Number";
BA_ "SignalType" SG_ 1921 DTCI_DTCNumber_781 "UNM";
BA_ "VNSigAllNodes" SG_ 1921 DTCI_DTCFaultType_781 1;
BA_ "PacketOrder" SG_ 1921 DTCI_DTCFaultType_781 20;
BA_ "SignalLongName" SG_ 1921 DTCI_DTCFaultType_781 "Diagnostic Trouble Code Information Extended 781 : Diagnostic Trouble Code Fault Type";
BA_ "SignalType" SG_ 1921 DTCI_DTCFaultType_781 "ENM";
BA_ "VNSigAllNodes" SG_ 1921 DTCI_DTCFailType_781 1;
BA_ "PacketOrder" SG_ 1921 DTCI_DTCFailType_781 11;
BA_ "SignalLongName" SG_ 1921 DTCI_DTCFailType_781 "Diagnostic Trouble Code Information Extended 781 : Diagnostic Trouble Code Failure Type";
BA_ "SignalType" SG_ 1921 DTCI_DTCFailType_781 "UNM";
BA_ "VNSigAllNodes" SG_ 1921 DTCI_CodeSupported_781 1;
BA_ "PacketOrder" SG_ 1921 DTCI_CodeSupported_781 19;
BA_ "SignalLongName" SG_ 1921 DTCI_CodeSupported_781 "Diagnostic Trouble Code Information Extended 781 : Code Supported";
BA_ "SignalType" SG_ 1921 DTCI_CodeSupported_781 "BLN";
BA_ "Prio" BO_ 1920 0;
BA_ "GenMsgSendType" BO_ 1920 0;
BA_ "GenMsgCycleTime" BO_ 1920 1000;
BA_ "MessageSubnet" BO_ 1920 2;
BA_ "VNSigAllNodes" SG_ 1920 DTCI_CurrentStatus_780 1;
BA_ "PacketOrder" SG_ 1920 DTCI_CurrentStatus_780 18;
BA_ "SignalLongName" SG_ 1920 DTCI_CurrentStatus_780 "Diagnostic Trouble Code Information Extended 780 : Current Status";
BA_ "SignalType" SG_ 1920 DTCI_CurrentStatus_780 "BLN";
BA_ "VNSigAllNodes" SG_ 1920 DTCI_WrnIndRqdSt_780 1;
BA_ "PacketOrder" SG_ 1920 DTCI_WrnIndRqdSt_780 12;
BA_ "SignalLongName" SG_ 1920 DTCI_WrnIndRqdSt_780 "Diagnostic Trouble Code Information Extended 780 : Warning Indicator Requested Status";
BA_ "SignalType" SG_ 1920 DTCI_WrnIndRqdSt_780 "BLN";
BA_ "VNSigAllNodes" SG_ 1920 DTCIUnused7_780 1;
BA_ "PacketOrder" SG_ 1920 DTCIUnused7_780 7;
BA_ "SignalLongName" SG_ 1920 DTCIUnused7_780 "Diagnostic Trouble Code Information Extended 780 : Unused 7";
BA_ "SignalType" SG_ 1920 DTCIUnused7_780 "BLN";
BA_ "VNSigAllNodes" SG_ 1920 DTCIUnused6_780 1;
BA_ "PacketOrder" SG_ 1920 DTCIUnused6_780 6;
BA_ "SignalLongName" SG_ 1920 DTCIUnused6_780 "Diagnostic Trouble Code Information Extended 780 : Unused 6";
BA_ "SignalType" SG_ 1920 DTCIUnused6_780 "BLN";
BA_ "VNSigAllNodes" SG_ 1920 DTCIUnused5_780 1;
BA_ "PacketOrder" SG_ 1920 DTCIUnused5_780 5;
BA_ "SignalLongName" SG_ 1920 DTCIUnused5_780 "Diagnostic Trouble Code Information Extended 780 : Unused 5";
BA_ "SignalType" SG_ 1920 DTCIUnused5_780 "BLN";
BA_ "VNSigAllNodes" SG_ 1920 DTCIUnused4_780 1;
BA_ "PacketOrder" SG_ 1920 DTCIUnused4_780 4;
BA_ "SignalLongName" SG_ 1920 DTCIUnused4_780 "Diagnostic Trouble Code Information Extended 780 : Unused 4";
BA_ "SignalType" SG_ 1920 DTCIUnused4_780 "BLN";
BA_ "VNSigAllNodes" SG_ 1920 DTCIUnused3_780 1;
BA_ "PacketOrder" SG_ 1920 DTCIUnused3_780 3;
BA_ "SignalLongName" SG_ 1920 DTCIUnused3_780 "Diagnostic Trouble Code Information Extended 780 : Unused 3";
BA_ "SignalType" SG_ 1920 DTCIUnused3_780 "BLN";
BA_ "VNSigAllNodes" SG_ 1920 DTCIUnused2_780 1;
BA_ "PacketOrder" SG_ 1920 DTCIUnused2_780 2;
BA_ "SignalLongName" SG_ 1920 DTCIUnused2_780 "Diagnostic Trouble Code Information Extended 780 : Unused 2";
BA_ "SignalType" SG_ 1920 DTCIUnused2_780 "BLN";
BA_ "VNSigAllNodes" SG_ 1920 DTCIUnused1_780 1;
BA_ "PacketOrder" SG_ 1920 DTCIUnused1_780 1;
BA_ "SignalLongName" SG_ 1920 DTCIUnused1_780 "Diagnostic Trouble Code Information Extended 780 : Unused 1";
BA_ "SignalType" SG_ 1920 DTCIUnused1_780 "BLN";
BA_ "VNSigAllNodes" SG_ 1920 DTCI_TstNPsdPwrUpSt_780 1;
BA_ "PacketOrder" SG_ 1920 DTCI_TstNPsdPwrUpSt_780 14;
BA_ "SignalLongName" SG_ 1920 DTCI_TstNPsdPwrUpSt_780 "Diagnostic Trouble Code Information Extended 780 : Test Not Passed Since Power Up Status";
BA_ "SignalType" SG_ 1920 DTCI_TstNPsdPwrUpSt_780 "BLN";
BA_ "VNSigAllNodes" SG_ 1920 DTCI_TstNPsdCdClrdSt_780 1;
BA_ "PacketOrder" SG_ 1920 DTCI_TstNPsdCdClrdSt_780 17;
BA_ "SignalLongName" SG_ 1920 DTCI_TstNPsdCdClrdSt_780 "Diagnostic Trouble Code Information Extended 780 : Test Not Passed Since Code Cleared Status";
BA_ "SignalType" SG_ 1920 DTCI_TstNPsdCdClrdSt_780 "BLN";
BA_ "VNSigAllNodes" SG_ 1920 DTCI_TstFldPwrUpSt_780 1;
BA_ "PacketOrder" SG_ 1920 DTCI_TstFldPwrUpSt_780 13;
BA_ "SignalLongName" SG_ 1920 DTCI_TstFldPwrUpSt_780 "Diagnostic Trouble Code Information Extended 780 : Test Failed Since Power Up Status";
BA_ "SignalType" SG_ 1920 DTCI_TstFldPwrUpSt_780 "BLN";
BA_ "VNSigAllNodes" SG_ 1920 DTCI_TstFldCdClrdStat_780 1;
BA_ "PacketOrder" SG_ 1920 DTCI_TstFldCdClrdStat_780 16;
BA_ "SignalLongName" SG_ 1920 DTCI_TstFldCdClrdStat_780 "Diagnostic Trouble Code Information Extended 780 : Test Failed Since Code Cleared Status";
BA_ "SignalType" SG_ 1920 DTCI_TstFldCdClrdStat_780 "BLN";
BA_ "VNSigAllNodes" SG_ 1920 DTCI_HistStat_780 1;
BA_ "PacketOrder" SG_ 1920 DTCI_HistStat_780 15;
BA_ "SignalLongName" SG_ 1920 DTCI_HistStat_780 "Diagnostic Trouble Code Information Extended 780 : History Status";
BA_ "SignalType" SG_ 1920 DTCI_HistStat_780 "BLN";
BA_ "VNSigAllNodes" SG_ 1920 DTCI_DTCTriggered_780 1;
BA_ "PacketOrder" SG_ 1920 DTCI_DTCTriggered_780 8;
BA_ "SignalLongName" SG_ 1920 DTCI_DTCTriggered_780 "Diagnostic Trouble Code Information Extended 780 : Diagnostic Trouble Code Triggered";
BA_ "SignalType" SG_ 1920 DTCI_DTCTriggered_780 "BLN";
BA_ "VNSigAllNodes" SG_ 1920 DTCI_DTCSource_780 1;
BA_ "PacketOrder" SG_ 1920 DTCI_DTCSource_780 9;
BA_ "SignalLongName" SG_ 1920 DTCI_DTCSource_780 "Diagnostic Trouble Code Information Extended 780 : Diagnostic Trouble Code Source";
BA_ "SignalType" SG_ 1920 DTCI_DTCSource_780 "UNM";
BA_ "VNSigAllNodes" SG_ 1920 DTCI_DTCNumber_780 1;
BA_ "PacketOrder" SG_ 1920 DTCI_DTCNumber_780 10;
BA_ "SignalLongName" SG_ 1920 DTCI_DTCNumber_780 "Diagnostic Trouble Code Information Extended 780 : Diagnostic Trouble Code Number";
BA_ "SignalType" SG_ 1920 DTCI_DTCNumber_780 "UNM";
BA_ "VNSigAllNodes" SG_ 1920 DTCI_DTCFaultType_780 1;
BA_ "PacketOrder" SG_ 1920 DTCI_DTCFaultType_780 20;
BA_ "SignalLongName" SG_ 1920 DTCI_DTCFaultType_780 "Diagnostic Trouble Code Information Extended 780 : Diagnostic Trouble Code Fault Type";
BA_ "SignalType" SG_ 1920 DTCI_DTCFaultType_780 "ENM";
BA_ "VNSigAllNodes" SG_ 1920 DTCI_DTCFailType_780 1;
BA_ "PacketOrder" SG_ 1920 DTCI_DTCFailType_780 11;
BA_ "SignalLongName" SG_ 1920 DTCI_DTCFailType_780 "Diagnostic Trouble Code Information Extended 780 : Diagnostic Trouble Code Failure Type";
BA_ "SignalType" SG_ 1920 DTCI_DTCFailType_780 "UNM";
BA_ "VNSigAllNodes" SG_ 1920 DTCI_CodeSupported_780 1;
BA_ "PacketOrder" SG_ 1920 DTCI_CodeSupported_780 19;
BA_ "SignalLongName" SG_ 1920 DTCI_CodeSupported_780 "Diagnostic Trouble Code Information Extended 780 : Code Supported";
BA_ "SignalType" SG_ 1920 DTCI_CodeSupported_780 "BLN";
BA_ "DiagRequest" BO_ 596 1;
BA_ "Prio" BO_ 596 0;
BA_ "MessageSubnet" BO_ 596 2;
BA_ "VNSigAllNodes" SG_ 596 DgnInf 1;
BA_ "VNSigSLHSSharedDiagnostic" SG_ 596 DgnInf 1;
BA_ "SignalLongName" SG_ 596 DgnInf "Diagnostic Information";
BA_ "SignalType" SG_ 596 DgnInf "UNM";
BA_ "Prio" BO_ 2033 0;
BA_ "MessageSubnet" BO_ 2033 2;
BA_ "GenSigDeltaValue" SG_ 2033 PCUInfo 1;
BA_ "VNSigAllNodes" SG_ 2033 PCUInfo 1;
BA_ "GenSigSendType" SG_ 2033 PCUInfo 12;
BA_ "SignalLongName" SG_ 2033 PCUInfo "Pyrotechnical Control Unit Information";
BA_ "SignalType" SG_ 2033 PCUInfo "UNM";
BA_ "Prio" BO_ 495 0;
BA_ "GenMsgSendType" BO_ 495 0;
BA_ "GenMsgCycleTime" BO_ 495 12;
BA_ "MessageSubnet" BO_ 495 2;
BA_ "VNSigAllNodes" SG_ 495 MassAirFloV 1;
BA_ "SignalLongName" SG_ 495 MassAirFloV "Mass Air Flow Validity";
BA_ "SignalType" SG_ 495 MassAirFloV "ENM";
BA_ "VNSigAllNodes" SG_ 495 MassAirFlo 1;
BA_ "SignalLongName" SG_ 495 MassAirFlo "Mass Air Flow";
BA_ "SignalType" SG_ 495 MassAirFlo "UNM";
BA_ "GenMsgILSupport" BO_ 1350 0;
BA_ "Prio" BO_ 1350 0;
BA_ "TpApplType" BO_ 1350 "DiagUUDTResponse";
BA_ "MessageSubnet" BO_ 1350 2;
BA_ "VNSigAllNodes" SG_ 1350 DgnInf_HS546 1;
BA_ "VNSigSLHSSharedDiagnostic" SG_ 1350 DgnInf_HS546 1;
BA_ "SignalLongName" SG_ 1350 DgnInf_HS546 "Diagnostic Information HS546";
BA_ "SignalType" SG_ 1350 DgnInf_HS546 "UNM";
BA_ "Prio" BO_ 1914 6;
BA_ "GenMsgSendType" BO_ 1914 0;
BA_ "GenMsgCycleTime" BO_ 1914 1000;
BA_ "MessageSubnet" BO_ 1914 2;
BA_ "VNSigAllNodes" SG_ 1914 DTCI_DTCFaultType_77A 1;
BA_ "PacketOrder" SG_ 1914 DTCI_DTCFaultType_77A 20;
BA_ "SignalLongName" SG_ 1914 DTCI_DTCFaultType_77A "Diagnostic Trouble Code Information Extended 77A : Diagnostic Trouble Code Fault Type";
BA_ "SignalType" SG_ 1914 DTCI_DTCFaultType_77A "ENM";
BA_ "VNSigAllNodes" SG_ 1914 DTCI_CodeSupported_77A 1;
BA_ "PacketOrder" SG_ 1914 DTCI_CodeSupported_77A 19;
BA_ "SignalLongName" SG_ 1914 DTCI_CodeSupported_77A "Diagnostic Trouble Code Information Extended 77A : Code Supported";
BA_ "SignalType" SG_ 1914 DTCI_CodeSupported_77A "BLN";
BA_ "VNSigAllNodes" SG_ 1914 DTCI_CurrentStatus_77A 1;
BA_ "PacketOrder" SG_ 1914 DTCI_CurrentStatus_77A 18;
BA_ "SignalLongName" SG_ 1914 DTCI_CurrentStatus_77A "Diagnostic Trouble Code Information Extended 77A : Current Status";
BA_ "SignalType" SG_ 1914 DTCI_CurrentStatus_77A "BLN";
BA_ "VNSigAllNodes" SG_ 1914 DTCI_TstNPsdCdClrdSt_77A 1;
BA_ "PacketOrder" SG_ 1914 DTCI_TstNPsdCdClrdSt_77A 17;
BA_ "SignalLongName" SG_ 1914 DTCI_TstNPsdCdClrdSt_77A "Diagnostic Trouble Code Information Extended 77A : Test Not Passed Since Code Cleared Status";
BA_ "SignalType" SG_ 1914 DTCI_TstNPsdCdClrdSt_77A "BLN";
BA_ "VNSigAllNodes" SG_ 1914 DTCI_TstFldCdClrdStat_77A 1;
BA_ "PacketOrder" SG_ 1914 DTCI_TstFldCdClrdStat_77A 16;
BA_ "SignalLongName" SG_ 1914 DTCI_TstFldCdClrdStat_77A "Diagnostic Trouble Code Information Extended 77A : Test Failed Since Code Cleared Status";
BA_ "SignalType" SG_ 1914 DTCI_TstFldCdClrdStat_77A "BLN";
BA_ "VNSigAllNodes" SG_ 1914 DTCI_HistStat_77A 1;
BA_ "PacketOrder" SG_ 1914 DTCI_HistStat_77A 15;
BA_ "SignalLongName" SG_ 1914 DTCI_HistStat_77A "Diagnostic Trouble Code Information Extended 77A : History Status";
BA_ "SignalType" SG_ 1914 DTCI_HistStat_77A "BLN";
BA_ "VNSigAllNodes" SG_ 1914 DTCI_TstNPsdPwrUpSt_77A 1;
BA_ "PacketOrder" SG_ 1914 DTCI_TstNPsdPwrUpSt_77A 14;
BA_ "SignalLongName" SG_ 1914 DTCI_TstNPsdPwrUpSt_77A "Diagnostic Trouble Code Information Extended 77A : Test Not Passed Since Power Up Status";
BA_ "SignalType" SG_ 1914 DTCI_TstNPsdPwrUpSt_77A "BLN";
BA_ "VNSigAllNodes" SG_ 1914 DTCI_TstFldPwrUpSt_77A 1;
BA_ "PacketOrder" SG_ 1914 DTCI_TstFldPwrUpSt_77A 13;
BA_ "SignalLongName" SG_ 1914 DTCI_TstFldPwrUpSt_77A "Diagnostic Trouble Code Information Extended 77A : Test Failed Since Power Up Status";
BA_ "SignalType" SG_ 1914 DTCI_TstFldPwrUpSt_77A "BLN";
BA_ "VNSigAllNodes" SG_ 1914 DTCI_WrnIndRqdSt_77A 1;
BA_ "PacketOrder" SG_ 1914 DTCI_WrnIndRqdSt_77A 12;
BA_ "SignalLongName" SG_ 1914 DTCI_WrnIndRqdSt_77A "Diagnostic Trouble Code Information Extended 77A : Warning Indicator Requested Status";
BA_ "SignalType" SG_ 1914 DTCI_WrnIndRqdSt_77A "BLN";
BA_ "VNSigAllNodes" SG_ 1914 DTCI_DTCFailType_77A 1;
BA_ "PacketOrder" SG_ 1914 DTCI_DTCFailType_77A 11;
BA_ "SignalLongName" SG_ 1914 DTCI_DTCFailType_77A "Diagnostic Trouble Code Information Extended 77A : Diagnostic Trouble Code Failure Type";
BA_ "SignalType" SG_ 1914 DTCI_DTCFailType_77A "UNM";
BA_ "VNSigAllNodes" SG_ 1914 DTCI_DTCNumber_77A 1;
BA_ "PacketOrder" SG_ 1914 DTCI_DTCNumber_77A 10;
BA_ "SignalLongName" SG_ 1914 DTCI_DTCNumber_77A "Diagnostic Trouble Code Information Extended 77A : Diagnostic Trouble Code Number";
BA_ "SignalType" SG_ 1914 DTCI_DTCNumber_77A "UNM";
BA_ "VNSigAllNodes" SG_ 1914 DTCI_DTCSource_77A 1;
BA_ "PacketOrder" SG_ 1914 DTCI_DTCSource_77A 9;
BA_ "SignalLongName" SG_ 1914 DTCI_DTCSource_77A "Diagnostic Trouble Code Information Extended 77A : Diagnostic Trouble Code Source";
BA_ "SignalType" SG_ 1914 DTCI_DTCSource_77A "UNM";
BA_ "VNSigAllNodes" SG_ 1914 DTCI_DTCTriggered_77A 1;
BA_ "PacketOrder" SG_ 1914 DTCI_DTCTriggered_77A 8;
BA_ "SignalLongName" SG_ 1914 DTCI_DTCTriggered_77A "Diagnostic Trouble Code Information Extended 77A : Diagnostic Trouble Code Triggered";
BA_ "SignalType" SG_ 1914 DTCI_DTCTriggered_77A "BLN";
BA_ "VNSigAllNodes" SG_ 1914 DTCIUnused7_77A 1;
BA_ "PacketOrder" SG_ 1914 DTCIUnused7_77A 7;
BA_ "SignalLongName" SG_ 1914 DTCIUnused7_77A "Diagnostic Trouble Code Information Extended 77A : Unused 7";
BA_ "SignalType" SG_ 1914 DTCIUnused7_77A "BLN";
BA_ "VNSigAllNodes" SG_ 1914 DTCIUnused6_77A 1;
BA_ "PacketOrder" SG_ 1914 DTCIUnused6_77A 6;
BA_ "SignalLongName" SG_ 1914 DTCIUnused6_77A "Diagnostic Trouble Code Information Extended 77A : Unused 6";
BA_ "SignalType" SG_ 1914 DTCIUnused6_77A "BLN";
BA_ "VNSigAllNodes" SG_ 1914 DTCIUnused5_77A 1;
BA_ "PacketOrder" SG_ 1914 DTCIUnused5_77A 5;
BA_ "SignalLongName" SG_ 1914 DTCIUnused5_77A "Diagnostic Trouble Code Information Extended 77A : Unused 5";
BA_ "SignalType" SG_ 1914 DTCIUnused5_77A "BLN";
BA_ "VNSigAllNodes" SG_ 1914 DTCIUnused4_77A 1;
BA_ "PacketOrder" SG_ 1914 DTCIUnused4_77A 4;
BA_ "SignalLongName" SG_ 1914 DTCIUnused4_77A "Diagnostic Trouble Code Information Extended 77A : Unused 4";
BA_ "SignalType" SG_ 1914 DTCIUnused4_77A "BLN";
BA_ "VNSigAllNodes" SG_ 1914 DTCIUnused3_77A 1;
BA_ "PacketOrder" SG_ 1914 DTCIUnused3_77A 3;
BA_ "SignalLongName" SG_ 1914 DTCIUnused3_77A "Diagnostic Trouble Code Information Extended 77A : Unused 3";
BA_ "SignalType" SG_ 1914 DTCIUnused3_77A "BLN";
BA_ "VNSigAllNodes" SG_ 1914 DTCIUnused2_77A 1;
BA_ "PacketOrder" SG_ 1914 DTCIUnused2_77A 2;
BA_ "SignalLongName" SG_ 1914 DTCIUnused2_77A "Diagnostic Trouble Code Information Extended 77A : Unused 2";
BA_ "SignalType" SG_ 1914 DTCIUnused2_77A "BLN";
BA_ "VNSigAllNodes" SG_ 1914 DTCIUnused1_77A 1;
BA_ "PacketOrder" SG_ 1914 DTCIUnused1_77A 1;
BA_ "SignalLongName" SG_ 1914 DTCIUnused1_77A "Diagnostic Trouble Code Information Extended 77A : Unused 1";
BA_ "SignalType" SG_ 1914 DTCIUnused1_77A "BLN";
BA_ "Prio" BO_ 1911 6;
BA_ "GenMsgSendType" BO_ 1911 0;
BA_ "GenMsgCycleTime" BO_ 1911 1000;
BA_ "MessageSubnet" BO_ 1911 2;
BA_ "VNSigAllNodes" SG_ 1911 DTCI_DTCFaultType_777 1;
BA_ "PacketOrder" SG_ 1911 DTCI_DTCFaultType_777 20;
BA_ "SignalLongName" SG_ 1911 DTCI_DTCFaultType_777 "Diagnostic Trouble Code Information Extended 777 : Diagnostic Trouble Code Fault Type";
BA_ "SignalType" SG_ 1911 DTCI_DTCFaultType_777 "ENM";
BA_ "VNSigAllNodes" SG_ 1911 DTCI_CodeSupported_777 1;
BA_ "PacketOrder" SG_ 1911 DTCI_CodeSupported_777 19;
BA_ "SignalLongName" SG_ 1911 DTCI_CodeSupported_777 "Diagnostic Trouble Code Information Extended 777 : Code Supported";
BA_ "SignalType" SG_ 1911 DTCI_CodeSupported_777 "BLN";
BA_ "VNSigAllNodes" SG_ 1911 DTCI_CurrentStatus_777 1;
BA_ "PacketOrder" SG_ 1911 DTCI_CurrentStatus_777 18;
BA_ "SignalLongName" SG_ 1911 DTCI_CurrentStatus_777 "Diagnostic Trouble Code Information Extended 777 : Current Status";
BA_ "SignalType" SG_ 1911 DTCI_CurrentStatus_777 "BLN";
BA_ "VNSigAllNodes" SG_ 1911 DTCI_TstNPsdCdClrdSt_777 1;
BA_ "PacketOrder" SG_ 1911 DTCI_TstNPsdCdClrdSt_777 17;
BA_ "SignalLongName" SG_ 1911 DTCI_TstNPsdCdClrdSt_777 "Diagnostic Trouble Code Information Extended 777 : Test Not Passed Since Code Cleared Status";
BA_ "SignalType" SG_ 1911 DTCI_TstNPsdCdClrdSt_777 "BLN";
BA_ "VNSigAllNodes" SG_ 1911 DTCI_TstFldCdClrdStat_777 1;
BA_ "PacketOrder" SG_ 1911 DTCI_TstFldCdClrdStat_777 16;
BA_ "SignalLongName" SG_ 1911 DTCI_TstFldCdClrdStat_777 "Diagnostic Trouble Code Information Extended 777 : Test Failed Since Code Cleared Status";
BA_ "SignalType" SG_ 1911 DTCI_TstFldCdClrdStat_777 "BLN";
BA_ "VNSigAllNodes" SG_ 1911 DTCI_HistStat_777 1;
BA_ "PacketOrder" SG_ 1911 DTCI_HistStat_777 15;
BA_ "SignalLongName" SG_ 1911 DTCI_HistStat_777 "Diagnostic Trouble Code Information Extended 777 : History Status";
BA_ "SignalType" SG_ 1911 DTCI_HistStat_777 "BLN";
BA_ "VNSigAllNodes" SG_ 1911 DTCI_TstNPsdPwrUpSt_777 1;
BA_ "PacketOrder" SG_ 1911 DTCI_TstNPsdPwrUpSt_777 14;
BA_ "SignalLongName" SG_ 1911 DTCI_TstNPsdPwrUpSt_777 "Diagnostic Trouble Code Information Extended 777 : Test Not Passed Since Power Up Status";
BA_ "SignalType" SG_ 1911 DTCI_TstNPsdPwrUpSt_777 "BLN";
BA_ "VNSigAllNodes" SG_ 1911 DTCI_TstFldPwrUpSt_777 1;
BA_ "PacketOrder" SG_ 1911 DTCI_TstFldPwrUpSt_777 13;
BA_ "SignalLongName" SG_ 1911 DTCI_TstFldPwrUpSt_777 "Diagnostic Trouble Code Information Extended 777 : Test Failed Since Power Up Status";
BA_ "SignalType" SG_ 1911 DTCI_TstFldPwrUpSt_777 "BLN";
BA_ "VNSigAllNodes" SG_ 1911 DTCI_WrnIndRqdSt_777 1;
BA_ "PacketOrder" SG_ 1911 DTCI_WrnIndRqdSt_777 12;
BA_ "SignalLongName" SG_ 1911 DTCI_WrnIndRqdSt_777 "Diagnostic Trouble Code Information Extended 777 : Warning Indicator Requested Status";
BA_ "SignalType" SG_ 1911 DTCI_WrnIndRqdSt_777 "BLN";
BA_ "VNSigAllNodes" SG_ 1911 DTCI_DTCFailType_777 1;
BA_ "PacketOrder" SG_ 1911 DTCI_DTCFailType_777 11;
BA_ "SignalLongName" SG_ 1911 DTCI_DTCFailType_777 "Diagnostic Trouble Code Information Extended 777 : Diagnostic Trouble Code Failure Type";
BA_ "SignalType" SG_ 1911 DTCI_DTCFailType_777 "UNM";
BA_ "VNSigAllNodes" SG_ 1911 DTCI_DTCNumber_777 1;
BA_ "PacketOrder" SG_ 1911 DTCI_DTCNumber_777 10;
BA_ "SignalLongName" SG_ 1911 DTCI_DTCNumber_777 "Diagnostic Trouble Code Information Extended 777 : Diagnostic Trouble Code Number";
BA_ "SignalType" SG_ 1911 DTCI_DTCNumber_777 "UNM";
BA_ "VNSigAllNodes" SG_ 1911 DTCI_DTCSource_777 1;
BA_ "PacketOrder" SG_ 1911 DTCI_DTCSource_777 9;
BA_ "SignalLongName" SG_ 1911 DTCI_DTCSource_777 "Diagnostic Trouble Code Information Extended 777 : Diagnostic Trouble Code Source";
BA_ "SignalType" SG_ 1911 DTCI_DTCSource_777 "UNM";
BA_ "VNSigAllNodes" SG_ 1911 DTCI_DTCTriggered_777 1;
BA_ "PacketOrder" SG_ 1911 DTCI_DTCTriggered_777 8;
BA_ "SignalLongName" SG_ 1911 DTCI_DTCTriggered_777 "Diagnostic Trouble Code Information Extended 777 : Diagnostic Trouble Code Triggered";
BA_ "SignalType" SG_ 1911 DTCI_DTCTriggered_777 "BLN";
BA_ "VNSigAllNodes" SG_ 1911 DTCIUnused7_777 1;
BA_ "PacketOrder" SG_ 1911 DTCIUnused7_777 7;
BA_ "SignalLongName" SG_ 1911 DTCIUnused7_777 "Diagnostic Trouble Code Information Extended 777 : Unused 7";
BA_ "SignalType" SG_ 1911 DTCIUnused7_777 "BLN";
BA_ "VNSigAllNodes" SG_ 1911 DTCIUnused6_777 1;
BA_ "PacketOrder" SG_ 1911 DTCIUnused6_777 6;
BA_ "SignalLongName" SG_ 1911 DTCIUnused6_777 "Diagnostic Trouble Code Information Extended 777 : Unused 6";
BA_ "SignalType" SG_ 1911 DTCIUnused6_777 "BLN";
BA_ "VNSigAllNodes" SG_ 1911 DTCIUnused5_777 1;
BA_ "PacketOrder" SG_ 1911 DTCIUnused5_777 5;
BA_ "SignalLongName" SG_ 1911 DTCIUnused5_777 "Diagnostic Trouble Code Information Extended 777 : Unused 5";
BA_ "SignalType" SG_ 1911 DTCIUnused5_777 "BLN";
BA_ "VNSigAllNodes" SG_ 1911 DTCIUnused4_777 1;
BA_ "PacketOrder" SG_ 1911 DTCIUnused4_777 4;
BA_ "SignalLongName" SG_ 1911 DTCIUnused4_777 "Diagnostic Trouble Code Information Extended 777 : Unused 4";
BA_ "SignalType" SG_ 1911 DTCIUnused4_777 "BLN";
BA_ "VNSigAllNodes" SG_ 1911 DTCIUnused3_777 1;
BA_ "PacketOrder" SG_ 1911 DTCIUnused3_777 3;
BA_ "SignalLongName" SG_ 1911 DTCIUnused3_777 "Diagnostic Trouble Code Information Extended 777 : Unused 3";
BA_ "SignalType" SG_ 1911 DTCIUnused3_777 "BLN";
BA_ "VNSigAllNodes" SG_ 1911 DTCIUnused2_777 1;
BA_ "PacketOrder" SG_ 1911 DTCIUnused2_777 2;
BA_ "SignalLongName" SG_ 1911 DTCIUnused2_777 "Diagnostic Trouble Code Information Extended 777 : Unused 2";
BA_ "SignalType" SG_ 1911 DTCIUnused2_777 "BLN";
BA_ "VNSigAllNodes" SG_ 1911 DTCIUnused1_777 1;
BA_ "PacketOrder" SG_ 1911 DTCIUnused1_777 1;
BA_ "SignalLongName" SG_ 1911 DTCIUnused1_777 "Diagnostic Trouble Code Information Extended 777 : Unused 1";
BA_ "SignalType" SG_ 1911 DTCIUnused1_777 "BLN";
BA_ "DiagRequest" BO_ 583 1;
BA_ "Prio" BO_ 583 0;
BA_ "MessageSubnet" BO_ 583 2;
BA_ "VNSigAllNodes" SG_ 583 DgnInf 1;
BA_ "VNSigSLHSSharedDiagnostic" SG_ 583 DgnInf 1;
BA_ "SignalLongName" SG_ 583 DgnInf "Diagnostic Information";
BA_ "SignalType" SG_ 583 DgnInf "UNM";
BA_ "GenMsgILSupport" BO_ 1351 0;
BA_ "Prio" BO_ 1351 0;
BA_ "TpApplType" BO_ 1351 "DiagUUDTResponse";
BA_ "MessageSubnet" BO_ 1351 2;
BA_ "VNSigAllNodes" SG_ 1351 DgnInf_HS547 1;
BA_ "VNSigSLHSSharedDiagnostic" SG_ 1351 DgnInf_HS547 1;
BA_ "SignalLongName" SG_ 1351 DgnInf_HS547 "Diagnostic Information HS547";
BA_ "SignalType" SG_ 1351 DgnInf_HS547 "UNM";
BA_ "DiagResponse" BO_ 1607 1;
BA_ "Prio" BO_ 1607 0;
BA_ "MessageSubnet" BO_ 1607 2;
BA_ "VNSigAllNodes" SG_ 1607 DgnInf 1;
BA_ "VNSigSLHSSharedDiagnostic" SG_ 1607 DgnInf 1;
BA_ "SignalLongName" SG_ 1607 DgnInf "Diagnostic Information";
BA_ "SignalType" SG_ 1607 DgnInf "UNM";
BA_ "Prio" BO_ 1906 6;
BA_ "GenMsgSendType" BO_ 1906 0;
BA_ "GenMsgCycleTime" BO_ 1906 1000;
BA_ "MessageSubnet" BO_ 1906 2;
BA_ "VNSigAllNodes" SG_ 1906 DTCI_DTCFaultType_772 1;
BA_ "PacketOrder" SG_ 1906 DTCI_DTCFaultType_772 20;
BA_ "SignalLongName" SG_ 1906 DTCI_DTCFaultType_772 "Diagnostic Trouble Code Information Extended 772 : Diagnostic Trouble Code Fault Type";
BA_ "SignalType" SG_ 1906 DTCI_DTCFaultType_772 "ENM";
BA_ "VNSigAllNodes" SG_ 1906 DTCI_CodeSupported_772 1;
BA_ "PacketOrder" SG_ 1906 DTCI_CodeSupported_772 19;
BA_ "SignalLongName" SG_ 1906 DTCI_CodeSupported_772 "Diagnostic Trouble Code Information Extended 772 : Code Supported";
BA_ "SignalType" SG_ 1906 DTCI_CodeSupported_772 "BLN";
BA_ "VNSigAllNodes" SG_ 1906 DTCI_CurrentStatus_772 1;
BA_ "PacketOrder" SG_ 1906 DTCI_CurrentStatus_772 18;
BA_ "SignalLongName" SG_ 1906 DTCI_CurrentStatus_772 "Diagnostic Trouble Code Information Extended 772 : Current Status";
BA_ "SignalType" SG_ 1906 DTCI_CurrentStatus_772 "BLN";
BA_ "VNSigAllNodes" SG_ 1906 DTCI_TstNPsdCdClrdSt_772 1;
BA_ "PacketOrder" SG_ 1906 DTCI_TstNPsdCdClrdSt_772 17;
BA_ "SignalLongName" SG_ 1906 DTCI_TstNPsdCdClrdSt_772 "Diagnostic Trouble Code Information Extended 772 : Test Not Passed Since Code Cleared Status";
BA_ "SignalType" SG_ 1906 DTCI_TstNPsdCdClrdSt_772 "BLN";
BA_ "VNSigAllNodes" SG_ 1906 DTCI_TstFldCdClrdStat_772 1;
BA_ "PacketOrder" SG_ 1906 DTCI_TstFldCdClrdStat_772 16;
BA_ "SignalLongName" SG_ 1906 DTCI_TstFldCdClrdStat_772 "Diagnostic Trouble Code Information Extended 772 : Test Failed Since Code Cleared Status";
BA_ "SignalType" SG_ 1906 DTCI_TstFldCdClrdStat_772 "BLN";
BA_ "VNSigAllNodes" SG_ 1906 DTCI_HistStat_772 1;
BA_ "PacketOrder" SG_ 1906 DTCI_HistStat_772 15;
BA_ "SignalLongName" SG_ 1906 DTCI_HistStat_772 "Diagnostic Trouble Code Information Extended 772 : History Status";
BA_ "SignalType" SG_ 1906 DTCI_HistStat_772 "BLN";
BA_ "VNSigAllNodes" SG_ 1906 DTCI_TstNPsdPwrUpSt_772 1;
BA_ "PacketOrder" SG_ 1906 DTCI_TstNPsdPwrUpSt_772 14;
BA_ "SignalLongName" SG_ 1906 DTCI_TstNPsdPwrUpSt_772 "Diagnostic Trouble Code Information Extended 772 : Test Not Passed Since Power Up Status";
BA_ "SignalType" SG_ 1906 DTCI_TstNPsdPwrUpSt_772 "BLN";
BA_ "VNSigAllNodes" SG_ 1906 DTCI_TstFldPwrUpSt_772 1;
BA_ "PacketOrder" SG_ 1906 DTCI_TstFldPwrUpSt_772 13;
BA_ "SignalLongName" SG_ 1906 DTCI_TstFldPwrUpSt_772 "Diagnostic Trouble Code Information Extended 772 : Test Failed Since Power Up Status";
BA_ "SignalType" SG_ 1906 DTCI_TstFldPwrUpSt_772 "BLN";
BA_ "VNSigAllNodes" SG_ 1906 DTCI_WrnIndRqdSt_772 1;
BA_ "PacketOrder" SG_ 1906 DTCI_WrnIndRqdSt_772 12;
BA_ "SignalLongName" SG_ 1906 DTCI_WrnIndRqdSt_772 "Diagnostic Trouble Code Information Extended 772 : Warning Indicator Requested Status";
BA_ "SignalType" SG_ 1906 DTCI_WrnIndRqdSt_772 "BLN";
BA_ "VNSigAllNodes" SG_ 1906 DTCI_DTCFailType_772 1;
BA_ "PacketOrder" SG_ 1906 DTCI_DTCFailType_772 11;
BA_ "SignalLongName" SG_ 1906 DTCI_DTCFailType_772 "Diagnostic Trouble Code Information Extended 772 : Diagnostic Trouble Code Failure Type";
BA_ "SignalType" SG_ 1906 DTCI_DTCFailType_772 "UNM";
BA_ "VNSigAllNodes" SG_ 1906 DTCI_DTCNumber_772 1;
BA_ "PacketOrder" SG_ 1906 DTCI_DTCNumber_772 10;
BA_ "SignalLongName" SG_ 1906 DTCI_DTCNumber_772 "Diagnostic Trouble Code Information Extended 772 : Diagnostic Trouble Code Number";
BA_ "SignalType" SG_ 1906 DTCI_DTCNumber_772 "UNM";
BA_ "VNSigAllNodes" SG_ 1906 DTCI_DTCSource_772 1;
BA_ "PacketOrder" SG_ 1906 DTCI_DTCSource_772 9;
BA_ "SignalLongName" SG_ 1906 DTCI_DTCSource_772 "Diagnostic Trouble Code Information Extended 772 : Diagnostic Trouble Code Source";
BA_ "SignalType" SG_ 1906 DTCI_DTCSource_772 "UNM";
BA_ "VNSigAllNodes" SG_ 1906 DTCI_DTCTriggered_772 1;
BA_ "PacketOrder" SG_ 1906 DTCI_DTCTriggered_772 8;
BA_ "SignalLongName" SG_ 1906 DTCI_DTCTriggered_772 "Diagnostic Trouble Code Information Extended 772 : Diagnostic Trouble Code Triggered";
BA_ "SignalType" SG_ 1906 DTCI_DTCTriggered_772 "BLN";
BA_ "VNSigAllNodes" SG_ 1906 DTCIUnused7_772 1;
BA_ "PacketOrder" SG_ 1906 DTCIUnused7_772 7;
BA_ "SignalLongName" SG_ 1906 DTCIUnused7_772 "Diagnostic Trouble Code Information Extended 772 : Unused 7";
BA_ "SignalType" SG_ 1906 DTCIUnused7_772 "BLN";
BA_ "VNSigAllNodes" SG_ 1906 DTCIUnused6_772 1;
BA_ "PacketOrder" SG_ 1906 DTCIUnused6_772 6;
BA_ "SignalLongName" SG_ 1906 DTCIUnused6_772 "Diagnostic Trouble Code Information Extended 772 : Unused 6";
BA_ "SignalType" SG_ 1906 DTCIUnused6_772 "BLN";
BA_ "VNSigAllNodes" SG_ 1906 DTCIUnused5_772 1;
BA_ "PacketOrder" SG_ 1906 DTCIUnused5_772 5;
BA_ "SignalLongName" SG_ 1906 DTCIUnused5_772 "Diagnostic Trouble Code Information Extended 772 : Unused 5";
BA_ "SignalType" SG_ 1906 DTCIUnused5_772 "BLN";
BA_ "VNSigAllNodes" SG_ 1906 DTCIUnused4_772 1;
BA_ "PacketOrder" SG_ 1906 DTCIUnused4_772 4;
BA_ "SignalLongName" SG_ 1906 DTCIUnused4_772 "Diagnostic Trouble Code Information Extended 772 : Unused 4";
BA_ "SignalType" SG_ 1906 DTCIUnused4_772 "BLN";
BA_ "VNSigAllNodes" SG_ 1906 DTCIUnused3_772 1;
BA_ "PacketOrder" SG_ 1906 DTCIUnused3_772 3;
BA_ "SignalLongName" SG_ 1906 DTCIUnused3_772 "Diagnostic Trouble Code Information Extended 772 : Unused 3";
BA_ "SignalType" SG_ 1906 DTCIUnused3_772 "BLN";
BA_ "VNSigAllNodes" SG_ 1906 DTCIUnused2_772 1;
BA_ "PacketOrder" SG_ 1906 DTCIUnused2_772 2;
BA_ "SignalLongName" SG_ 1906 DTCIUnused2_772 "Diagnostic Trouble Code Information Extended 772 : Unused 2";
BA_ "SignalType" SG_ 1906 DTCIUnused2_772 "BLN";
BA_ "VNSigAllNodes" SG_ 1906 DTCIUnused1_772 1;
BA_ "PacketOrder" SG_ 1906 DTCIUnused1_772 1;
BA_ "SignalLongName" SG_ 1906 DTCIUnused1_772 "Diagnostic Trouble Code Information Extended 772 : Unused 1";
BA_ "SignalType" SG_ 1906 DTCIUnused1_772 "BLN";
BA_ "Prio" BO_ 1907 6;
BA_ "GenMsgSendType" BO_ 1907 0;
BA_ "GenMsgCycleTime" BO_ 1907 1000;
BA_ "MessageSubnet" BO_ 1907 2;
BA_ "VNSigAllNodes" SG_ 1907 DTCI_DTCFaultType_773 1;
BA_ "PacketOrder" SG_ 1907 DTCI_DTCFaultType_773 20;
BA_ "SignalLongName" SG_ 1907 DTCI_DTCFaultType_773 "Diagnostic Trouble Code Information Extended 773 : Diagnostic Trouble Code Fault Type";
BA_ "SignalType" SG_ 1907 DTCI_DTCFaultType_773 "ENM";
BA_ "VNSigAllNodes" SG_ 1907 DTCI_CodeSupported_773 1;
BA_ "PacketOrder" SG_ 1907 DTCI_CodeSupported_773 19;
BA_ "SignalLongName" SG_ 1907 DTCI_CodeSupported_773 "Diagnostic Trouble Code Information Extended 773 : Code Supported";
BA_ "SignalType" SG_ 1907 DTCI_CodeSupported_773 "BLN";
BA_ "VNSigAllNodes" SG_ 1907 DTCI_CurrentStatus_773 1;
BA_ "PacketOrder" SG_ 1907 DTCI_CurrentStatus_773 18;
BA_ "SignalLongName" SG_ 1907 DTCI_CurrentStatus_773 "Diagnostic Trouble Code Information Extended 773 : Current Status";
BA_ "SignalType" SG_ 1907 DTCI_CurrentStatus_773 "BLN";
BA_ "VNSigAllNodes" SG_ 1907 DTCI_TstNPsdCdClrdSt_773 1;
BA_ "PacketOrder" SG_ 1907 DTCI_TstNPsdCdClrdSt_773 17;
BA_ "SignalLongName" SG_ 1907 DTCI_TstNPsdCdClrdSt_773 "Diagnostic Trouble Code Information Extended 773 : Test Not Passed Since Code Cleared Status";
BA_ "SignalType" SG_ 1907 DTCI_TstNPsdCdClrdSt_773 "BLN";
BA_ "VNSigAllNodes" SG_ 1907 DTCI_TstFldCdClrdStat_773 1;
BA_ "PacketOrder" SG_ 1907 DTCI_TstFldCdClrdStat_773 16;
BA_ "SignalLongName" SG_ 1907 DTCI_TstFldCdClrdStat_773 "Diagnostic Trouble Code Information Extended 773 : Test Failed Since Code Cleared Status";
BA_ "SignalType" SG_ 1907 DTCI_TstFldCdClrdStat_773 "BLN";
BA_ "VNSigAllNodes" SG_ 1907 DTCI_HistStat_773 1;
BA_ "PacketOrder" SG_ 1907 DTCI_HistStat_773 15;
BA_ "SignalLongName" SG_ 1907 DTCI_HistStat_773 "Diagnostic Trouble Code Information Extended 773 : History Status";
BA_ "SignalType" SG_ 1907 DTCI_HistStat_773 "BLN";
BA_ "VNSigAllNodes" SG_ 1907 DTCI_TstNPsdPwrUpSt_773 1;
BA_ "PacketOrder" SG_ 1907 DTCI_TstNPsdPwrUpSt_773 14;
BA_ "SignalLongName" SG_ 1907 DTCI_TstNPsdPwrUpSt_773 "Diagnostic Trouble Code Information Extended 773 : Test Not Passed Since Power Up Status";
BA_ "SignalType" SG_ 1907 DTCI_TstNPsdPwrUpSt_773 "BLN";
BA_ "VNSigAllNodes" SG_ 1907 DTCI_TstFldPwrUpSt_773 1;
BA_ "PacketOrder" SG_ 1907 DTCI_TstFldPwrUpSt_773 13;
BA_ "SignalLongName" SG_ 1907 DTCI_TstFldPwrUpSt_773 "Diagnostic Trouble Code Information Extended 773 : Test Failed Since Power Up Status";
BA_ "SignalType" SG_ 1907 DTCI_TstFldPwrUpSt_773 "BLN";
BA_ "VNSigAllNodes" SG_ 1907 DTCI_WrnIndRqdSt_773 1;
BA_ "PacketOrder" SG_ 1907 DTCI_WrnIndRqdSt_773 12;
BA_ "SignalLongName" SG_ 1907 DTCI_WrnIndRqdSt_773 "Diagnostic Trouble Code Information Extended 773 : Warning Indicator Requested Status";
BA_ "SignalType" SG_ 1907 DTCI_WrnIndRqdSt_773 "BLN";
BA_ "VNSigAllNodes" SG_ 1907 DTCI_DTCFailType_773 1;
BA_ "PacketOrder" SG_ 1907 DTCI_DTCFailType_773 11;
BA_ "SignalLongName" SG_ 1907 DTCI_DTCFailType_773 "Diagnostic Trouble Code Information Extended 773 : Diagnostic Trouble Code Failure Type";
BA_ "SignalType" SG_ 1907 DTCI_DTCFailType_773 "UNM";
BA_ "VNSigAllNodes" SG_ 1907 DTCI_DTCNumber_773 1;
BA_ "PacketOrder" SG_ 1907 DTCI_DTCNumber_773 10;
BA_ "SignalLongName" SG_ 1907 DTCI_DTCNumber_773 "Diagnostic Trouble Code Information Extended 773 : Diagnostic Trouble Code Number";
BA_ "SignalType" SG_ 1907 DTCI_DTCNumber_773 "UNM";
BA_ "VNSigAllNodes" SG_ 1907 DTCI_DTCSource_773 1;
BA_ "PacketOrder" SG_ 1907 DTCI_DTCSource_773 9;
BA_ "SignalLongName" SG_ 1907 DTCI_DTCSource_773 "Diagnostic Trouble Code Information Extended 773 : Diagnostic Trouble Code Source";
BA_ "SignalType" SG_ 1907 DTCI_DTCSource_773 "UNM";
BA_ "VNSigAllNodes" SG_ 1907 DTCI_DTCTriggered_773 1;
BA_ "PacketOrder" SG_ 1907 DTCI_DTCTriggered_773 8;
BA_ "SignalLongName" SG_ 1907 DTCI_DTCTriggered_773 "Diagnostic Trouble Code Information Extended 773 : Diagnostic Trouble Code Triggered";
BA_ "SignalType" SG_ 1907 DTCI_DTCTriggered_773 "BLN";
BA_ "VNSigAllNodes" SG_ 1907 DTCIUnused7_773 1;
BA_ "PacketOrder" SG_ 1907 DTCIUnused7_773 7;
BA_ "SignalLongName" SG_ 1907 DTCIUnused7_773 "Diagnostic Trouble Code Information Extended 773 : Unused 7";
BA_ "SignalType" SG_ 1907 DTCIUnused7_773 "BLN";
BA_ "VNSigAllNodes" SG_ 1907 DTCIUnused6_773 1;
BA_ "PacketOrder" SG_ 1907 DTCIUnused6_773 6;
BA_ "SignalLongName" SG_ 1907 DTCIUnused6_773 "Diagnostic Trouble Code Information Extended 773 : Unused 6";
BA_ "SignalType" SG_ 1907 DTCIUnused6_773 "BLN";
BA_ "VNSigAllNodes" SG_ 1907 DTCIUnused5_773 1;
BA_ "PacketOrder" SG_ 1907 DTCIUnused5_773 5;
BA_ "SignalLongName" SG_ 1907 DTCIUnused5_773 "Diagnostic Trouble Code Information Extended 773 : Unused 5";
BA_ "SignalType" SG_ 1907 DTCIUnused5_773 "BLN";
BA_ "VNSigAllNodes" SG_ 1907 DTCIUnused4_773 1;
BA_ "PacketOrder" SG_ 1907 DTCIUnused4_773 4;
BA_ "SignalLongName" SG_ 1907 DTCIUnused4_773 "Diagnostic Trouble Code Information Extended 773 : Unused 4";
BA_ "SignalType" SG_ 1907 DTCIUnused4_773 "BLN";
BA_ "VNSigAllNodes" SG_ 1907 DTCIUnused3_773 1;
BA_ "PacketOrder" SG_ 1907 DTCIUnused3_773 3;
BA_ "SignalLongName" SG_ 1907 DTCIUnused3_773 "Diagnostic Trouble Code Information Extended 773 : Unused 3";
BA_ "SignalType" SG_ 1907 DTCIUnused3_773 "BLN";
BA_ "VNSigAllNodes" SG_ 1907 DTCIUnused2_773 1;
BA_ "PacketOrder" SG_ 1907 DTCIUnused2_773 2;
BA_ "SignalLongName" SG_ 1907 DTCIUnused2_773 "Diagnostic Trouble Code Information Extended 773 : Unused 2";
BA_ "SignalType" SG_ 1907 DTCIUnused2_773 "BLN";
BA_ "VNSigAllNodes" SG_ 1907 DTCIUnused1_773 1;
BA_ "PacketOrder" SG_ 1907 DTCIUnused1_773 1;
BA_ "SignalLongName" SG_ 1907 DTCIUnused1_773 "Diagnostic Trouble Code Information Extended 773 : Unused 1";
BA_ "SignalType" SG_ 1907 DTCIUnused1_773 "BLN";
BA_ "DiagRequest" BO_ 579 1;
BA_ "Prio" BO_ 579 0;
BA_ "MessageSubnet" BO_ 579 2;
BA_ "VNSigAllNodes" SG_ 579 DgnInf 1;
BA_ "VNSigSLHSSharedDiagnostic" SG_ 579 DgnInf 1;
BA_ "SignalLongName" SG_ 579 DgnInf "Diagnostic Information";
BA_ "SignalType" SG_ 579 DgnInf "UNM";
BA_ "DiagResponse" BO_ 1603 1;
BA_ "Prio" BO_ 1603 0;
BA_ "MessageSubnet" BO_ 1603 2;
BA_ "VNSigAllNodes" SG_ 1603 DgnInf 1;
BA_ "VNSigSLHSSharedDiagnostic" SG_ 1603 DgnInf 1;
BA_ "SignalLongName" SG_ 1603 DgnInf "Diagnostic Information";
BA_ "SignalType" SG_ 1603 DgnInf "UNM";
BA_ "GenMsgILSupport" BO_ 1347 0;
BA_ "Prio" BO_ 1347 0;
BA_ "TpApplType" BO_ 1347 "DiagUUDTResponse";
BA_ "MessageSubnet" BO_ 1347 2;
BA_ "VNSigAllNodes" SG_ 1347 DgnInf_HS543 1;
BA_ "VNSigSLHSSharedDiagnostic" SG_ 1347 DgnInf_HS543 1;
BA_ "SignalLongName" SG_ 1347 DgnInf_HS543 "Diagnostic Information HS543";
BA_ "SignalType" SG_ 1347 DgnInf_HS543 "UNM";
BA_ "Prio" BO_ 1915 6;
BA_ "GenMsgSendType" BO_ 1915 0;
BA_ "GenMsgCycleTime" BO_ 1915 1000;
BA_ "MessageSubnet" BO_ 1915 2;
BA_ "VNSigAllNodes" SG_ 1915 DTCI_DTCFaultType_77B 1;
BA_ "PacketOrder" SG_ 1915 DTCI_DTCFaultType_77B 20;
BA_ "SignalLongName" SG_ 1915 DTCI_DTCFaultType_77B "Diagnostic Trouble Code Information Extended 77B : Diagnostic Trouble Code Fault Type";
BA_ "SignalType" SG_ 1915 DTCI_DTCFaultType_77B "ENM";
BA_ "VNSigAllNodes" SG_ 1915 DTCI_CodeSupported_77B 1;
BA_ "PacketOrder" SG_ 1915 DTCI_CodeSupported_77B 19;
BA_ "SignalLongName" SG_ 1915 DTCI_CodeSupported_77B "Diagnostic Trouble Code Information Extended 77B : Code Supported";
BA_ "SignalType" SG_ 1915 DTCI_CodeSupported_77B "BLN";
BA_ "VNSigAllNodes" SG_ 1915 DTCI_CurrentStatus_77B 1;
BA_ "PacketOrder" SG_ 1915 DTCI_CurrentStatus_77B 18;
BA_ "SignalLongName" SG_ 1915 DTCI_CurrentStatus_77B "Diagnostic Trouble Code Information Extended 77B : Current Status";
BA_ "SignalType" SG_ 1915 DTCI_CurrentStatus_77B "BLN";
BA_ "VNSigAllNodes" SG_ 1915 DTCI_TstNPsdCdClrdSt_77B 1;
BA_ "PacketOrder" SG_ 1915 DTCI_TstNPsdCdClrdSt_77B 17;
BA_ "SignalLongName" SG_ 1915 DTCI_TstNPsdCdClrdSt_77B "Diagnostic Trouble Code Information Extended 77B : Test Not Passed Since Code Cleared Status";
BA_ "SignalType" SG_ 1915 DTCI_TstNPsdCdClrdSt_77B "BLN";
BA_ "VNSigAllNodes" SG_ 1915 DTCI_TstFldCdClrdStat_77B 1;
BA_ "PacketOrder" SG_ 1915 DTCI_TstFldCdClrdStat_77B 16;
BA_ "SignalLongName" SG_ 1915 DTCI_TstFldCdClrdStat_77B "Diagnostic Trouble Code Information Extended 77B : Test Failed Since Code Cleared Status";
BA_ "SignalType" SG_ 1915 DTCI_TstFldCdClrdStat_77B "BLN";
BA_ "VNSigAllNodes" SG_ 1915 DTCI_HistStat_77B 1;
BA_ "PacketOrder" SG_ 1915 DTCI_HistStat_77B 15;
BA_ "SignalLongName" SG_ 1915 DTCI_HistStat_77B "Diagnostic Trouble Code Information Extended 77B : History Status";
BA_ "SignalType" SG_ 1915 DTCI_HistStat_77B "BLN";
BA_ "VNSigAllNodes" SG_ 1915 DTCI_TstNPsdPwrUpSt_77B 1;
BA_ "PacketOrder" SG_ 1915 DTCI_TstNPsdPwrUpSt_77B 14;
BA_ "SignalLongName" SG_ 1915 DTCI_TstNPsdPwrUpSt_77B "Diagnostic Trouble Code Information Extended 77B : Test Not Passed Since Power Up Status";
BA_ "SignalType" SG_ 1915 DTCI_TstNPsdPwrUpSt_77B "BLN";
BA_ "VNSigAllNodes" SG_ 1915 DTCI_TstFldPwrUpSt_77B 1;
BA_ "PacketOrder" SG_ 1915 DTCI_TstFldPwrUpSt_77B 13;
BA_ "SignalLongName" SG_ 1915 DTCI_TstFldPwrUpSt_77B "Diagnostic Trouble Code Information Extended 77B : Test Failed Since Power Up Status";
BA_ "SignalType" SG_ 1915 DTCI_TstFldPwrUpSt_77B "BLN";
BA_ "VNSigAllNodes" SG_ 1915 DTCI_WrnIndRqdSt_77B 1;
BA_ "PacketOrder" SG_ 1915 DTCI_WrnIndRqdSt_77B 12;
BA_ "SignalLongName" SG_ 1915 DTCI_WrnIndRqdSt_77B "Diagnostic Trouble Code Information Extended 77B : Warning Indicator Requested Status";
BA_ "SignalType" SG_ 1915 DTCI_WrnIndRqdSt_77B "BLN";
BA_ "VNSigAllNodes" SG_ 1915 DTCI_DTCFailType_77B 1;
BA_ "PacketOrder" SG_ 1915 DTCI_DTCFailType_77B 11;
BA_ "SignalLongName" SG_ 1915 DTCI_DTCFailType_77B "Diagnostic Trouble Code Information Extended 77B : Diagnostic Trouble Code Failure Type";
BA_ "SignalType" SG_ 1915 DTCI_DTCFailType_77B "UNM";
BA_ "VNSigAllNodes" SG_ 1915 DTCI_DTCNumber_77B 1;
BA_ "PacketOrder" SG_ 1915 DTCI_DTCNumber_77B 10;
BA_ "SignalLongName" SG_ 1915 DTCI_DTCNumber_77B "Diagnostic Trouble Code Information Extended 77B : Diagnostic Trouble Code Number";
BA_ "SignalType" SG_ 1915 DTCI_DTCNumber_77B "UNM";
BA_ "VNSigAllNodes" SG_ 1915 DTCI_DTCSource_77B 1;
BA_ "PacketOrder" SG_ 1915 DTCI_DTCSource_77B 9;
BA_ "SignalLongName" SG_ 1915 DTCI_DTCSource_77B "Diagnostic Trouble Code Information Extended 77B : Diagnostic Trouble Code Source";
BA_ "SignalType" SG_ 1915 DTCI_DTCSource_77B "UNM";
BA_ "VNSigAllNodes" SG_ 1915 DTCI_DTCTriggered_77B 1;
BA_ "PacketOrder" SG_ 1915 DTCI_DTCTriggered_77B 8;
BA_ "SignalLongName" SG_ 1915 DTCI_DTCTriggered_77B "Diagnostic Trouble Code Information Extended 77B : Diagnostic Trouble Code Triggered";
BA_ "SignalType" SG_ 1915 DTCI_DTCTriggered_77B "BLN";
BA_ "VNSigAllNodes" SG_ 1915 DTCIUnused7_77B 1;
BA_ "PacketOrder" SG_ 1915 DTCIUnused7_77B 7;
BA_ "SignalLongName" SG_ 1915 DTCIUnused7_77B "Diagnostic Trouble Code Information Extended 77B : Unused 7";
BA_ "SignalType" SG_ 1915 DTCIUnused7_77B "BLN";
BA_ "VNSigAllNodes" SG_ 1915 DTCIUnused6_77B 1;
BA_ "PacketOrder" SG_ 1915 DTCIUnused6_77B 6;
BA_ "SignalLongName" SG_ 1915 DTCIUnused6_77B "Diagnostic Trouble Code Information Extended 77B : Unused 6";
BA_ "SignalType" SG_ 1915 DTCIUnused6_77B "BLN";
BA_ "VNSigAllNodes" SG_ 1915 DTCIUnused5_77B 1;
BA_ "PacketOrder" SG_ 1915 DTCIUnused5_77B 5;
BA_ "SignalLongName" SG_ 1915 DTCIUnused5_77B "Diagnostic Trouble Code Information Extended 77B : Unused 5";
BA_ "SignalType" SG_ 1915 DTCIUnused5_77B "BLN";
BA_ "VNSigAllNodes" SG_ 1915 DTCIUnused4_77B 1;
BA_ "PacketOrder" SG_ 1915 DTCIUnused4_77B 4;
BA_ "SignalLongName" SG_ 1915 DTCIUnused4_77B "Diagnostic Trouble Code Information Extended 77B : Unused 4";
BA_ "SignalType" SG_ 1915 DTCIUnused4_77B "BLN";
BA_ "VNSigAllNodes" SG_ 1915 DTCIUnused3_77B 1;
BA_ "PacketOrder" SG_ 1915 DTCIUnused3_77B 3;
BA_ "SignalLongName" SG_ 1915 DTCIUnused3_77B "Diagnostic Trouble Code Information Extended 77B : Unused 3";
BA_ "SignalType" SG_ 1915 DTCIUnused3_77B "BLN";
BA_ "VNSigAllNodes" SG_ 1915 DTCIUnused2_77B 1;
BA_ "PacketOrder" SG_ 1915 DTCIUnused2_77B 2;
BA_ "SignalLongName" SG_ 1915 DTCIUnused2_77B "Diagnostic Trouble Code Information Extended 77B : Unused 2";
BA_ "SignalType" SG_ 1915 DTCIUnused2_77B "BLN";
BA_ "VNSigAllNodes" SG_ 1915 DTCIUnused1_77B 1;
BA_ "PacketOrder" SG_ 1915 DTCIUnused1_77B 1;
BA_ "SignalLongName" SG_ 1915 DTCIUnused1_77B "Diagnostic Trouble Code Information Extended 77B : Unused 1";
BA_ "SignalType" SG_ 1915 DTCIUnused1_77B "BLN";
BA_ "DiagRequest" BO_ 587 1;
BA_ "GenMsgILSupport" BO_ 587 0;
BA_ "Prio" BO_ 587 0;
BA_ "MessageSubnet" BO_ 587 2;
BA_ "VNSigAllNodes" SG_ 587 DgnInf 1;
BA_ "VNSigSLHSSharedDiagnostic" SG_ 587 DgnInf 1;
BA_ "SignalLongName" SG_ 587 DgnInf "Diagnostic Information";
BA_ "SignalType" SG_ 587 DgnInf "UNM";
BA_ "GenMsgILSupport" BO_ 1611 0;
BA_ "DiagResponse" BO_ 1611 1;
BA_ "Prio" BO_ 1611 0;
BA_ "MessageSubnet" BO_ 1611 2;
BA_ "VNSigAllNodes" SG_ 1611 DgnInf 1;
BA_ "VNSigSLHSSharedDiagnostic" SG_ 1611 DgnInf 1;
BA_ "SignalLongName" SG_ 1611 DgnInf "Diagnostic Information";
BA_ "SignalType" SG_ 1611 DgnInf "UNM";
BA_ "GenMsgILSupport" BO_ 1355 0;
BA_ "Prio" BO_ 1355 0;
BA_ "TpApplType" BO_ 1355 "DiagUUDTResponse";
BA_ "MessageSubnet" BO_ 1355 2;
BA_ "VNSigAllNodes" SG_ 1355 DgnInf_HS54B 1;
BA_ "VNSigSLHSSharedDiagnostic" SG_ 1355 DgnInf_HS54B 1;
BA_ "SignalLongName" SG_ 1355 DgnInf_HS54B "Diagnostic Information HS54B";
BA_ "SignalType" SG_ 1355 DgnInf_HS54B "UNM";
BA_ "AppGenMsgCycleTime" BO_ 880 40;
BA_ "Prio" BO_ 880 0;
BA_ "MessageSubnet" BO_ 880 2;
BA_ "VNSigAllNodes" SG_ 880 FOAI_VehAhdIndRq 1;
BA_ "SignalLongName" SG_ 880 FOAI_VehAhdIndRq "Forward Object Alert Indications : Vehicle Ahead Indication Request";
BA_ "SignalType" SG_ 880 FOAI_VehAhdIndRq "ENM";
BA_ "VNSigAllNodes" SG_ 880 FOAI_AlrtWrnIndRq 1;
BA_ "SignalLongName" SG_ 880 FOAI_AlrtWrnIndRq "Forward Object Alert Indications : Alert Warning Indication Request";
BA_ "SignalType" SG_ 880 FOAI_AlrtWrnIndRq "ENM";
BA_ "VNSigAllNodes" SG_ 880 FOAI_AlrtChmIhbRq 1;
BA_ "SignalLongName" SG_ 880 FOAI_AlrtChmIhbRq "Forward Object Alert Indications : Alert Warning Chime Inhibit Request";
BA_ "SignalType" SG_ 880 FOAI_AlrtChmIhbRq "ENM";
BA_ "VNSigAllNodes" SG_ 880 FwdClnAlrtPr 1;
BA_ "SignalLongName" SG_ 880 FwdClnAlrtPr "Forward Collision Alert Present";
BA_ "SignalType" SG_ 880 FwdClnAlrtPr "BLN";
BA_ "VNSigAllNodes" SG_ 880 ACCUnavlbleDTWthrIO 1;
BA_ "SignalLongName" SG_ 880 ACCUnavlbleDTWthrIO "Adaptive Cruise Unavailable Due To Weather Indication On";
BA_ "SignalType" SG_ 880 ACCUnavlbleDTWthrIO "BLN";
BA_ "VNSigAllNodes" SG_ 880 ACCAct370 1;
BA_ "SignalLongName" SG_ 880 ACCAct370 "Adaptive Cruise Control Active";
BA_ "SignalType" SG_ 880 ACCAct370 "BLN";
BA_ "VNSigAllNodes" SG_ 880 DrvThrtlOvrdIO 1;
BA_ "SignalLongName" SG_ 880 DrvThrtlOvrdIO "Driver Throttle Override Indication On";
BA_ "SignalType" SG_ 880 DrvThrtlOvrdIO "BLN";
BA_ "VNSigAllNodes" SG_ 880 ServAdpCrsCtrlIndOn 1;
BA_ "SignalLongName" SG_ 880 ServAdpCrsCtrlIndOn "Service Adaptive Cruise Control Indication On";
BA_ "SignalType" SG_ 880 ServAdpCrsCtrlIndOn "BLN";
BA_ "VNSigAllNodes" SG_ 880 ACCDrvrSeltdSpd 1;
BA_ "SignalLongName" SG_ 880 ACCDrvrSeltdSpd "Adaptive Cruise Control Driver Selected Speed";
BA_ "SignalType" SG_ 880 ACCDrvrSeltdSpd "UNM";
BA_ "VNSigAllNodes" SG_ 880 ACCHdwayStngIO 1;
BA_ "SignalLongName" SG_ 880 ACCHdwayStngIO "Adaptive Cruise Control Headway Setting Indication On";
BA_ "SignalType" SG_ 880 ACCHdwayStngIO "BLN";
BA_ "VNSigAllNodes" SG_ 880 ACCHdwyStg 1;
BA_ "SignalLongName" SG_ 880 ACCHdwyStg "Adaptive Cruise Control Headway Setting";
BA_ "SignalType" SG_ 880 ACCHdwyStg "ENM";
BA_ "VNSigAllNodes" SG_ 880 ACCSnsClnRqdIO 1;
BA_ "SignalLongName" SG_ 880 ACCSnsClnRqdIO "Adaptive Cruise Control Sensor Cleaning Required Indication On";
BA_ "SignalType" SG_ 880 ACCSnsClnRqdIO "BLN";
BA_ "VNSigAllNodes" SG_ 880 ACCTmpUnavlbleIO 1;
BA_ "SignalLongName" SG_ 880 ACCTmpUnavlbleIO "Adaptive Cruise Control Temporarily Unavailable Indication On";
BA_ "SignalType" SG_ 880 ACCTmpUnavlbleIO "BLN";
BA_ "VNSigAllNodes" SG_ 880 ACCDrvrSeltdSpdIO 1;
BA_ "SignalLongName" SG_ 880 ACCDrvrSeltdSpdIO "Adaptive Cruise Control Driver Selected Speed Indication On";
BA_ "SignalType" SG_ 880 ACCDrvrSeltdSpdIO "BLN";
BA_ "Prio" BO_ 894 0;
BA_ "GenMsgSendType" BO_ 894 0;
BA_ "GenMsgCycleTime" BO_ 894 1500;
BA_ "MessageSubnet" BO_ 894 2;
BA_ "VNSigAllNodes" SG_ 894 RtLwBmFld 1;
BA_ "SignalLongName" SG_ 894 RtLwBmFld "Right Low Beam Failed";
BA_ "SignalType" SG_ 894 RtLwBmFld "BLN";
BA_ "VNSigAllNodes" SG_ 894 LftLwBmFld 1;
BA_ "SignalLongName" SG_ 894 LftLwBmFld "Left Low Beam Failed";
BA_ "SignalType" SG_ 894 LftLwBmFld "BLN";
BA_ "VNSigAllNodes" SG_ 894 AdvFrntLghtSysIndRq 1;
BA_ "SignalLongName" SG_ 894 AdvFrntLghtSysIndRq "Advanced Front Lighting System Indication Request";
BA_ "SignalType" SG_ 894 AdvFrntLghtSysIndRq "ENM";
BA_ "VNSigAllNodes" SG_ 894 HdLtLvlFlrIO 1;
BA_ "SignalLongName" SG_ 894 HdLtLvlFlrIO "Head Light Leveling Failure Indication On";
BA_ "SignalType" SG_ 894 HdLtLvlFlrIO "BLN";
BA_ "DiagRequest" BO_ 577 1;
BA_ "Prio" BO_ 577 0;
BA_ "MessageSubnet" BO_ 577 2;
BA_ "VNSigAllNodes" SG_ 577 DgnInf 1;
BA_ "VNSigSLHSSharedDiagnostic" SG_ 577 DgnInf 1;
BA_ "SignalLongName" SG_ 577 DgnInf "Diagnostic Information";
BA_ "SignalType" SG_ 577 DgnInf "UNM";
BA_ "Prio" BO_ 298 0;
BA_ "GenMsgSendType" BO_ 298 0;
BA_ "GenMsgCycleTime" BO_ 298 100;
BA_ "MessageSubnet" BO_ 298 2;
BA_ "VNSigAllNodes" SG_ 298 SpdLmtrSttngTyp 1;
BA_ "SignalLongName" SG_ 298 SpdLmtrSttngTyp "Speed Limiter Setting Type";
BA_ "SignalType" SG_ 298 SpdLmtrSttngTyp "ENM";
BA_ "VNSigAllNodes" SG_ 298 TCSysDisSwAtv 1;
BA_ "SignalLongName" SG_ 298 TCSysDisSwAtv "Traction Control System Disable Switch Active";
BA_ "SignalType" SG_ 298 TCSysDisSwAtv "BLN";
BA_ "VNSigAllNodes" SG_ 298 AutoMdSpdLmtCnfrmd 1;
BA_ "SignalLongName" SG_ 298 AutoMdSpdLmtCnfrmd "Auto Mode Speed Limit Confirmed";
BA_ "SignalType" SG_ 298 AutoMdSpdLmtCnfrmd "BLN";
BA_ "VNSigAllNodes" SG_ 298 TCSysDisSwAtvARC 1;
BA_ "SignalLongName" SG_ 298 TCSysDisSwAtvARC "Traction Control System Disable Switch Active Alive Rolling Count";
BA_ "SignalType" SG_ 298 TCSysDisSwAtvARC "UNM";
BA_ "VNSigAllNodes" SG_ 298 ChmAct 1;
BA_ "SignalLongName" SG_ 298 ChmAct "Chime Active";
BA_ "SignalType" SG_ 298 ChmAct "BLN";
BA_ "VNSigAllNodes" SG_ 298 DDAjrSwAtvM 1;
BA_ "SignalLongName" SG_ 298 DDAjrSwAtvM "Driver Door Ajar Switch Active Mask";
BA_ "SignalType" SG_ 298 DDAjrSwAtvM "ENM";
BA_ "VNSigAllNodes" SG_ 298 CrshAlrtDrvrSlctdType 1;
BA_ "SignalLongName" SG_ 298 CrshAlrtDrvrSlctdType "Crash Alert Driver Selected Type";
BA_ "SignalType" SG_ 298 CrshAlrtDrvrSlctdType "ENM";
BA_ "VNSigAllNodes" SG_ 298 PsSbltAtcV 1;
BA_ "SignalLongName" SG_ 298 PsSbltAtcV "Passenger Seatbelt Attached Validity";
BA_ "SignalType" SG_ 298 PsSbltAtcV "ENM";
BA_ "VNSigAllNodes" SG_ 298 PsSbltAtc 1;
BA_ "SignalLongName" SG_ 298 PsSbltAtc "Passenger Seatbelt Attached";
BA_ "SignalType" SG_ 298 PsSbltAtc "BLN";
BA_ "VNSigAllNodes" SG_ 298 TrlrBrkDsplyAct 1;
BA_ "SignalLongName" SG_ 298 TrlrBrkDsplyAct "Trailer Brake Display Active";
BA_ "SignalType" SG_ 298 TrlrBrkDsplyAct "BLN";
BA_ "VNSigAllNodes" SG_ 298 RdSpdCatType 1;
BA_ "SignalLongName" SG_ 298 RdSpdCatType "Road Speed Category Type";
BA_ "SignalType" SG_ 298 RdSpdCatType "ENM";
BA_ "VNSigAllNodes" SG_ 298 LnCat 1;
BA_ "SignalLongName" SG_ 298 LnCat "Lane Category";
BA_ "SignalType" SG_ 298 LnCat "ENM";
BA_ "VNSigAllNodes" SG_ 298 FncRdClass 1;
BA_ "SignalLongName" SG_ 298 FncRdClass "Functional Road Class";
BA_ "SignalType" SG_ 298 FncRdClass "ENM";
BA_ "VNSigAllNodes" SG_ 298 SprtLnRd 1;
BA_ "SignalLongName" SG_ 298 SprtLnRd "Separate Lane Road";
BA_ "SignalType" SG_ 298 SprtLnRd "BLN";
BA_ "VNSigAllNodes" SG_ 298 CntrldAccRd 1;
BA_ "SignalLongName" SG_ 298 CntrldAccRd "Controlled Access Road";
BA_ "SignalType" SG_ 298 CntrldAccRd "BLN";
BA_ "VNSigAllNodes" SG_ 298 BldUpArDet 1;
BA_ "SignalLongName" SG_ 298 BldUpArDet "Build Up Area Detected";
BA_ "SignalType" SG_ 298 BldUpArDet "BLN";
BA_ "VNSigAllNodes" SG_ 298 MpDataAvlbl 1;
BA_ "SignalLongName" SG_ 298 MpDataAvlbl "Map Data Available";
BA_ "SignalType" SG_ 298 MpDataAvlbl "BLN";
BA_ "VNSigAllNodes" SG_ 298 SusCustStngReq 1;
BA_ "SignalLongName" SG_ 298 SusCustStngReq "Suspension Customization Setting Request";
BA_ "SignalType" SG_ 298 SusCustStngReq "ENM";
BA_ "VNSigAllNodes" SG_ 298 StrCustStngReq 1;
BA_ "SignalLongName" SG_ 298 StrCustStngReq "Steering Customization Setting Request";
BA_ "SignalType" SG_ 298 StrCustStngReq "ENM";
BA_ "VNSigAllNodes" SG_ 298 RstrCustFctrDef 1;
BA_ "SignalLongName" SG_ 298 RstrCustFctrDef "Restore Customization Factory Defaults";
BA_ "SignalType" SG_ 298 RstrCustFctrDef "ENM";
BA_ "VNSigAllNodes" SG_ 298 DrvlnCustStngReq 1;
BA_ "SignalLongName" SG_ 298 DrvlnCustStngReq "Driveline Customization Setting Request";
BA_ "SignalType" SG_ 298 DrvlnCustStngReq "ENM";
BA_ "VNSigAllNodes" SG_ 298 ChmMstrVDA 1;
BA_ "SignalLongName" SG_ 298 ChmMstrVDA "Chime Master Virtual Device Availability";
BA_ "GenSigStartValue" SG_ 298 ChmMstrVDA 1;
BA_ "SignalType" SG_ 298 ChmMstrVDA "ENM";
BA_ "VNSigAllNodes" SG_ 298 IPCVDA 1;
BA_ "SignalLongName" SG_ 298 IPCVDA "Instrument Panel Cluster Virtual Device Availability";
BA_ "GenSigStartValue" SG_ 298 IPCVDA 1;
BA_ "SignalType" SG_ 298 IPCVDA "ENM";
BA_ "VNSigAllNodes" SG_ 298 HeadUpDispVDA 1;
BA_ "SignalLongName" SG_ 298 HeadUpDispVDA "Head Up Display Virtual Device Availability";
BA_ "GenSigStartValue" SG_ 298 HeadUpDispVDA 1;
BA_ "SignalType" SG_ 298 HeadUpDispVDA "ENM";
BA_ "VNSigAllNodes" SG_ 298 HapticSeatVDA 1;
BA_ "SignalLongName" SG_ 298 HapticSeatVDA "Haptic Seat Virtual Device Availability";
BA_ "GenSigStartValue" SG_ 298 HapticSeatVDA 1;
BA_ "SignalType" SG_ 298 HapticSeatVDA "ENM";
BA_ "VNSigAllNodes" SG_ 298 RRDoorAjarSwAct 1;
BA_ "SignalLongName" SG_ 298 RRDoorAjarSwAct "Rear Right Door Ajar Switch Active";
BA_ "SignalType" SG_ 298 RRDoorAjarSwAct "BLN";
BA_ "VNSigAllNodes" SG_ 298 PDAjrSwAtv 1;
BA_ "SignalLongName" SG_ 298 PDAjrSwAtv "Passenger Door Ajar Switch Active";
BA_ "SignalType" SG_ 298 PDAjrSwAtv "BLN";
BA_ "VNSigAllNodes" SG_ 298 DDAjrSwAtv 1;
BA_ "SignalLongName" SG_ 298 DDAjrSwAtv "Driver Door Ajar Switch Active";
BA_ "SignalType" SG_ 298 DDAjrSwAtv "BLN";
BA_ "VNSigAllNodes" SG_ 298 TrlrHWIntrfcVDA 1;
BA_ "SignalLongName" SG_ 298 TrlrHWIntrfcVDA "Trailer Hardware Interface Virtual Device Availability";
BA_ "GenSigStartValue" SG_ 298 TrlrHWIntrfcVDA 1;
BA_ "SignalType" SG_ 298 TrlrHWIntrfcVDA "ENM";
BA_ "VNSigAllNodes" SG_ 298 DrId 1;
BA_ "SignalLongName" SG_ 298 DrId "Driver Identifier";
BA_ "GenSigStartValue" SG_ 298 DrId 7;
BA_ "SignalType" SG_ 298 DrId "ENM";
BA_ "VNSigAllNodes" SG_ 298 EnrgMgtLdShdRq 1;
BA_ "SignalLongName" SG_ 298 EnrgMgtLdShdRq "Energy Management Load Shedding Request";
BA_ "SignalType" SG_ 298 EnrgMgtLdShdRq "ENM";
BA_ "VNSigAllNodes" SG_ 298 DrSbltAtcV 1;
BA_ "SignalLongName" SG_ 298 DrSbltAtcV "Driver Seatbelt Attached Validity";
BA_ "SignalType" SG_ 298 DrSbltAtcV "ENM";
BA_ "VNSigAllNodes" SG_ 298 TrlrHtchSwAtv 1;
BA_ "SignalLongName" SG_ 298 TrlrHtchSwAtv "Trailer Hitch Switch Active";
BA_ "SignalType" SG_ 298 TrlrHtchSwAtv "BLN";
BA_ "VNSigAllNodes" SG_ 298 TreInfMonSysRstReq 1;
BA_ "SignalLongName" SG_ 298 TreInfMonSysRstReq "Tire Inflation Monitoring System Reset Requested";
BA_ "SignalType" SG_ 298 TreInfMonSysRstReq "BLN";
BA_ "VNSigAllNodes" SG_ 298 HUDActv 1;
BA_ "SignalLongName" SG_ 298 HUDActv "Head Up Display Active";
BA_ "SignalType" SG_ 298 HUDActv "BLN";
BA_ "VNSigAllNodes" SG_ 298 BatVltV 1;
BA_ "SignalLongName" SG_ 298 BatVltV "Battery Voltage Validity";
BA_ "SignalType" SG_ 298 BatVltV "ENM";
BA_ "VNSigAllNodes" SG_ 298 BatVlt 1;
BA_ "SignalLongName" SG_ 298 BatVlt "Battery Voltage";
BA_ "SignalType" SG_ 298 BatVlt "UNM";
BA_ "VNSigAllNodes" SG_ 298 RLDoorAjarSwAct 1;
BA_ "SignalLongName" SG_ 298 RLDoorAjarSwAct "Rear Left Door Ajar Switch Active";
BA_ "SignalType" SG_ 298 RLDoorAjarSwAct "BLN";
BA_ "VNSigAllNodes" SG_ 298 DrSbltAtc 1;
BA_ "SignalLongName" SG_ 298 DrSbltAtc "Driver Seatbelt Attached";
BA_ "SignalType" SG_ 298 DrSbltAtc "BLN";
BA_ "Prio" BO_ 1322 0;
BA_ "GenMsgSendType" BO_ 1322 0;
BA_ "GenMsgCycleTime" BO_ 1322 1000;
BA_ "MessageSubnet" BO_ 1322 2;
BA_ "VNSigAllNodes" SG_ 1322 TireRRPrsV 1;
BA_ "SignalLongName" SG_ 1322 TireRRPrsV "Tire Right Rear Pressure Validity";
BA_ "SignalType" SG_ 1322 TireRRPrsV "ENM";
BA_ "VNSigAllNodes" SG_ 1322 TireRRPrsStat 1;
BA_ "SignalLongName" SG_ 1322 TireRRPrsStat "Tire Right Rear Pressure Status";
BA_ "SignalType" SG_ 1322 TireRRPrsStat "ENM";
BA_ "VNSigAllNodes" SG_ 1322 TireRRPrs 1;
BA_ "SignalLongName" SG_ 1322 TireRRPrs "Tire Right Rear Pressure";
BA_ "GenSigStartValue" SG_ 1322 TireRRPrs 255;
BA_ "SignalType" SG_ 1322 TireRRPrs "UNM";
BA_ "VNSigAllNodes" SG_ 1322 TireRFPrsV 1;
BA_ "SignalLongName" SG_ 1322 TireRFPrsV "Tire Right Front Pressure Validity";
BA_ "SignalType" SG_ 1322 TireRFPrsV "ENM";
BA_ "VNSigAllNodes" SG_ 1322 TireRFPrsStat 1;
BA_ "SignalLongName" SG_ 1322 TireRFPrsStat "Tire Right Front Pressure Status";
BA_ "SignalType" SG_ 1322 TireRFPrsStat "ENM";
BA_ "VNSigAllNodes" SG_ 1322 TireRFPrs 1;
BA_ "SignalLongName" SG_ 1322 TireRFPrs "Tire Right Front Pressure";
BA_ "GenSigStartValue" SG_ 1322 TireRFPrs 255;
BA_ "SignalType" SG_ 1322 TireRFPrs "UNM";
BA_ "VNSigAllNodes" SG_ 1322 TireLRPrsV 1;
BA_ "SignalLongName" SG_ 1322 TireLRPrsV "Tire Left Rear Pressure Validity";
BA_ "SignalType" SG_ 1322 TireLRPrsV "ENM";
BA_ "VNSigAllNodes" SG_ 1322 TireLRPrsStat 1;
BA_ "SignalLongName" SG_ 1322 TireLRPrsStat "Tire Left Rear Pressure Status";
BA_ "SignalType" SG_ 1322 TireLRPrsStat "ENM";
BA_ "VNSigAllNodes" SG_ 1322 TireLRPrs 1;
BA_ "SignalLongName" SG_ 1322 TireLRPrs "Tire Left Rear Pressure";
BA_ "GenSigStartValue" SG_ 1322 TireLRPrs 255;
BA_ "SignalType" SG_ 1322 TireLRPrs "UNM";
BA_ "VNSigAllNodes" SG_ 1322 TireLFPrsV 1;
BA_ "SignalLongName" SG_ 1322 TireLFPrsV "Tire Left Front Pressure Validity";
BA_ "SignalType" SG_ 1322 TireLFPrsV "ENM";
BA_ "VNSigAllNodes" SG_ 1322 TireLFPrsStat 1;
BA_ "SignalLongName" SG_ 1322 TireLFPrsStat "Tire Left Front Pressure Status";
BA_ "SignalType" SG_ 1322 TireLFPrsStat "ENM";
BA_ "VNSigAllNodes" SG_ 1322 TireLFPrs 1;
BA_ "SignalLongName" SG_ 1322 TireLFPrs "Tire Left Front Pressure";
BA_ "GenSigStartValue" SG_ 1322 TireLFPrs 255;
BA_ "SignalType" SG_ 1322 TireLFPrs "UNM";
BA_ "DiagResponse" BO_ 1601 1;
BA_ "Prio" BO_ 1601 0;
BA_ "MessageSubnet" BO_ 1601 2;
BA_ "VNSigAllNodes" SG_ 1601 DgnInf 1;
BA_ "VNSigSLHSSharedDiagnostic" SG_ 1601 DgnInf 1;
BA_ "SignalLongName" SG_ 1601 DgnInf "Diagnostic Information";
BA_ "SignalType" SG_ 1601 DgnInf "UNM";
BA_ "DiagRequest" BO_ 2018 1;
BA_ "Prio" BO_ 2018 0;
BA_ "MessageSubnet" BO_ 2018 2;
BA_ "VNSigAllNodes" SG_ 2018 DgnInf 1;
BA_ "VNSigSLHSSharedDiagnostic" SG_ 2018 DgnInf 1;
BA_ "SignalLongName" SG_ 2018 DgnInf "Diagnostic Information";
BA_ "SignalType" SG_ 2018 DgnInf "UNM";
BA_ "DiagResponse" BO_ 2026 1;
BA_ "Prio" BO_ 2026 0;
BA_ "MessageSubnet" BO_ 2026 2;
BA_ "VNSigAllNodes" SG_ 2026 DgnInf 1;
BA_ "VNSigSLHSSharedDiagnostic" SG_ 2026 DgnInf 1;
BA_ "SignalLongName" SG_ 2026 DgnInf "Diagnostic Information";
BA_ "SignalType" SG_ 2026 DgnInf "UNM";
BA_ "GenMsgILSupport" BO_ 1514 0;
BA_ "Prio" BO_ 1514 0;
BA_ "TpApplType" BO_ 1514 "DiagUUDTResponse";
BA_ "MessageSubnet" BO_ 1514 2;
BA_ "VNSigAllNodes" SG_ 1514 DgnInf 1;
BA_ "VNSigSLHSSharedDiagnostic" SG_ 1514 DgnInf 1;
BA_ "SignalLongName" SG_ 1514 DgnInf "Diagnostic Information";
BA_ "SignalType" SG_ 1514 DgnInf "UNM";
BA_ "Prio" BO_ 1300 0;
BA_ "GenMsgSendType" BO_ 1300 0;
BA_ "GenMsgCycleTime" BO_ 1300 1000;
BA_ "MessageSubnet" BO_ 1300 2;
BA_ "VNSigAllNodes" SG_ 1300 VehIdNmDig2_9 1;
BA_ "SignalLongName" SG_ 1300 VehIdNmDig2_9 "Vehicle Identification Number Digits 2-9";
BA_ "SignalType" SG_ 1300 VehIdNmDig2_9 "ASC";
BA_ "Prio" BO_ 288 0;
BA_ "GenMsgSendType" BO_ 288 0;
BA_ "GenMsgCycleTime" BO_ 288 5000;
BA_ "MessageSubnet" BO_ 288 2;
BA_ "VNSigAllNodes" SG_ 288 VehOdo 1;
BA_ "SignalLongName" SG_ 288 VehOdo "Vehicle Odometer";
BA_ "SignalType" SG_ 288 VehOdo "UNM";
BA_ "VNSigAllNodes" SG_ 288 VehOdoV 1;
BA_ "SignalLongName" SG_ 288 VehOdoV "Vehicle Odometer Validity";
BA_ "SignalType" SG_ 288 VehOdoV "ENM";
BA_ "DiagRequest" BO_ 2020 1;
BA_ "Prio" BO_ 2020 0;
BA_ "MessageSubnet" BO_ 2020 2;
BA_ "VNSigAllNodes" SG_ 2020 DgnInf 1;
BA_ "VNSigSLHSSharedDiagnostic" SG_ 2020 DgnInf 1;
BA_ "SignalLongName" SG_ 2020 DgnInf "Diagnostic Information";
BA_ "SignalType" SG_ 2020 DgnInf "UNM";
BA_ "DiagResponse" BO_ 2028 1;
BA_ "Prio" BO_ 2028 0;
BA_ "MessageSubnet" BO_ 2028 2;
BA_ "VNSigAllNodes" SG_ 2028 DgnInf 1;
BA_ "VNSigSLHSSharedDiagnostic" SG_ 2028 DgnInf 1;
BA_ "SignalLongName" SG_ 2028 DgnInf "Diagnostic Information";
BA_ "SignalType" SG_ 2028 DgnInf "UNM";
BA_ "GenMsgILSupport" BO_ 1516 0;
BA_ "Prio" BO_ 1516 0;
BA_ "TpApplType" BO_ 1516 "DiagUUDTResponse";
BA_ "MessageSubnet" BO_ 1516 2;
BA_ "VNSigAllNodes" SG_ 1516 DgnInf 1;
BA_ "VNSigSLHSSharedDiagnostic" SG_ 1516 DgnInf 1;
BA_ "SignalLongName" SG_ 1516 DgnInf "Diagnostic Information";
BA_ "SignalType" SG_ 1516 DgnInf "UNM";
BA_ "Prio" BO_ 485 0;
BA_ "GenMsgSendType" BO_ 485 0;
BA_ "GenMsgCycleTime" BO_ 485 10;
BA_ "MessageSubnet" BO_ 485 2;
BA_ "VNSigAllNodes" SG_ 485 StrAngSnsChksm 1;
BA_ "SignalLongName" SG_ 485 StrAngSnsChksm "Steering Angle Sensor Checksum";
BA_ "SignalType" SG_ 485 StrAngSnsChksm "UNM";
BA_ "VNSigAllNodes" SG_ 485 StrWhAngGrdV 1;
BA_ "SignalLongName" SG_ 485 StrWhAngGrdV "Steering Wheel Angle Gradient Validity";
BA_ "SignalType" SG_ 485 StrWhAngGrdV "ENM";
BA_ "VNSigAllNodes" SG_ 485 StrWhAngGrdMsk 1;
BA_ "SignalLongName" SG_ 485 StrWhAngGrdMsk "Steering Wheel Angle Gradient Mask";
BA_ "SignalType" SG_ 485 StrWhAngGrdMsk "ENM";
BA_ "VNSigAllNodes" SG_ 485 StrWhAngMsk 1;
BA_ "SignalLongName" SG_ 485 StrWhAngMsk "Steering Wheel Angle Mask";
BA_ "SignalType" SG_ 485 StrWhAngMsk "ENM";
BA_ "VNSigAllNodes" SG_ 485 StrWhlAngSenTyp 1;
BA_ "SignalLongName" SG_ 485 StrWhlAngSenTyp "Steering Wheel Angle Sensor Type";
BA_ "SignalType" SG_ 485 StrWhlAngSenTyp "ENM";
BA_ "VNSigAllNodes" SG_ 485 StrWhlAngSenCalStat 1;
BA_ "SignalLongName" SG_ 485 StrWhlAngSenCalStat "Steering Wheel Angle Sensor Calibration Status";
BA_ "SignalType" SG_ 485 StrWhlAngSenCalStat "ENM";
BA_ "VNSigAllNodes" SG_ 485 StrWhAngGrd 1;
BA_ "SignalLongName" SG_ 485 StrWhAngGrd "Steering Wheel Angle Gradient";
BA_ "SignalType" SG_ 485 StrWhAngGrd "SNM";
BA_ "VNSigAllNodes" SG_ 485 StWhlAngAliveRollCnt 1;
BA_ "SignalLongName" SG_ 485 StWhlAngAliveRollCnt "Steering Wheel Angle Alive Rolling Count";
BA_ "SignalType" SG_ 485 StWhlAngAliveRollCnt "UNM";
BA_ "VNSigAllNodes" SG_ 485 StrWhAngV 1;
BA_ "SignalLongName" SG_ 485 StrWhAngV "Steering Wheel Angle Validity";
BA_ "SignalType" SG_ 485 StrWhAngV "ENM";
BA_ "VNSigAllNodes" SG_ 485 StrWhAng 1;
BA_ "SignalLongName" SG_ 485 StrWhAng "Steering Wheel Angle";
BA_ "SignalType" SG_ 485 StrWhAng "SNM";
BA_ "Prio" BO_ 1001 0;
BA_ "GenMsgSendType" BO_ 1001 0;
BA_ "GenMsgCycleTime" BO_ 1001 100;
BA_ "MessageSubnet" BO_ 1001 2;
BA_ "VNSigAllNodes" SG_ 1001 DistRollCntAvgDrvnSrc 1;
BA_ "SignalLongName" SG_ 1001 DistRollCntAvgDrvnSrc "Distance Rolling Count Average Driven Source";
BA_ "SignalType" SG_ 1001 DistRollCntAvgDrvnSrc "ENM";
BA_ "VNSigAllNodes" SG_ 1001 VehSpdAvgDrvnSrc 1;
BA_ "SignalLongName" SG_ 1001 VehSpdAvgDrvnSrc "Vehicle Speed Average Driven Source";
BA_ "SignalType" SG_ 1001 VehSpdAvgDrvnSrc "ENM";
BA_ "VNSigAllNodes" SG_ 1001 DstRolCntAvgNonDrvnV 1;
BA_ "SignalLongName" SG_ 1001 DstRolCntAvgNonDrvnV "Distance Rolling Count Average Non Driven Validity";
BA_ "SignalType" SG_ 1001 DstRolCntAvgNonDrvnV "ENM";
BA_ "VNSigAllNodes" SG_ 1001 DstRolCntAvNDrRstOc 1;
BA_ "SignalLongName" SG_ 1001 DstRolCntAvNDrRstOc "Distance Rolling Count Average Non Driven Reset Occurred";
BA_ "SignalType" SG_ 1001 DstRolCntAvNDrRstOc "BLN";
BA_ "VNSigAllNodes" SG_ 1001 DstRolCntAvgNonDrvn 1;
BA_ "SignalLongName" SG_ 1001 DstRolCntAvgNonDrvn "Distance Rolling Count Average Non Driven";
BA_ "SignalType" SG_ 1001 DstRolCntAvgNonDrvn "UNM";
BA_ "VNSigAllNodes" SG_ 1001 DistRollCntAvgDrvnV 1;
BA_ "SignalLongName" SG_ 1001 DistRollCntAvgDrvnV "Distance Rolling Count Average Driven Validity";
BA_ "SignalType" SG_ 1001 DistRollCntAvgDrvnV "ENM";
BA_ "VNSigAllNodes" SG_ 1001 DstRolCntAvgDrnRstOc 1;
BA_ "SignalLongName" SG_ 1001 DstRolCntAvgDrnRstOc "Distance Rolling Count Average Driven Reset Occurred";
BA_ "SignalType" SG_ 1001 DstRolCntAvgDrnRstOc "BLN";
BA_ "VNSigAllNodes" SG_ 1001 DistRollCntAvgDrvn 1;
BA_ "SignalLongName" SG_ 1001 DistRollCntAvgDrvn "Distance Rolling Count Average Driven";
BA_ "SignalType" SG_ 1001 DistRollCntAvgDrvn "UNM";
BA_ "VNSigAllNodes" SG_ 1001 VehSpdAvgNDrvnV 1;
BA_ "SignalLongName" SG_ 1001 VehSpdAvgNDrvnV "Vehicle Speed Average Non Driven Validity";
BA_ "SignalType" SG_ 1001 VehSpdAvgNDrvnV "ENM";
BA_ "VNSigAllNodes" SG_ 1001 VehSpdAvgNDrvn 1;
BA_ "SignalLongName" SG_ 1001 VehSpdAvgNDrvn "Vehicle Speed Average Non Driven";
BA_ "SignalType" SG_ 1001 VehSpdAvgNDrvn "UNM";
BA_ "VNSigAllNodes" SG_ 1001 VehSpdAvgDrvnV 1;
BA_ "SignalLongName" SG_ 1001 VehSpdAvgDrvnV "Vehicle Speed Average Driven Validity";
BA_ "SignalType" SG_ 1001 VehSpdAvgDrvnV "ENM";
BA_ "VNSigAllNodes" SG_ 1001 VehSpdAvgDrvn 1;
BA_ "SignalLongName" SG_ 1001 VehSpdAvgDrvn "Vehicle Speed Average Driven";
BA_ "SignalType" SG_ 1001 VehSpdAvgDrvn "UNM";
BA_ "Prio" BO_ 961 0;
BA_ "GenMsgSendType" BO_ 961 0;
BA_ "GenMsgCycleTime" BO_ 961 100;
BA_ "MessageSubnet" BO_ 961 2;
BA_ "VNSigAllNodes" SG_ 961 PTImmblzerInfo 1;
BA_ "SignalLongName" SG_ 961 PTImmblzerInfo "Powertrain Immobilizer Information";
BA_ "SignalType" SG_ 961 PTImmblzerInfo "UNM";
BA_ "Prio" BO_ 804 0;
BA_ "GenMsgSendType" BO_ 804 0;
BA_ "GenMsgCycleTime" BO_ 804 500;
BA_ "MessageSubnet" BO_ 804 2;
BA_ "VNSigAllNodes" SG_ 804 CompOvrhtIndOn 1;
BA_ "SignalLongName" SG_ 804 CompOvrhtIndOn "Compressor Overheated Indication On";
BA_ "SignalType" SG_ 804 CompOvrhtIndOn "BLN";
BA_ "VNSigAllNodes" SG_ 804 VehHghtStatV 1;
BA_ "SignalLongName" SG_ 804 VehHghtStatV "Vehicle Height Status Validity";
BA_ "SignalType" SG_ 804 VehHghtStatV "ENM";
BA_ "VNSigAllNodes" SG_ 804 VehHghtStat 1;
BA_ "SignalLongName" SG_ 804 VehHghtStat "Vehicle Height Status";
BA_ "SignalType" SG_ 804 VehHghtStat "ENM";
BA_ "VNSigAllNodes" SG_ 804 SrvLevSysIO 1;
BA_ "SignalLongName" SG_ 804 SrvLevSysIO "Service Leveling System Indication On";
BA_ "SignalType" SG_ 804 SrvLevSysIO "BLN";
BA_ "VNSigAllNodes" SG_ 804 LevSysVehTopSpdLim 1;
BA_ "SignalLongName" SG_ 804 LevSysVehTopSpdLim "Leveling System Vehicle Top Speed Limit Value";
BA_ "SignalType" SG_ 804 LevSysVehTopSpdLim "UNM";
BA_ "VNSigAllNodes" SG_ 804 VehOvrLdIndOn 1;
BA_ "SignalLongName" SG_ 804 VehOvrLdIndOn "Vehicle Overloaded Indication On";
BA_ "SignalType" SG_ 804 VehOvrLdIndOn "BLN";
BA_ "Prio" BO_ 842 0;
BA_ "GenMsgSendType" BO_ 842 0;
BA_ "GenMsgCycleTime" BO_ 842 50;
BA_ "MessageSubnet" BO_ 842 2;
BA_ "VNSigAllNodes" SG_ 842 WhlRotDrctnlSRtNDrvn 1;
BA_ "SignalLongName" SG_ 842 WhlRotDrctnlSRtNDrvn "Wheel Rotational Directional Status Right Non Driven";
BA_ "SignalType" SG_ 842 WhlRotDrctnlSRtNDrvn "ENM";
BA_ "VNSigAllNodes" SG_ 842 WhlRotDrctnlStLfNDrvn 1;
BA_ "SignalLongName" SG_ 842 WhlRotDrctnlStLfNDrvn "Wheel Rotational Directional Status Left Non Driven";
BA_ "SignalType" SG_ 842 WhlRotDrctnlStLfNDrvn "ENM";
BA_ "VNSigAllNodes" SG_ 842 WhlGrndVlctyRtNnDrvnV 1;
BA_ "SignalLongName" SG_ 842 WhlGrndVlctyRtNnDrvnV "Wheel Ground Velocity Right Non Driven Validity";
BA_ "SignalType" SG_ 842 WhlGrndVlctyRtNnDrvnV "ENM";
BA_ "VNSigAllNodes" SG_ 842 WhlGrndVlctyRtNnDrvn 1;
BA_ "SignalLongName" SG_ 842 WhlGrndVlctyRtNnDrvn "Wheel Ground Velocity Right Non Driven";
BA_ "SignalType" SG_ 842 WhlGrndVlctyRtNnDrvn "UNM";
BA_ "VNSigAllNodes" SG_ 842 WhlGrndVlctyLftNnDrvnV 1;
BA_ "SignalLongName" SG_ 842 WhlGrndVlctyLftNnDrvnV "Wheel Ground Velocity Left Non Driven Validity";
BA_ "SignalType" SG_ 842 WhlGrndVlctyLftNnDrvnV "ENM";
BA_ "VNSigAllNodes" SG_ 842 WhlGrndVlctyLftNnDrvn 1;
BA_ "SignalLongName" SG_ 842 WhlGrndVlctyLftNnDrvn "Wheel Ground Velocity Left Non Driven";
BA_ "SignalType" SG_ 842 WhlGrndVlctyLftNnDrvn "UNM";
BA_ "Prio" BO_ 1241 0;
BA_ "GenMsgSendType" BO_ 1241 0;
BA_ "GenMsgCycleTime" BO_ 1241 500;
BA_ "MessageSubnet" BO_ 1241 2;
BA_ "VNSigAllNodes" SG_ 1241 FSERDTC_CdNum 1;
BA_ "PacketOrder" SG_ 1241 FSERDTC_CdNum 2;
BA_ "SignalLongName" SG_ 1241 FSERDTC_CdNum "Fuel System Emissions Related DTC : Code Number";
BA_ "SignalType" SG_ 1241 FSERDTC_CdNum "UNM";
BA_ "VNSigAllNodes" SG_ 1241 FSERDTC_SysDes 1;
BA_ "PacketOrder" SG_ 1241 FSERDTC_SysDes 1;
BA_ "SignalLongName" SG_ 1241 FSERDTC_SysDes "Fuel System Emissions Related DTC : System Designator";
BA_ "SignalType" SG_ 1241 FSERDTC_SysDes "ENM";
BA_ "VNSigAllNodes" SG_ 1241 FuelSysEmsRldMlfAtv 1;
BA_ "SignalLongName" SG_ 1241 FuelSysEmsRldMlfAtv "Fuel System Emissions Related Malfunction Active";
BA_ "SignalType" SG_ 1241 FuelSysEmsRldMlfAtv "BLN";
BA_ "Prio" BO_ 491 0;
BA_ "GenMsgSendType" BO_ 491 0;
BA_ "GenMsgCycleTime" BO_ 491 12;
BA_ "MessageSubnet" BO_ 491 2;
BA_ "VNSigAllNodes" SG_ 491 ExhPrsRgVlv2Pos 1;
BA_ "SignalLongName" SG_ 491 ExhPrsRgVlv2Pos "Exhaust Pressure Regulator Valve 2 Position";
BA_ "SignalType" SG_ 491 ExhPrsRgVlv2Pos "ENM";
BA_ "VNSigAllNodes" SG_ 491 ExhPrsRgVlv2PosV 1;
BA_ "SignalLongName" SG_ 491 ExhPrsRgVlv2PosV "Exhaust Pressure Regulator Valve 2 Position Validity";
BA_ "SignalType" SG_ 491 ExhPrsRgVlv2PosV "ENM";
BA_ "VNSigAllNodes" SG_ 491 ExhPrsRgVlvPosV 1;
BA_ "SignalLongName" SG_ 491 ExhPrsRgVlvPosV "Exhaust Pressure Regulator Valve Position Validity";
BA_ "SignalType" SG_ 491 ExhPrsRgVlvPosV "ENM";
BA_ "VNSigAllNodes" SG_ 491 ExhPrsRgVlvPos 1;
BA_ "SignalLongName" SG_ 491 ExhPrsRgVlvPos "Exhaust Pressure Regulator Valve Position";
BA_ "SignalType" SG_ 491 ExhPrsRgVlvPos "ENM";
BA_ "VNSigAllNodes" SG_ 491 FuelSysEstPressDlvrd 1;
BA_ "SignalLongName" SG_ 491 FuelSysEstPressDlvrd "Fuel System Estimated Pressure Delivered";
BA_ "SignalType" SG_ 491 FuelSysEstPressDlvrd "UNM";
BA_ "VNSigAllNodes" SG_ 491 FuelSysEstPressDlvrdV 1;
BA_ "SignalLongName" SG_ 491 FuelSysEstPressDlvrdV "Fuel System Estimated Pressure Delivered Validity";
BA_ "SignalType" SG_ 491 FuelSysEstPressDlvrdV "ENM";
BA_ "Prio" BO_ 1019 0;
BA_ "GenMsgSendType" BO_ 1019 0;
BA_ "GenMsgCycleTime" BO_ 1019 250;
BA_ "MessageSubnet" BO_ 1019 2;
BA_ "VNSigAllNodes" SG_ 1019 FuelAlchlCompAdptnPrg 1;
BA_ "SignalLongName" SG_ 1019 FuelAlchlCompAdptnPrg "Fuel Alcohol Composition Adaptation in Progress";
BA_ "SignalType" SG_ 1019 FuelAlchlCompAdptnPrg "BLN";
BA_ "VNSigAllNodes" SG_ 1019 FuelLvlEmnsRelStat 1;
BA_ "SignalLongName" SG_ 1019 FuelLvlEmnsRelStat "Fuel Level Emissions Related Status";
BA_ "SignalType" SG_ 1019 FuelLvlEmnsRelStat "ENM";
BA_ "VNSigAllNodes" SG_ 1019 EmnsRelFuelLvlLw 1;
BA_ "SignalLongName" SG_ 1019 EmnsRelFuelLvlLw "Emissions Related Fuel Level Low";
BA_ "SignalType" SG_ 1019 EmnsRelFuelLvlLw "BLN";
BA_ "VNSigAllNodes" SG_ 1019 EngFuelCntlState 1;
BA_ "SignalLongName" SG_ 1019 EngFuelCntlState "Engine Fuel Control State";
BA_ "SignalType" SG_ 1019 EngFuelCntlState "ENM";
BA_ "VNSigAllNodes" SG_ 1019 FuelAlcoholCompV 1;
BA_ "SignalLongName" SG_ 1019 FuelAlcoholCompV "Fuel Alcohol Composition Validity";
BA_ "SignalType" SG_ 1019 FuelAlcoholCompV "ENM";
BA_ "VNSigAllNodes" SG_ 1019 FuelAlcoholComp 1;
BA_ "SignalLongName" SG_ 1019 FuelAlcoholComp "Fuel Alcohol Composition";
BA_ "SignalType" SG_ 1019 FuelAlcoholComp "UNM";
BA_ "Prio" BO_ 493 0;
BA_ "GenMsgSendType" BO_ 493 0;
BA_ "GenMsgCycleTime" BO_ 493 12;
BA_ "MessageSubnet" BO_ 493 2;
BA_ "VNSigAllNodes" SG_ 493 EngRunng 1;
BA_ "SignalLongName" SG_ 493 EngRunng "Engine Running";
BA_ "SignalType" SG_ 493 EngRunng "BLN";
BA_ "VNSigAllNodes" SG_ 493 FlPmpEDscOtptCmdSta 1;
BA_ "SignalLongName" SG_ 493 FlPmpEDscOtptCmdSta "Fuel Pump Enabled Discrete Output Commanded Status";
BA_ "SignalType" SG_ 493 FlPmpEDscOtptCmdSta "ENM";
BA_ "VNSigAllNodes" SG_ 493 CmmndAirFuelRatio 1;
BA_ "SignalLongName" SG_ 493 CmmndAirFuelRatio "Commanded Air Fuel Ratio";
BA_ "SignalType" SG_ 493 CmmndAirFuelRatio "UNM";
BA_ "VNSigAllNodes" SG_ 493 AdvFuelFlowEst 1;
BA_ "SignalLongName" SG_ 493 AdvFuelFlowEst "Advanced Fuel Flow Estimate";
BA_ "SignalType" SG_ 493 AdvFuelFlowEst "UNM";
BA_ "VNSigAllNodes" SG_ 493 InstFuelFlowEst 1;
BA_ "SignalLongName" SG_ 493 InstFuelFlowEst "Instantaneous Fuel Flow Estimate";
BA_ "SignalType" SG_ 493 InstFuelFlowEst "UNM";
BA_ "VNSigAllNodes" SG_ 493 FuelDelPressRqd 1;
BA_ "SignalLongName" SG_ 493 FuelDelPressRqd "Fuel Delivery Pressure Requested";
BA_ "SignalType" SG_ 493 FuelDelPressRqd "UNM";
BA_ "VNSigAllNodes" SG_ 493 FuelCntlSysFltPrsnt 1;
BA_ "SignalLongName" SG_ 493 FuelCntlSysFltPrsnt "Fuel Control System Fault Present";
BA_ "SignalType" SG_ 493 FuelCntlSysFltPrsnt "BLN";
BA_ "Prio" BO_ 401 0;
BA_ "GenMsgSendType" BO_ 401 0;
BA_ "GenMsgCycleTime" BO_ 401 12;
BA_ "MessageSubnet" BO_ 401 2;
BA_ "VNSigAllNodes" SG_ 401 EngTrqTrnRqTmpFld 1;
BA_ "SignalLongName" SG_ 401 EngTrqTrnRqTmpFld "Engine Torque Transmission Request Temporarily Failed";
BA_ "SignalType" SG_ 401 EngTrqTrnRqTmpFld "BLN";
BA_ "VNSigAllNodes" SG_ 401 EngTrqTrnRqLmtd 1;
BA_ "SignalLongName" SG_ 401 EngTrqTrnRqLmtd "Engine Torque Transmission Request Limited";
BA_ "SignalType" SG_ 401 EngTrqTrnRqLmtd "BLN";
BA_ "VNSigAllNodes" SG_ 401 TrnsEngSpdReqFld 1;
BA_ "SignalLongName" SG_ 401 TrnsEngSpdReqFld "Transmission Engine Speed Request Failed";
BA_ "SignalType" SG_ 401 TrnsEngSpdReqFld "BLN";
BA_ "VNSigAllNodes" SG_ 401 ThrtCommndPos 1;
BA_ "SignalLongName" SG_ 401 ThrtCommndPos "Throttle Commanded Position";
BA_ "SignalType" SG_ 401 ThrtCommndPos "UNM";
BA_ "VNSigAllNodes" SG_ 401 EngTrqTnsRqFld 1;
BA_ "SignalLongName" SG_ 401 EngTrqTnsRqFld "Engine Torque Transmission Request Failed";
BA_ "SignalType" SG_ 401 EngTrqTnsRqFld "BLN";
BA_ "VNSigAllNodes" SG_ 401 EngTrqRdnFld 1;
BA_ "SignalLongName" SG_ 401 EngTrqRdnFld "Engine Torque Reduction Failed";
BA_ "SignalType" SG_ 401 EngTrqRdnFld "BLN";
BA_ "VNSigAllNodes" SG_ 401 EngNTrnsRegStdyStTqV 1;
BA_ "SignalLongName" SG_ 401 EngNTrnsRegStdyStTqV "Engine Non-Transmission Regulated Steady State Torque Validity";
BA_ "SignalType" SG_ 401 EngNTrnsRegStdyStTqV "ENM";
BA_ "VNSigAllNodes" SG_ 401 EngNTrnsRegStdyStTq 1;
BA_ "SignalLongName" SG_ 401 EngNTrnsRegStdyStTq "Engine Non-Transmission Regulated Steady State Torque";
BA_ "SignalType" SG_ 401 EngNTrnsRegStdyStTq "UNM";
BA_ "VNSigAllNodes" SG_ 401 EngAirflwStdyStTorqV 1;
BA_ "SignalLongName" SG_ 401 EngAirflwStdyStTorqV "Engine Airflow Steady State Torque Validity";
BA_ "SignalType" SG_ 401 EngAirflwStdyStTorqV "ENM";
BA_ "VNSigAllNodes" SG_ 401 EngAirflwStdyStTorq 1;
BA_ "SignalLongName" SG_ 401 EngAirflwStdyStTorq "Engine Airflow Steady State Torque";
BA_ "SignalType" SG_ 401 EngAirflwStdyStTorq "UNM";
BA_ "VNSigAllNodes" SG_ 401 AccKdwnAtv 1;
BA_ "SignalLongName" SG_ 401 AccKdwnAtv "Accelerator Kick Down Detected";
BA_ "SignalType" SG_ 401 AccKdwnAtv "BLN";
BA_ "VNSigAllNodes" SG_ 401 AccPosV 1;
BA_ "SignalLongName" SG_ 401 AccPosV "Accelerator Effective Position Validity";
BA_ "SignalType" SG_ 401 AccPosV "ENM";
BA_ "VNSigAllNodes" SG_ 401 AccPos 1;
BA_ "SignalLongName" SG_ 401 AccPos "Accelerator Effective Position";
BA_ "SignalType" SG_ 401 AccPos "UNM";
BA_ "VNSigAllNodes" SG_ 401 EngActStdyStTorqV 1;
BA_ "SignalLongName" SG_ 401 EngActStdyStTorqV "Engine Actual Steady State Torque Validity";
BA_ "SignalType" SG_ 401 EngActStdyStTorqV "ENM";
BA_ "VNSigAllNodes" SG_ 401 EngActStdyStTorq 1;
BA_ "SignalLongName" SG_ 401 EngActStdyStTorq "Engine Actual Steady State Torque";
BA_ "SignalType" SG_ 401 EngActStdyStTorq "UNM";
BA_ "Prio" BO_ 707 0;
BA_ "GenMsgSendType" BO_ 707 0;
BA_ "GenMsgCycleTime" BO_ 707 50;
BA_ "MessageSubnet" BO_ 707 2;
BA_ "VNSigAllNodes" SG_ 707 CSTATRS_ReqStat 1;
BA_ "PacketOrder" SG_ 707 CSTATRS_ReqStat 2;
BA_ "SignalLongName" SG_ 707 CSTATRS_ReqStat "Chassis System Total Axle Torque Request Status : Request Status";
BA_ "SignalType" SG_ 707 CSTATRS_ReqStat "ENM";
BA_ "VNSigAllNodes" SG_ 707 CSTATRS_LmtgStat 1;
BA_ "PacketOrder" SG_ 707 CSTATRS_LmtgStat 1;
BA_ "SignalLongName" SG_ 707 CSTATRS_LmtgStat "Chassis System Total Axle Torque Request Status : Limiting Status";
BA_ "SignalType" SG_ 707 CSTATRS_LmtgStat "ENM";
BA_ "VNSigAllNodes" SG_ 707 EngManfldAbsPrsV 1;
BA_ "SignalLongName" SG_ 707 EngManfldAbsPrsV "Engine Manifold Absolute Pressure Validity";
BA_ "SignalType" SG_ 707 EngManfldAbsPrsV "ENM";
BA_ "VNSigAllNodes" SG_ 707 EngManfldAbsPrs 1;
BA_ "SignalLongName" SG_ 707 EngManfldAbsPrs "Engine Manifold Absolute Pressure";
BA_ "SignalType" SG_ 707 EngManfldAbsPrs "UNM";
BA_ "VNSigAllNodes" SG_ 707 EngTrqMinExtRngV 1;
BA_ "SignalLongName" SG_ 707 EngTrqMinExtRngV "Engine Torque Minimum Extended Range Validity";
BA_ "SignalType" SG_ 707 EngTrqMinExtRngV "ENM";
BA_ "VNSigAllNodes" SG_ 707 EngTrqMinExtRng 1;
BA_ "SignalLongName" SG_ 707 EngTrqMinExtRng "Engine Torque Minimum Extended Range";
BA_ "GenSigStartValue" SG_ 707 EngTrqMinExtRng 1696;
BA_ "SignalType" SG_ 707 EngTrqMinExtRng "UNM";
BA_ "VNSigAllNodes" SG_ 707 EngTrqMaxExtRngV 1;
BA_ "SignalLongName" SG_ 707 EngTrqMaxExtRngV "Engine Torque Maximum Extended Range Validity";
BA_ "SignalType" SG_ 707 EngTrqMaxExtRngV "ENM";
BA_ "VNSigAllNodes" SG_ 707 EngTrqMaxExtRng 1;
BA_ "SignalLongName" SG_ 707 EngTrqMaxExtRng "Engine Torque Maximum Extended Range";
BA_ "GenSigStartValue" SG_ 707 EngTrqMaxExtRng 1696;
BA_ "SignalType" SG_ 707 EngTrqMaxExtRng "UNM";
BA_ "Prio" BO_ 1265 0;
BA_ "GenMsgSendType" BO_ 1265 0;
BA_ "GenMsgCycleTime" BO_ 1265 1000;
BA_ "MessageSubnet" BO_ 1265 2;
BA_ "VNSigAllNodes" SG_ 1265 PTSysHzrdLghtReq 1;
BA_ "SignalLongName" SG_ 1265 PTSysHzrdLghtReq "Powertrain System Hazard Lights Request";
BA_ "SignalType" SG_ 1265 PTSysHzrdLghtReq "BLN";
BA_ "VNSigAllNodes" SG_ 1265 EngOffTmPT 1;
BA_ "SignalLongName" SG_ 1265 EngOffTmPT "Engine Off Time Powertrain";
BA_ "SignalType" SG_ 1265 EngOffTmPT "UNM";
BA_ "VNSigAllNodes" SG_ 1265 EngOffTmPTV 1;
BA_ "SignalLongName" SG_ 1265 EngOffTmPTV "Engine Off Time Powertrain Validity";
BA_ "SignalType" SG_ 1265 EngOffTmPTV "ENM";
BA_ "VNSigAllNodes" SG_ 1265 EngOffTmPTM 1;
BA_ "SignalLongName" SG_ 1265 EngOffTmPTM "Engine Off Time Powertrain Mask";
BA_ "SignalType" SG_ 1265 EngOffTmPTM "ENM";
BA_ "VNSigAllNodes" SG_ 1265 WhlDistPrRevNDrvn 1;
BA_ "SignalLongName" SG_ 1265 WhlDistPrRevNDrvn "Wheel Distance Per Revolution Non Driven";
BA_ "SignalType" SG_ 1265 WhlDistPrRevNDrvn "UNM";
BA_ "VNSigAllNodes" SG_ 1265 WhlDistPrRevDrvn 1;
BA_ "SignalLongName" SG_ 1265 WhlDistPrRevDrvn "Wheel Distance Per Revolution Driven";
BA_ "SignalType" SG_ 1265 WhlDistPrRevDrvn "UNM";
BA_ "VNSigAllNodes" SG_ 1265 DrvlnFnlAxleRatio 1;
BA_ "SignalLongName" SG_ 1265 DrvlnFnlAxleRatio "Driveline Final Axle Ratio";
BA_ "SignalType" SG_ 1265 DrvlnFnlAxleRatio "UNM";
